VERSION ""

NS_ :

BS_:

BU_: DSAU vHS_M SHVU_RR DPSS AMP ICC RLPSM APSM RWPC RRHV RRPSM CGW_CCU APSS ATS RLHV FPM RDC PSM ASAU

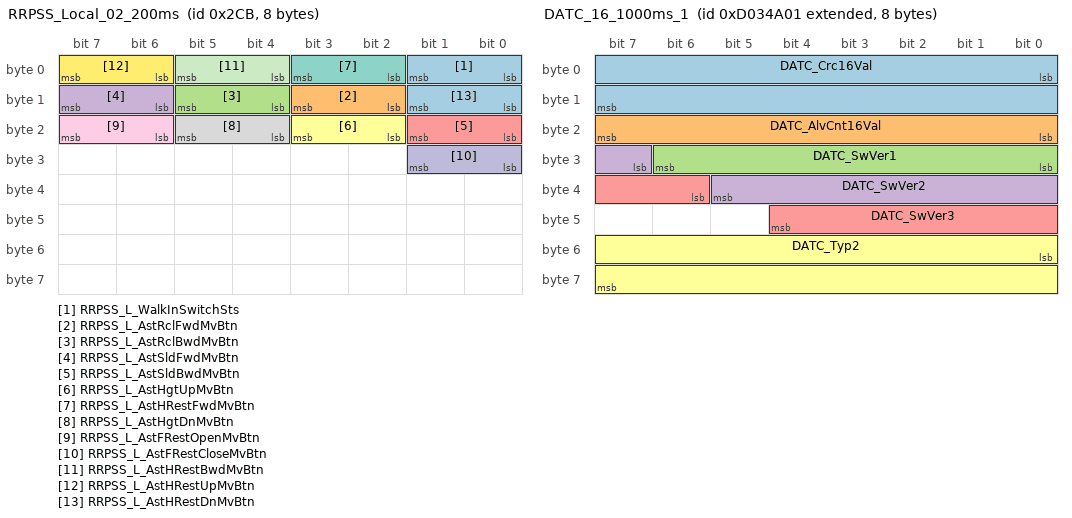
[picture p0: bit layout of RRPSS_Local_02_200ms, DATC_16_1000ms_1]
BO_ 715 RRPSS_Local_02_200ms: 8 RLPSM
 SG_ RRPSS_L_WalkInSwitchSts : 0|2@1+ (1,0) [0|0] ""  APSM
 SG_ RRPSS_L_AstRclFwdMvBtn : 10|2@1+ (1,0) [0|0] ""  APSM
 SG_ RRPSS_L_AstRclBwdMvBtn : 12|2@1+ (1,0) [0|0] ""  APSM
 SG_ RRPSS_L_AstSldFwdMvBtn : 14|2@1+ (1,0) [0|0] ""  APSM
 SG_ RRPSS_L_AstSldBwdMvBtn : 16|2@1+ (1,0) [0|0] ""  APSM
 SG_ RRPSS_L_AstHgtUpMvBtn : 18|2@1+ (1,0) [0|0] ""  APSM
 SG_ RRPSS_L_AstHRestFwdMvBtn : 2|2@1+ (1,0) [0|0] ""  APSM
 SG_ RRPSS_L_AstHgtDnMvBtn : 20|2@1+ (1,0) [0|0] ""  APSM
 SG_ RRPSS_L_AstFRestOpenMvBtn : 22|2@1+ (1,0) [0|0] ""  APSM
 SG_ RRPSS_L_AstFRestCloseMvBtn : 24|2@1+ (1,0) [0|0] ""  APSM
 SG_ RRPSS_L_AstHRestBwdMvBtn : 4|2@1+ (1,0) [0|0] ""  APSM
 SG_ RRPSS_L_AstHRestUpMvBtn : 6|2@1+ (1,0) [0|0] ""  APSM
 SG_ RRPSS_L_AstHRestDnMvBtn : 8|2@1+ (1,0) [0|0] ""  APSM

BO_ 2470762497 HU_GW_PE_01_1: 8 CGW_CCU
 SG_ HU_DistanceUnit : 0|2@1+ (1,0) [0|0] ""  Vector__XXX
 SG_ HU_ThemeType : 10|6@1+ (1,0) [0|0] ""  ATS
 SG_ HU_MicActivity : 17|2@1+ (1,0) [0|0] ""  Vector__XXX
 SG_ HU_Scheduled_Setting : 2|4@1+ (1,0) [0|0] ""  Vector__XXX
 SG_ AVN_RSPA_ModeSelect : 20|4@1+ (1,0) [0|0] ""  Vector__XXX
 SG_ CF_HU_GPSFlt : 24|2@1+ (1,0) [0|0] ""  Vector__XXX
 SG_ AVN_RSPA_CancelInput : 26|2@1+ (1,0) [0|3] ""  Vector__XXX
 SG_ AVN_RSPA_ModeSetStat : 28|4@1+ (1,0) [0|0] ""  Vector__XXX
 SG_ CAM_Request : 33|3@1+ (1,0) [0|0] ""  Vector__XXX
 SG_ HU_TempUnit : 36|2@1+ (1,0) [0|0] ""  Vector__XXX
 SG_ AVN_RSPA_Disp_Rdy : 38|2@1+ (1,0) [0|0] ""  Vector__XXX
 SG_ CF_AVN_ProfileIDRValue : 40|4@1+ (1,0) [0|0] ""  RWPC,PSM
 SG_ HazardFromHUSVM : 44|2@1+ (1,0) [0|0] ""  Vector__XXX
 SG_ OMUOSMirCtrl : 46|2@1+ (1,0) [0|0] ""  Vector__XXX
 SG_ AVN_PDW_Input : 49|2@1+ (1,0) [0|3] ""  Vector__XXX
 SG_ AVN_RSPA_Input : 51|2@1+ (1,0) [0|3] ""  Vector__XXX
 SG_ AVN_ParkingSW : 53|3@1+ (1,0) [0|0] ""  Vector__XXX
 SG_ OTAUIStatus : 56|2@1+ (1,0) [0|0] ""  Vector__XXX
 SG_ C_TeleActiveStatus : 58|2@1+ (1,0) [0|0] ""  Vector__XXX
 SG_ HU_AliveStatus : 6|2@1+ (1,0) [0|0] ""  DSAU
 SG_ C_MtnAlertClu : 60|2@1+ (1,0) [0|0] ""  Vector__XXX
 SG_ HU_RTCCheck : 62|2@1+ (1,0) [0|0] ""  Vector__XXX
 SG_ C_SMKBindRequest : 8|2@1+ (1,0) [0|0] ""  Vector__XXX

BO_ 2458167297 HU_USM_E_01_1: 8 CGW_CCU
 SG_ CF_AVN_FCANValueSet : 0|3@1+ (1,0) [0|0] ""  Vector__XXX
 SG_ CF_AVN_DAWModeNValueSet : 11|3@1+ (1,0) [0|0] ""  Vector__XXX
 SG_ CF_AVN_HDANValueSet : 14|2@1+ (1,0) [0|0] ""  Vector__XXX
 SG_ CF_AVN_BCWNValueSet : 16|2@1+ (1,0) [0|0] ""  Vector__XXX
 SG_ CF_AVN_NSCCCamNValueSet : 20|2@1+ (1,0) [0|0] ""  Vector__XXX
 SG_ CF_AVN_ProximitySesnsorSet : 22|2@1+ (1,0) [0|0] ""  Vector__XXX
 SG_ CF_AVN_BCANValueSet : 24|3@1+ (1,0) [0|0] ""  Vector__XXX
 SG_ CF_AVN_ISLWNValueSet : 27|2@1+ (1,0) [0|0] ""  Vector__XXX
 SG_ CF_AVN_WarningTimingNValueSet : 29|3@1+ (1,0) [0|0] ""  ICC
 SG_ CF_AVN_LFANValueSet : 3|2@1+ (1,0) [0|0] ""  Vector__XXX
 SG_ CF_AVN_NCC_USM_set : 32|2@1+ (1,0) [0|0] ""  Vector__XXX
 SG_ CF_AVN_TirePressUnitNValueSet : 34|3@1+ (1,0) [0|0] ""  Vector__XXX
 SG_ CF_AVN_PCANValueSet : 37|3@1+ (1,0) [0|0] ""  Vector__XXX
 SG_ CF_AVN_TunnelClimateNvalueSet : 40|2@1+ (1,0) [0|0] ""  Vector__XXX
 SG_ CF_AVN_NSCCCrvNValueSet : 42|2@1+ (1,0) [0|0] ""  Vector__XXX
 SG_ CF_AVN_BCWSndWanNValueSet : 44|2@1+ (1,0) [0|0] ""  Vector__XXX
 SG_ CF_AVN_RCCWNValueSet : 46|2@1+ (1,0) [0|0] ""  Vector__XXX
 SG_ CF_AVN_LkaModeNValueSet : 49|3@1+ (1,0) [0|0] ""  Vector__XXX
 SG_ CF_AVN_PasSpkrLvNValueSet : 5|3@1+ (1,0) [0|0] ""  Vector__XXX
 SG_ CF_AVN_PDWAutoOnNValueSet : 52|2@1+ (1,0) [0|0] ""  Vector__XXX
 SG_ C_TempUnit : 59|2@1+ (1,0) [0|0] ""  Vector__XXX
 SG_ CF_AVN_AdasVolumeNValueSet : 61|3@1+ (1,0) [0|0] ""  Vector__XXX
 SG_ CF_AVN_SCCDrvModeNValueSet : 8|3@1+ (1,0) [0|0] ""  Vector__XXX

BO_ 2365803012 DATC_16_1000ms_4: 8 CGW_CCU

BO_ 2365803011 DATC_16_1000ms_3: 8 CGW_CCU

BO_ 2365803010 DATC_16_1000ms_2: 8 CGW_CCU

BO_ 2563126017 HU_AMP_E_04_1: 8 CGW_CCU
 SG_ AMP_EngASDMasterGain : 0|5@1+ (0.5,-8) [-6|6] ""  AMP
 SG_ AMP_Beep1Frequency : 8|16@1+ (1,0) [0|0] "Hz"  AMP

BO_ 2365803009 DATC_16_1000ms_1: 8 CGW_CCU
 SG_ DATC_Crc16Val : 0|16@1+ (1,0) [0|0] ""  Vector__XXX
 SG_ DATC_AlvCnt16Val : 16|8@1+ (1,0) [0|0] ""  Vector__XXX
 SG_ DATC_SwVer1 : 24|7@1+ (1,0) [0|0] ""  Vector__XXX
 SG_ DATC_SwVer2 : 31|7@1+ (1,0) [0|0] ""  Vector__XXX
 SG_ DATC_SwVer3 : 38|7@1+ (1,0) [0|0] ""  Vector__XXX
 SG_ DATC_Typ2 : 48|16@1+ (1,0) [0|0] ""  ATS

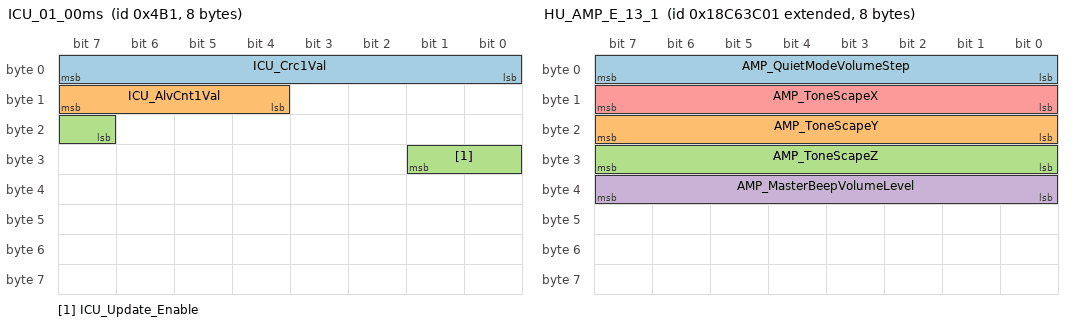
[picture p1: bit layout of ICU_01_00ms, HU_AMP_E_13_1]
BO_ 1201 ICU_01_00ms: 8 CGW_CCU
 SG_ ICU_Crc1Val : 0|8@1+ (1,0) [0|0] ""  vHS_M
 SG_ ICU_AlvCnt1Val : 12|4@1+ (1,0) [0|0] ""  Vector__XXX
 SG_ ICU_Update_Enable : 23|3@1+ (1,0) [0|0] ""  Vector__XXX

BO_ 2563128321 HU_AMP_E_13_1: 8 CGW_CCU
 SG_ AMP_QuietModeVolumeStep : 0|8@1+ (1,0) [0|0] ""  Vector__XXX
 SG_ AMP_ToneScapeY : 16|8@1+ (1,0) [0|0] ""  AMP
 SG_ AMP_ToneScapeZ : 24|8@1+ (1,0) [0|0] ""  AMP
 SG_ AMP_MasterBeepVolumeLevel : 32|8@1+ (1,0) [0|0] ""  AMP
 SG_ AMP_ToneScapeX : 8|8@1+ (1,0) [0|0] ""  AMP

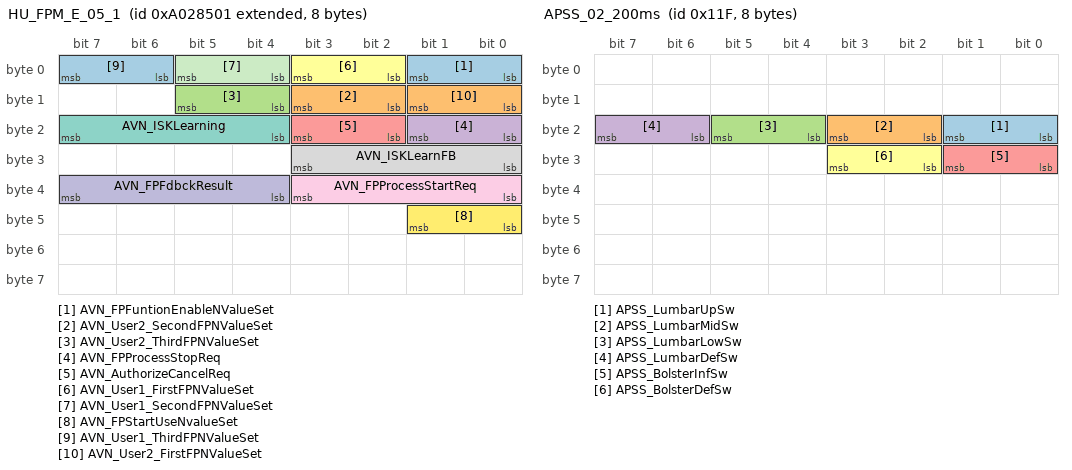
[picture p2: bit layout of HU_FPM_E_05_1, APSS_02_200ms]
BO_ 2315420929 HU_FPM_E_05_1: 8 CGW_CCU
 SG_ AVN_FPFuntionEnableNValueSet : 0|2@1+ (1,0) [0|0] ""  FPM
 SG_ AVN_User2_SecondFPNValueSet : 10|2@1+ (1,0) [0|0] ""  FPM
 SG_ AVN_User2_ThirdFPNValueSet : 12|2@1+ (1,0) [0|0] ""  FPM
 SG_ AVN_FPProcessStopReq : 16|2@1+ (1,0) [0|0] ""  FPM
 SG_ AVN_AuthorizeCancelReq : 18|2@1+ (1,0) [0|0] ""  FPM
 SG_ AVN_User1_FirstFPNValueSet : 2|2@1+ (1,0) [0|0] ""  FPM
 SG_ AVN_ISKLearning : 20|4@1+ (1,0) [0|0] ""  FPM
 SG_ AVN_ISKLearnFB : 24|4@1+ (1,0) [0|0] ""  FPM
 SG_ AVN_FPProcessStartReq : 32|4@1+ (1,0) [0|0] ""  FPM
 SG_ AVN_FPFdbckResult : 36|4@1+ (1,0) [0|0] ""  FPM
 SG_ AVN_User1_SecondFPNValueSet : 4|2@1+ (1,0) [0|0] ""  FPM
 SG_ AVN_FPStartUseNvalueSet : 40|2@1+ (1,0) [0|0] ""  FPM
 SG_ AVN_User1_ThirdFPNValueSet : 6|2@1+ (1,0) [0|0] ""  FPM
 SG_ AVN_User2_FirstFPNValueSet : 8|2@1+ (1,0) [0|0] ""  FPM

BO_ 2470762241 HU_Car_PE_01_1: 8 CGW_CCU
 SG_ HU_VehiclePwr : 4|4@1+ (1,0) [0|0] ""  AMP
 SG_ HU_BtnShowReq : 8|3@1+ (1,0) [0|0] ""  Vector__XXX

BO_ 287 APSS_02_200ms: 8 APSS
 SG_ APSS_LumbarUpSw : 16|2@1+ (1,0) [0|0] ""  ASAU,CGW_CCU
 SG_ APSS_LumbarMidSw : 18|2@1+ (1,0) [0|0] ""  ASAU,CGW_CCU
 SG_ APSS_LumbarLowSw : 20|2@1+ (1,0) [0|0] ""  ASAU,CGW_CCU
 SG_ APSS_LumbarDefSw : 22|2@1+ (1,0) [0|0] ""  ASAU,CGW_CCU
 SG_ APSS_BolsterInfSw : 24|2@1+ (1,0) [0|0] ""  ASAU,CGW_CCU
 SG_ APSS_BolsterDefSw : 26|2@1+ (1,0) [0|0] ""  ASAU,CGW_CCU

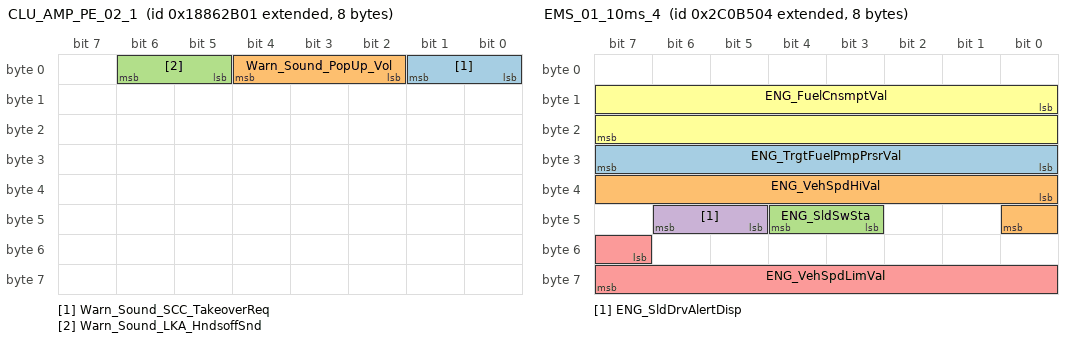
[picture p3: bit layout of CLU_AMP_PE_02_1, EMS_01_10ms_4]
BO_ 2558929665 CLU_AMP_PE_02_1: 8 CGW_CCU
 SG_ Warn_Sound_SCC_TakeoverReq : 0|2@1+ (1,0) [0|0] ""  AMP
 SG_ Warn_Sound_PopUp_Vol : 2|3@1+ (1,0) [0|0] ""  AMP
 SG_ Warn_Sound_LKA_HndsoffSnd : 5|2@1+ (1,0) [0|0] ""  AMP

BO_ 2193667332 EMS_01_10ms_4: 8 CGW_CCU
 SG_ ENG_TrgtFuelPmpPrsrVal : 24|8@1+ (3.137254902,0) [0|0] "kPa"  Vector__XXX
 SG_ ENG_VehSpdHiVal : 32|9@1+ (1,0) [0|0] "km/h"  AMP
 SG_ ENG_SldSwSta : 43|2@1+ (1,0) [0|0] ""  Vector__XXX
 SG_ ENG_SldDrvAlertDisp : 45|2@1+ (1,0) [0|0] ""  Vector__XXX
 SG_ ENG_VehSpdLimVal : 55|9@1+ (1,0) [0|0] "km/h"  Vector__XXX
 SG_ ENG_FuelCnsmptVal : 8|16@1+ (0.128,0) [0|0] "ul"  Vector__XXX

BO_ 2193667331 EMS_01_10ms_3: 8 CGW_CCU
 SG_ ENG_TrgtIdleRpmVal : 0|8@1+ (10,0) [0|0] "rpm"  Vector__XXX
 SG_ ENG_GearShftDnDis : 10|2@1+ (1,0) [0|0] ""  Vector__XXX
 SG_ ENG_DsrGearPosDis : 12|4@1+ (1,0) [0|0] ""  Vector__XXX
 SG_ ENG_SldFuncSta : 16|2@1+ (1,0) [0|0] ""  Vector__XXX
 SG_ ENG_SldActnSta : 18|2@1+ (1,0) [0|0] ""  Vector__XXX
 SG_ ENG_FuelTnkPrsrSta : 20|2@1+ (1,0) [0|0] ""  Vector__XXX
 SG_ ENG_IsgBzrReq : 22|2@1+ (1,0) [0|0] ""  Vector__XXX
 SG_ ENG_IsgFuelCnsmptDis : 24|2@1+ (1,0) [0|0] ""  Vector__XXX
 SG_ ENG_FuelCapOpnSta : 26|2@1+ (1,0) [0|0] ""  Vector__XXX
 SG_ ENG_EcoDrvActvSta : 28|2@1+ (1,0) [0|0] ""  Vector__XXX
 SG_ ENG_EngRunSta : 30|2@1+ (1,0) [0|0] ""  Vector__XXX
 SG_ ENG_Isg2Sta : 32|2@1+ (2,0) [0|0] ""  Vector__XXX
 SG_ ENG_IgnOnSta : 34|2@1+ (1,0) [0|0] ""  Vector__XXX
 SG_ ENG_Ack4TcsSta : 36|2@1+ (1,0) [0|0] ""  Vector__XXX
 SG_ ENG_FuelCutOffSta : 38|2@1+ (1,0) [0|0] ""  Vector__XXX
 SG_ ENG_CrctTqSta : 40|2@1+ (1,0) [0|0] ""  Vector__XXX
 SG_ ENG_AirCompRlySta : 42|2@1+ (1,0) [0|0] ""  Vector__XXX
 SG_ ENG_LnchCntrlSta : 45|3@1+ (1,0) [0|0] ""  Vector__XXX
 SG_ ENG_EngSpdVal : 48|16@1+ (0.25,0) [0|0] "rpm"  AMP
 SG_ ENG_GearShftUpDis : 8|2@1+ (1,0) [0|0] ""  Vector__XXX

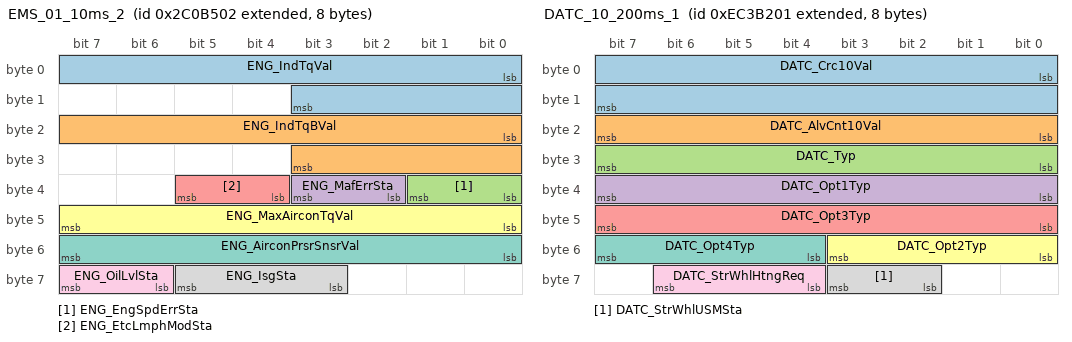
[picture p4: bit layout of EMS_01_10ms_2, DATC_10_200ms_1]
BO_ 2193667330 EMS_01_10ms_2: 8 CGW_CCU
 SG_ ENG_IndTqVal : 0|12@1- (1,0) [0|0] "Nm"  AMP
 SG_ ENG_IndTqBVal : 16|12@1- (1,0) [0|0] "Nm"  Vector__XXX
 SG_ ENG_EngSpdErrSta : 32|2@1+ (1,0) [0|0] ""  Vector__XXX
 SG_ ENG_MafErrSta : 34|2@1+ (1,0) [0|0] ""  Vector__XXX
 SG_ ENG_EtcLmphModSta : 36|2@1+ (1,0) [0|0] ""  Vector__XXX
 SG_ ENG_MaxAirconTqVal : 40|8@1+ (0.2,0) [0|0] "Nm"  Vector__XXX
 SG_ ENG_AirconPrsrSnsrVal : 48|8@1+ (125,0) [0|0] "hPa"  Vector__XXX
 SG_ ENG_IsgSta : 59|3@1+ (1,0) [0|0] ""  PSM,APSM,RLPSM,RRPSM,RLHV,RRHV,SHVU_RR,DPSS
 SG_ ENG_OilLvlSta : 62|2@1+ (1,0) [0|0] ""  Vector__XXX

BO_ 2395189761 DATC_10_200ms_1: 8 CGW_CCU
 SG_ DATC_Crc10Val : 0|16@1+ (1,0) [0|0] ""  Vector__XXX
 SG_ DATC_AlvCnt10Val : 16|8@1+ (1,0) [0|0] ""  Vector__XXX
 SG_ DATC_Typ : 24|8@1+ (1,0) [0|0] ""  RLHV,RRHV,AMP,ATS
 SG_ DATC_Opt1Typ : 32|8@1+ (1,0) [0|0] ""  ATS
 SG_ DATC_Opt3Typ : 40|8@1+ (1,0) [0|0] ""  ATS
 SG_ DATC_Opt2Typ : 48|4@1+ (1,0) [0|0] ""  ATS
 SG_ DATC_Opt4Typ : 52|4@1+ (1,0) [0|0] ""  ATS
 SG_ DATC_StrWhlUSMSta : 58|2@1+ (1,0) [0|0] ""  SHVU_RR
 SG_ DATC_StrWhlHtngReq : 60|3@1+ (1,0) [0|0] ""  Vector__XXX

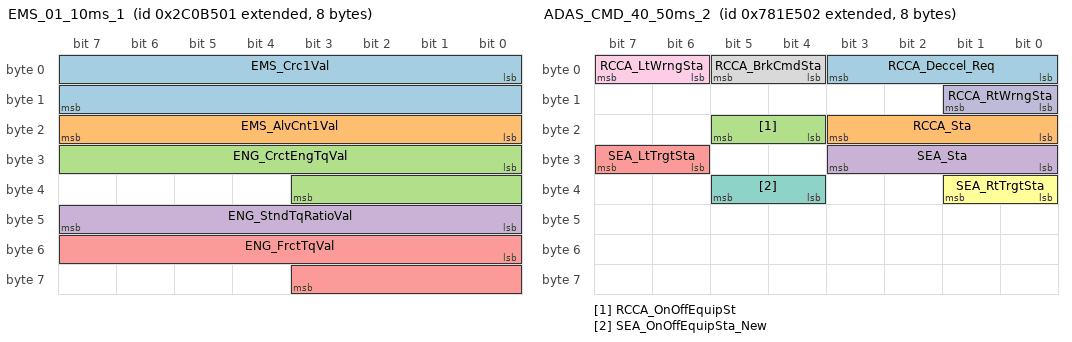
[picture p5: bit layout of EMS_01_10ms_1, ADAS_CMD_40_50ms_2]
BO_ 2193667329 EMS_01_10ms_1: 8 CGW_CCU
 SG_ EMS_Crc1Val : 0|16@1+ (1,0) [0|0] ""  Vector__XXX
 SG_ EMS_AlvCnt1Val : 16|8@1+ (1,0) [0|0] ""  Vector__XXX
 SG_ ENG_CrctEngTqVal : 24|12@1- (1,0) [0|0] "Nm"  Vector__XXX
 SG_ ENG_StndTqRatioVal : 40|8@1+ (0.0078,0) [0|0] ""  Vector__XXX
 SG_ ENG_FrctTqVal : 48|12@1- (1,0) [0|0] "Nm"  Vector__XXX

BO_ 2273436930 ADAS_CMD_40_50ms_2: 8 CGW_CCU
 SG_ RCCA_Deccel_Req : 0|4@1+ (0.04,0) [0|0] "g"  Vector__XXX
 SG_ RCCA_Sta : 16|4@1+ (1,0) [0|0] ""  Vector__XXX
 SG_ RCCA_OnOffEquipSt : 20|2@1+ (1,0) [0|0] ""  Vector__XXX
 SG_ SEA_Sta : 24|4@1+ (1,0) [0|0] ""  Vector__XXX
 SG_ SEA_LtTrgtSta : 30|2@1+ (1,0) [0|0] ""  AMP
 SG_ SEA_RtTrgtSta : 32|2@1+ (1,0) [0|0] ""  AMP
 SG_ SEA_OnOffEquipSta_New : 36|2@1+ (1,0) [0|0] ""  Vector__XXX
 SG_ RCCA_BrkCmdSta : 4|2@1+ (1,0) [0|0] ""  Vector__XXX
 SG_ RCCA_LtWrngSta : 6|2@1+ (1,0) [0|0] ""  Vector__XXX
 SG_ RCCA_RtWrngSta : 8|2@1+ (1,0) [0|0] ""  Vector__XXX

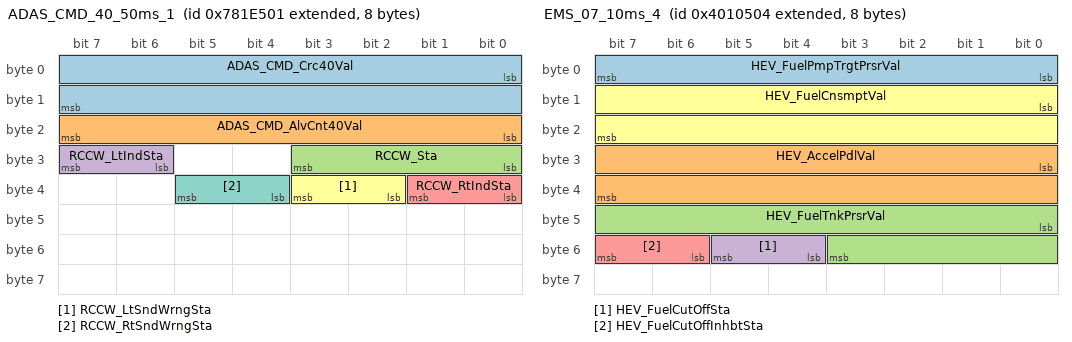
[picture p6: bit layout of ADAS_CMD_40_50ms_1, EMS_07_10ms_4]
BO_ 2273436929 ADAS_CMD_40_50ms_1: 8 CGW_CCU
 SG_ ADAS_CMD_Crc40Val : 0|16@1+ (1,0) [0|0] ""  Vector__XXX
 SG_ ADAS_CMD_AlvCnt40Val : 16|8@1+ (1,0) [0|0] ""  Vector__XXX
 SG_ RCCW_Sta : 24|4@1+ (1,0) [0|0] ""  Vector__XXX
 SG_ RCCW_LtIndSta : 30|2@1+ (1,0) [0|0] ""  Vector__XXX
 SG_ RCCW_RtIndSta : 32|2@1+ (1,0) [0|0] ""  Vector__XXX
 SG_ RCCW_LtSndWrngSta : 34|2@1+ (1,0) [0|0] ""  AMP
 SG_ RCCW_RtSndWrngSta : 36|2@1+ (1,0) [0|0] ""  AMP

BO_ 2214659332 EMS_07_10ms_4: 8 CGW_CCU
 SG_ HEV_FuelPmpTrgtPrsrVal : 0|8@1+ (3.137254902,0) [0|0] "kPa"  Vector__XXX
 SG_ HEV_AccelPdlVal : 24|16@1+ (0.3906,0) [0|0] "%"  Vector__XXX
 SG_ HEV_FuelTnkPrsrVal : 40|12@1+ (0.17094,-200) [0|0] "hPa"  Vector__XXX
 SG_ HEV_FuelCutOffSta : 52|2@1+ (1,0) [0|0] ""  Vector__XXX
 SG_ HEV_FuelCutOffInhbtSta : 54|2@1+ (1,0) [0|0] ""  Vector__XXX
 SG_ HEV_FuelCnsmptVal : 8|16@1+ (0.128,0) [0|0] "ul"  Vector__XXX

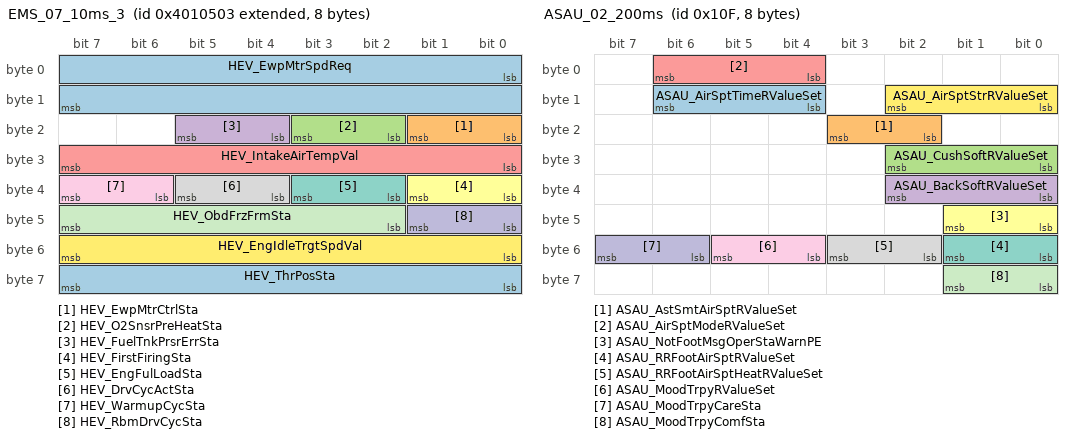
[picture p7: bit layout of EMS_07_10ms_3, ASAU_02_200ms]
BO_ 2214659331 EMS_07_10ms_3: 8 CGW_CCU
 SG_ HEV_EwpMtrSpdReq : 0|16@1+ (1,0) [0|0] "rpm"  Vector__XXX
 SG_ HEV_EwpMtrCtrlSta : 16|2@1+ (1,0) [0|0] ""  Vector__XXX
 SG_ HEV_O2SnsrPreHeatSta : 18|2@1+ (1,0) [0|0] ""  Vector__XXX
 SG_ HEV_FuelTnkPrsrErrSta : 20|2@1+ (1,0) [0|0] ""  Vector__XXX
 SG_ HEV_IntakeAirTempVal : 24|8@1+ (0.75,-48) [0|0] "℃"  Vector__XXX
 SG_ HEV_FirstFiringSta : 32|2@1+ (1,0) [0|0] ""  Vector__XXX
 SG_ HEV_EngFulLoadSta : 34|2@1+ (1,0) [0|0] ""  Vector__XXX
 SG_ HEV_DrvCycActSta : 36|2@1+ (1,0) [0|0] ""  Vector__XXX
 SG_ HEV_WarmupCycSta : 38|2@1+ (1,0) [0|0] ""  Vector__XXX
 SG_ HEV_RbmDrvCycSta : 40|2@1+ (1,0) [0|0] ""  Vector__XXX
 SG_ HEV_ObdFrzFrmSta : 42|6@1+ (1,0) [0|0] ""  Vector__XXX
 SG_ HEV_EngIdleTrgtSpdVal : 48|8@1+ (10,0) [0|0] "rpm"  Vector__XXX
 SG_ HEV_ThrPosSta : 56|8@1+ (0.4694835681,-15.0234741784) [0|0] "%"  Vector__XXX

BO_ 271 ASAU_02_200ms: 8 ASAU
 SG_ ASAU_AirSptTimeRValueSet : 12|3@1+ (1,0) [0|0] ""  CGW_CCU
 SG_ ASAU_AstSmtAirSptRValueSet : 18|2@1+ (1,0) [0|0] ""  CGW_CCU
 SG_ ASAU_CushSoftRValueSet : 24|3@1+ (1,0) [0|0] ""  CGW_CCU
 SG_ ASAU_BackSoftRValueSet : 32|3@1+ (1,0) [0|0] ""  CGW_CCU
 SG_ ASAU_AirSptModeRValueSet : 4|3@1+ (1,0) [0|0] ""  CGW_CCU
 SG_ ASAU_NotFootMsgOperStaWarnPE : 40|2@1+ (1,0) [0|0] ""  ATS
 SG_ ASAU_RRFootAirSptRValueSet : 48|2@1+ (1,0) [0|0] ""  APSM,ATS,CGW_CCU
 SG_ ASAU_RRFootAirSptHeatRValueSet : 50|2@1+ (1,0) [0|0] ""  APSM,ATS
 SG_ ASAU_MoodTrpyRValueSet : 52|2@1+ (1,0) [0|0] ""  CGW_CCU
 SG_ ASAU_MoodTrpyCareSta : 54|2@1+ (1,0) [0|0] ""  CGW_CCU
 SG_ ASAU_MoodTrpyComfSta : 56|2@1+ (1,0) [0|0] ""  CGW_CCU
 SG_ ASAU_AirSptStrRValueSet : 8|3@1+ (1,0) [0|0] ""  CGW_CCU

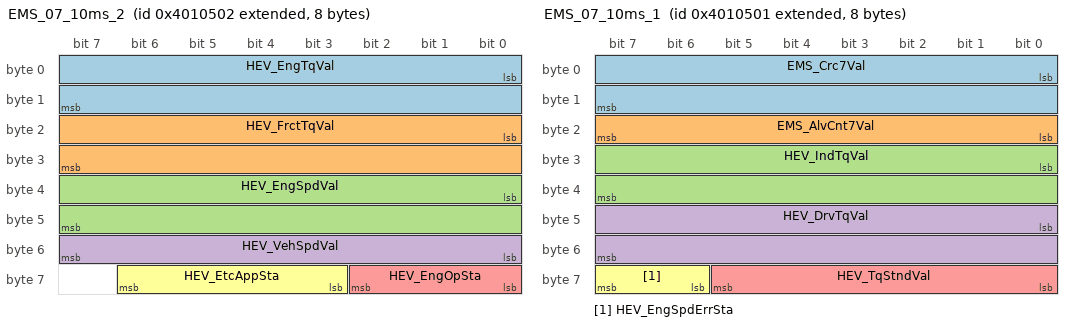
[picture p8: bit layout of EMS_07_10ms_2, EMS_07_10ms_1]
BO_ 2214659330 EMS_07_10ms_2: 8 CGW_CCU
 SG_ HEV_EngTqVal : 0|16@1+ (0.3906,0) [0|0] "%"  Vector__XXX
 SG_ HEV_FrctTqVal : 16|16@1+ (0.3906,0) [0|0] "%"  Vector__XXX
 SG_ HEV_EngSpdVal : 32|16@1+ (0.25,0) [0|0] "rpm"  Vector__XXX
 SG_ HEV_VehSpdVal : 48|8@1+ (1,0) [0|0] "km/h"  Vector__XXX
 SG_ HEV_EngOpSta : 56|3@1+ (1,0) [0|0] ""  SHVU_RR
 SG_ HEV_EtcAppSta : 59|4@1+ (1,0) [0|0] ""  Vector__XXX

BO_ 2214659329 EMS_07_10ms_1: 8 CGW_CCU
 SG_ EMS_Crc7Val : 0|16@1+ (1,0) [0|0] ""  Vector__XXX
 SG_ EMS_AlvCnt7Val : 16|8@1+ (1,0) [0|0] ""  Vector__XXX
 SG_ HEV_IndTqVal : 24|16@1+ (0.3906,0) [0|0] "%"  Vector__XXX
 SG_ HEV_DrvTqVal : 40|16@1+ (0.390625,0) [0|0] "%"  Vector__XXX
 SG_ HEV_TqStndVal : 56|6@1+ (10,0) [0|0] "Nm"  Vector__XXX
 SG_ HEV_EngSpdErrSta : 62|2@1+ (1,0) [0|0] ""  Vector__XXX

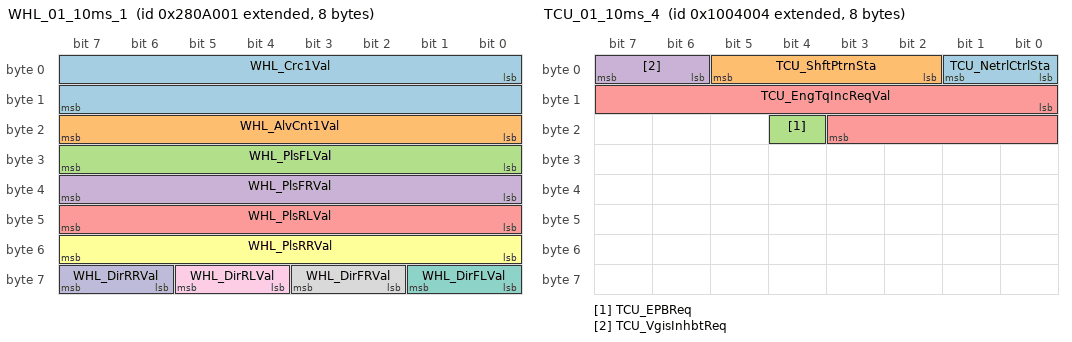
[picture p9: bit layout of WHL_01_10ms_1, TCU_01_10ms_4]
BO_ 2189467649 WHL_01_10ms_1: 8 CGW_CCU
 SG_ WHL_Crc1Val : 0|16@1+ (1,0) [0|0] ""  Vector__XXX
 SG_ WHL_AlvCnt1Val : 16|8@1+ (1,0) [0|0] ""  Vector__XXX
 SG_ WHL_PlsFLVal : 24|8@1+ (0.5,0) [0|0] "pulse count"  Vector__XXX
 SG_ WHL_PlsFRVal : 32|8@1+ (0.5,0) [0|0] "pulse count"  Vector__XXX
 SG_ WHL_PlsRLVal : 40|8@1+ (0.5,0) [0|0] "pulse count"  Vector__XXX
 SG_ WHL_PlsRRVal : 48|8@1+ (0.5,0) [0|0] "pulse count"  Vector__XXX
 SG_ WHL_DirFLVal : 56|2@1+ (1,0) [0|0] ""  Vector__XXX
 SG_ WHL_DirFRVal : 58|2@1+ (1,0) [0|0] ""  Vector__XXX
 SG_ WHL_DirRLVal : 60|2@1+ (1,0) [0|0] ""  Vector__XXX
 SG_ WHL_DirRRVal : 62|2@1+ (1,0) [0|0] ""  Vector__XXX

BO_ 2164277252 TCU_01_10ms_4: 8 CGW_CCU
 SG_ TCU_NetrlCtrlSta : 0|2@1+ (1,0) [0|0] ""  Vector__XXX
 SG_ TCU_ShftPtrnSta : 2|4@1+ (1,0) [0|0] ""  Vector__XXX
 SG_ TCU_EPBReq : 20|1@1+ (1,0) [0|0] ""  Vector__XXX
 SG_ TCU_VgisInhbtReq : 6|2@1+ (1,0) [0|0] ""  Vector__XXX
 SG_ TCU_EngTqIncReqVal : 8|12@1- (1,0) [0|0] "Nm"  Vector__XXX

BO_ 2411985665 HU_MOOD_E_01_1: 8 CGW_CCU
 SG_ HU_MoodTherapyDrSeat : 0|2@1+ (1,0) [0|0] ""  DSAU
 SG_ HU_VitalityFragrance : 10|2@1+ (1,0) [0|0] ""  Vector__XXX
 SG_ HU_VitalityCurtain : 12|2@1+ (1,0) [0|0] ""  RDC
 SG_ HU_DelightMoodLamp : 14|2@1+ (1,0) [0|0] ""  Vector__XXX
 SG_ HU_DelightFragrance : 16|2@1+ (1,0) [0|0] ""  Vector__XXX
 SG_ HU_DelightCurtain : 18|2@1+ (1,0) [0|0] ""  RDC
 SG_ HU_MoodTherapyPsSeat : 2|2@1+ (1,0) [0|0] ""  ASAU
 SG_ HU_CareMoodLamp : 20|2@1+ (1,0) [0|0] ""  Vector__XXX
 SG_ HU_CareFragrance : 22|2@1+ (1,0) [0|0] ""  Vector__XXX
 SG_ HU_CareMassage : 24|2@1+ (1,0) [0|0] ""  RLPSM,DSAU,ASAU
 SG_ HU_CareCurtain : 26|2@1+ (1,0) [0|0] ""  RDC
 SG_ HU_ComfortMoodLamp : 28|2@1+ (1,0) [0|0] ""  Vector__XXX
 SG_ HU_ComfortFragrance : 30|2@1+ (1,0) [0|0] ""  Vector__XXX
 SG_ HU_ComfortMassage : 32|2@1+ (1,0) [0|0] ""  RLPSM,DSAU,ASAU
 SG_ HU_ComfortCurtain : 34|2@1+ (1,0) [0|0] ""  RDC
 SG_ HU_MoodTherapyMode : 36|3@1+ (1,0) [0|0] ""  RLPSM,RDC,DSAU,ASAU
 SG_ HU_MoodTherapyRlSeat : 4|2@1+ (1,0) [0|0] ""  RLPSM
 SG_ HU_MoodTherapyRrSeat : 6|2@1+ (1,0) [0|0] ""  RLPSM
 SG_ HU_VitalityMoodLamp : 8|2@1+ (1,0) [0|0] ""  Vector__XXX

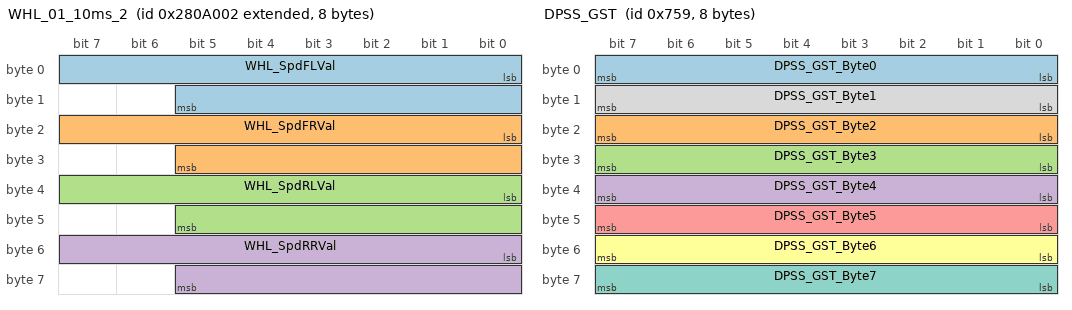
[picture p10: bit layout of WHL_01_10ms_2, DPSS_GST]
BO_ 2189467650 WHL_01_10ms_2: 8 CGW_CCU
 SG_ WHL_SpdFLVal : 0|14@1+ (0.03125,0) [0|0] "km^h"  AMP
 SG_ WHL_SpdFRVal : 16|14@1+ (0.03125,0) [0|0] "km^h"  AMP
 SG_ WHL_SpdRLVal : 32|14@1+ (0.03125,0) [0|0] "km^h"  Vector__XXX
 SG_ WHL_SpdRRVal : 48|14@1+ (0.03125,0) [0|0] "km^h"  Vector__XXX

BO_ 1881 DPSS_GST: 8 DPSS
 SG_ DPSS_GST_Byte0 : 0|8@1+ (1,0) [0|0] ""  CGW_CCU
 SG_ DPSS_GST_Byte2 : 16|8@1+ (1,0) [0|0] ""  CGW_CCU
 SG_ DPSS_GST_Byte3 : 24|8@1+ (1,0) [0|0] ""  CGW_CCU
 SG_ DPSS_GST_Byte4 : 32|8@1+ (1,0) [0|0] ""  CGW_CCU
 SG_ DPSS_GST_Byte5 : 40|8@1+ (1,0) [0|0] ""  CGW_CCU
 SG_ DPSS_GST_Byte6 : 48|8@1+ (1,0) [0|0] ""  CGW_CCU
 SG_ DPSS_GST_Byte7 : 56|8@1+ (1,0) [0|0] ""  CGW_CCU
 SG_ DPSS_GST_Byte1 : 8|8@1+ (1,0) [0|0] ""  CGW_CCU

BO_ 2189467651 WHL_01_10ms_3: 8 CGW_CCU
 SG_ WHL_SpdCalParmtr : 8|9@1+ (0.5,200) [0|0] "mm"  Vector__XXX

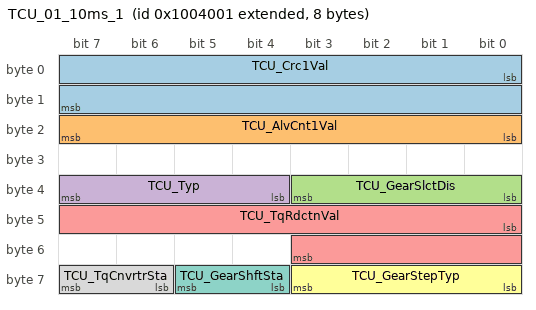
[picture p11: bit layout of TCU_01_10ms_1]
BO_ 2164277249 TCU_01_10ms_1: 8 CGW_CCU
 SG_ TCU_Crc1Val : 0|16@1+ (1,0) [0|0] ""  Vector__XXX
 SG_ TCU_AlvCnt1Val : 16|8@1+ (1,0) [0|0] ""  Vector__XXX
 SG_ TCU_GearSlctDis : 32|4@1+ (1,0) [0|0] ""  AMP,ICC
 SG_ TCU_Typ : 36|4@1+ (1,0) [0|0] ""  AMP
 SG_ TCU_TqRdctnVal : 40|12@1- (1,0) [0|0] "Nm"  AMP
 SG_ TCU_GearStepTyp : 56|4@1+ (1,0) [0|0] ""  Vector__XXX
 SG_ TCU_GearShftSta : 60|2@1+ (1,0) [0|0] ""  Vector__XXX
 SG_ TCU_TqCnvrtrSta : 62|2@1+ (1,0) [0|0] ""  Vector__XXX

BO_TX_BU_ 1881 : DPSS,vHS_M;
CM_ BO_ 2273436929 "[P] Periodic";
CM_ SG_ 2273436929 ADAS_CMD_Crc40Val "ADAS_CMD_CyclicRedundancyCheck40Value";
CM_ SG_ 2273436929 ADAS_CMD_AlvCnt40Val "ADAS_CMD_AliveCounter40Value";
CM_ SG_ 2273436929 RCCW_Sta "RCCW_Status ##2G##BCW - BCW11 - CF_RCCW_Stat";
CM_ SG_ 2273436929 RCCW_LtIndSta "RCCW_LeftIndicatorStatus ##2G##BCW - BCW11 - CF_RCCW_IndLeft";
CM_ SG_ 2273436929 RCCW_RtIndSta "RCCW_RightIndicatorStatus ##2G##BCW - BCW11 - CF_RCCW_IndRight";
CM_ SG_ 2273436929 RCCW_LtSndWrngSta "RCCW_LeftSoundWarningStatus ##2G##BCW - BCW11 - CF_RL_SndWan";
CM_ SG_ 2273436929 RCCW_RtSndWrngSta "RCCW_RightSoundWarningStatus ##2G##BCW - BCW11 - CF_RR_SndWan";
CM_ BO_ 2273436930 "[P] Periodic";
CM_ SG_ 2273436930 RCCA_Deccel_Req "RCCA_Deccel_Requirement ##2G##BCW - BCA11 - CF_RCCA_Decel_Req";
CM_ SG_ 2273436930 RCCA_Sta "RCCA_Status";
CM_ SG_ 2273436930 RCCA_OnOffEquipSt "RCCA_OnOffEquipmentStatus ##2G##BCW - BCW12 - CF_RCCA_USM";
CM_ SG_ 2273436930 SEA_Sta "SEA_Status";
CM_ SG_ 2273436930 SEA_LtTrgtSta "SEA_LeftWarningStatus ##2G##BCW - BCA11 - CF_SEA_Warn_Lh";
CM_ SG_ 2273436930 SEA_RtTrgtSta "SEA_RightWarningStatus ##2G##BCW - BCA11 - CF_SEA_Warn_Rh";
CM_ SG_ 2273436930 SEA_OnOffEquipSta_New "SEA_OnOffEquipmentStatus ##2G##BCW - BCW12 - CF_SEA_USM_NEW";
CM_ SG_ 2273436930 RCCA_BrkCmdSta "RCCA_BrakeCommandStatus ##2G##BCW - BCA11 - RCCA_Brake_Command";
CM_ SG_ 2273436930 RCCA_LtWrngSta "RCCA_LeftWarningStatus ##2G##BCW - BCA11 - CF_RCCA_WarnLh";
CM_ SG_ 2273436930 RCCA_RtWrngSta "RCCA_RightWarningStatus ##2G##BCW - BCA11 - CF_RCCA_WarnRh";
CM_ BO_ 287 "[PE] Periodic and On Event";
CM_ SG_ 287 APSS_LumbarUpSw "APSS_LumbarUpMoveSwitch";
CM_ SG_ 287 APSS_LumbarMidSw "APSS_LumbarMiddleSwitch";
CM_ SG_ 287 APSS_LumbarLowSw "APSS_LumbarLowerSwitch";
CM_ SG_ 287 APSS_LumbarDefSw "APSS_LumbarDeflationSwitch";
CM_ SG_ 287 APSS_BolsterInfSw "APSS_BolsterInflationSwitch";
CM_ SG_ 287 APSS_BolsterDefSw "APSS_BolsterDeflationSwitch";
CM_ BO_ 271 "[PE] Periodic and On Event";
CM_ SG_ 271 ASAU_AirSptTimeRValueSet "Air Support Time(Massage Time) USM R Value";
CM_ SG_ 271 ASAU_AstSmtAirSptRValueSet "Seat Smart Air Support Function USM R Value";
CM_ SG_ 271 ASAU_CushSoftRValueSet "Cushion Soft R Value";
CM_ SG_ 271 ASAU_BackSoftRValueSet "Back Soft USM R Value";
CM_ SG_ 271 ASAU_AirSptModeRValueSet "Air Support Mode(Massage Mode) USM R Value";
CM_ SG_ 271 ASAU_NotFootMsgOperStaWarnPE "Passenger Foot Massage Operation Disable Mode";
CM_ SG_ 271 ASAU_RRFootAirSptRValueSet "Foot Air Support USM R Value";
CM_ SG_ 271 ASAU_RRFootAirSptHeatRValueSet "Foot Air Support Heat USM R Value";
CM_ SG_ 271 ASAU_MoodTrpyRValueSet "Passenger Seat Mood Therapy R Value";
CM_ SG_ 271 ASAU_MoodTrpyCareSta "Passenger Seat Mood Therapy Care Mode R Value";
CM_ SG_ 271 ASAU_MoodTrpyComfSta "Passenger Seat Mood Therapy Comfort Mode R Value";
CM_ SG_ 271 ASAU_AirSptStrRValueSet "Air Support Strenth(Massage Strenth) USM R Value";
CM_ BO_ 2558929665 "[PE] Periodic and On Event";
CM_ SG_ 2558929665 Warn_Sound_SCC_TakeoverReq "This signal is transmitted from cluster to AMP for SCC TAKE OVER REQUSET SOUND";
CM_ SG_ 2558929665 Warn_Sound_PopUp_Vol "This signal is transmitted from cluster to AMP for 11 group cluster sound

0x0:Off
0x1:Red Pop-up(Collision)
0x2:Red Pop-up
0x3:Yellow Pop-up
0x4:White(Alarm) Pop-up
0x5:White(Feedback) Pop-up
0x6:Reserved
0x7:Invalid";
CM_ SG_ 2558929665 Warn_Sound_LKA_HndsoffSnd "This signal is transmitted from cluster to AMP for LKA HANDS OFF SOUND";
CM_ BO_ 2395189761 "[PE] Periodic and On Event";
CM_ SG_ 2395189761 DATC_Crc10Val "DATC_CyclicRedundancyCheck10Value";
CM_ SG_ 2395189761 DATC_AlvCnt10Val "DATC_AliveCounter10Value";
CM_ SG_ 2395189761 DATC_Typ "DATC_Type";
CM_ SG_ 2395189761 DATC_Opt1Typ "DATC_Option1Type";
CM_ SG_ 2395189761 DATC_Opt3Typ "DATC_Option3Type";
CM_ SG_ 2395189761 DATC_Opt2Typ "DATC_Option2Type";
CM_ SG_ 2395189761 DATC_Opt4Typ "HTR CONTROL OPTION";
CM_ SG_ 2395189761 DATC_StrWhlUSMSta "DATC_SteeringWheelUSMState";
CM_ SG_ 2395189761 DATC_StrWhlHtngReq "DATC_SteeringWheelHeatReq";
CM_ BO_ 2365803009 "[P] Periodic";
CM_ SG_ 2365803009 DATC_Crc16Val "DATC_CyclicRedundancyCheck16Value";
CM_ SG_ 2365803009 DATC_AlvCnt16Val "DATC_AliveCounter16Value";
CM_ SG_ 2365803009 DATC_SwVer1 "this signal indicates DATC Software Version to display on H_U";
CM_ SG_ 2365803009 DATC_SwVer2 "This signal indicates DATC software vertion to display on H_U";
CM_ SG_ 2365803009 DATC_Typ2 "DATC_Type2";
CM_ BO_ 2365803010 "[P] Periodic";
CM_ BO_ 2365803011 "[P] Periodic";
CM_ BO_ 2365803012 "[P] Periodic";
CM_ BO_ 1881 "[TP] Transport Protocol";
CM_ BO_ 2193667329 "[P] Periodic";
CM_ SG_ 2193667329 EMS_Crc1Val "EMS_CyclicRedundancyCheck1Value";
CM_ SG_ 2193667329 EMS_AlvCnt1Val "EMS_AliveCounter1Value";
CM_ SG_ 2193667329 ENG_CrctEngTqVal "ENG_CorrectedEngineTorqueValue ##2G##EMS - EMS11 - TQI_ACOR";
CM_ SG_ 2193667329 ENG_StndTqRatioVal "ENG_StandardTorqueRatioValue ##2G##EMS - EMS11 - RATIO_TQI_BAS_MAX_STND";
CM_ SG_ 2193667329 ENG_FrctTqVal "ENG_FrictionTorqueValue ##2G##EMS - EMS11 - TQFR";
CM_ BO_ 2193667330 "[P] Periodic";
CM_ SG_ 2193667330 ENG_IndTqVal "ENG_IndicatedTorqueValue ##2G##EMS - EMS11 - TQI";
CM_ SG_ 2193667330 ENG_IndTqBVal "ENG_IndicatedTorqueBValue ##2G##EMS - EMS_H12 - TQI_B";
CM_ SG_ 2193667330 ENG_EngSpdErrSta "ENG_EngineSpeedErrorStatus ##2G##EMS - EMS11 - F_N_ENG";
CM_ SG_ 2193667330 ENG_MafErrSta "ENG_MassAirFlowErrorStatus ##2G##EMS - EMS11 - F_SUB_TQI";
CM_ SG_ 2193667330 ENG_EtcLmphModSta "ENG_EtcLimphomeModeStatus ##2G##EMS - EMS_H12 - CF_Ems_EtcLimpMod";
CM_ SG_ 2193667330 ENG_MaxAirconTqVal "ENG_MaximumAirconTorqueValue ##2G##EMS - EMS_H12 - R_TqAcnApvC";
CM_ SG_ 2193667330 ENG_AirconPrsrSnsrVal "ENG_AirconPressureSensorValue ##2G##EMS - EMS_H12 - R_PAcnC";
CM_ SG_ 2193667330 ENG_IsgSta "ENG_IsgStatus ##2G##EMS - EMS_H12 - CF_Ems_IsgStat";
CM_ SG_ 2193667330 ENG_OilLvlSta "ENG_OilLevelStatus ##2G##EMS - EMS_H12 - CF_Ems_OilChg";
CM_ BO_ 2193667331 "[P] Periodic";
CM_ SG_ 2193667331 ENG_TrgtIdleRpmVal "ENG_TargetIdleRpmValue ##2G##EMS - EMS_H12 - R_NEngIdlTgC";
CM_ SG_ 2193667331 ENG_GearShftDnDis "ENG_GearShiftDownDisplay ##2G##EMS - EMS_H12 - CF_Ems_DownTarGr";
CM_ SG_ 2193667331 ENG_DsrGearPosDis "ENG_DesirableGearPositionDisplay ##2G##EMS - EMS_H12 - CF_Ems_DesCurGr";
CM_ SG_ 2193667331 ENG_SldFuncSta "ENG_SpeedLimitFunctionStatus ##2G##EMS - EMS_H12 - CF_Ems_SldAct";
CM_ SG_ 2193667331 ENG_SldActnSta "ENG_SpeedLimitActionStatus ##2G##EMS - EMS_H12 - CF_Ems_SldPosAct";
CM_ SG_ 2193667331 ENG_FuelTnkPrsrSta "ENG_FuelTankPressureStatus ##2G##EMS - EMS_H12 - CF_Ems_HPresStat";
CM_ SG_ 2193667331 ENG_IsgBzrReq "ENG_IsgBuzzerRequest ##2G##EMS - EMS_H12 - CF_Ems_IsgBuz";
CM_ SG_ 2193667331 ENG_IsgFuelCnsmptDis "ENG_IsgFuelConsumptionDisplay ##2G##EMS - EMS_H12 - CF_Ems_IdlStpFCO";
CM_ SG_ 2193667331 ENG_FuelCapOpnSta "ENG_FuelCapOpenStatus ##2G##EMS - EMS_H12 - CF_Ems_FCopen";
CM_ SG_ 2193667331 ENG_EcoDrvActvSta "ENG_EcoDriveActiveStatus ##2G##EMS - EMS_H12 - CF_Ems_ActEcoAct";
CM_ SG_ 2193667331 ENG_EngRunSta "ENG_EngineRunningStatus ##2G##EMS - EMS_H12 - CF_Ems_EngRunNorm";
CM_ SG_ 2193667331 ENG_Isg2Sta "ENG_Isg2Status ##2G##EMS - EMS_H12 - CF_Ems_IsgStat2";
CM_ SG_ 2193667331 ENG_IgnOnSta "ENG_IgnitionOnStatus ##2G##EMS - EMS11 - SWI_IGK";
CM_ SG_ 2193667331 ENG_Ack4TcsSta "ENG_AcknowledgeForTcsStatus ##2G##EMS - EMS11 - ACK_TCS";
CM_ SG_ 2193667331 ENG_FuelCutOffSta "ENG_FuelCutOffStatus ##2G##EMS - EMS11 - PUC_STAT";
CM_ SG_ 2193667331 ENG_CrctTqSta "ENG_CorrectedTorqueStatus ##2G##EMS - EMS11 - TQ_COR_STAT";
CM_ SG_ 2193667331 ENG_AirCompRlySta "ENG_AirCompressorRelayStatus ##2G##EMS - EMS11 - RLY_AC";
CM_ SG_ 2193667331 ENG_LnchCntrlSta "ENG_LaunchControlStatus";
CM_ SG_ 2193667331 ENG_EngSpdVal "ENG_EngineSpeedValue ##2G##EMS - EMS11 - N";
CM_ SG_ 2193667331 ENG_GearShftUpDis "ENG_GearShiftUpDisplay ##2G##EMS - EMS_H12 - CF_Ems_UpTarGr";
CM_ BO_ 2193667332 "[P] Periodic";
CM_ SG_ 2193667332 ENG_TrgtFuelPmpPrsrVal "ENG_TargetFuelPumpPressureValue ##2G##EMS - EMS20 - CF_Ems_PumpTPres";
CM_ SG_ 2193667332 ENG_VehSpdHiVal "ENG_VehicleSpeedHighValue";
CM_ SG_ 2193667332 ENG_SldSwSta "The status of Speed limiter function.";
CM_ SG_ 2193667332 ENG_SldDrvAlertDisp "The status of No Sld Engaged or Sld Disengaged.";
CM_ SG_ 2193667332 ENG_VehSpdLimVal "ENG_VehicleSpeedLimitValue ##2G##EMS - EMS_H12 - SLD_VS, EMS20-SLD_VS_EXT";
CM_ SG_ 2193667332 ENG_FuelCnsmptVal "ENG_FuelConsumptionValue ##2G##EMS - EMS20 - FCO";
CM_ BO_ 2214659329 "[P] Periodic";
CM_ SG_ 2214659329 EMS_Crc7Val "EMS_CyclicRedundancyCheck7Value";
CM_ SG_ 2214659329 EMS_AlvCnt7Val "EMS_AliveCounter7Value";
CM_ SG_ 2214659329 HEV_IndTqVal "HEV_IndicatedTorqueValue";
CM_ SG_ 2214659329 HEV_DrvTqVal "HEV_DriverTorqueValue";
CM_ SG_ 2214659329 HEV_TqStndVal "HEV_TorqueStandardValue";
CM_ SG_ 2214659329 HEV_EngSpdErrSta "HEV_EngineSpeedErrorStatus";
CM_ BO_ 2214659330 "[P] Periodic";
CM_ SG_ 2214659330 HEV_EngTqVal "HEV_EngineTorqueValue";
CM_ SG_ 2214659330 HEV_FrctTqVal "HEV_FrictionTorqueValue";
CM_ SG_ 2214659330 HEV_EngSpdVal "HEV_EngineSpeedValue";
CM_ SG_ 2214659330 HEV_VehSpdVal "HEV_VehicleSpeedValue";
CM_ SG_ 2214659330 HEV_EngOpSta "HEV_EngineOperatingStatus";
CM_ SG_ 2214659330 HEV_EtcAppSta "HEV_EtcAppliedStatus";
CM_ BO_ 2214659331 "[P] Periodic";
CM_ SG_ 2214659331 HEV_EwpMtrSpdReq "HEV_EwpMotorSpeedRequest";
CM_ SG_ 2214659331 HEV_EwpMtrCtrlSta "HEV_EwpMotorControlStatus";
CM_ SG_ 2214659331 HEV_O2SnsrPreHeatSta "HEV_O2SensorPreHeatStatus";
CM_ SG_ 2214659331 HEV_FuelTnkPrsrErrSta "HEV_FuelTankPressureErrorStatus";
CM_ SG_ 2214659331 HEV_IntakeAirTempVal "HEV_IntakeAirTemperatureValue";
CM_ SG_ 2214659331 HEV_FirstFiringSta "HEV_FirstFiringStatus";
CM_ SG_ 2214659331 HEV_EngFulLoadSta "HEV_EngineFullLoadStatus";
CM_ SG_ 2214659331 HEV_DrvCycActSta "HEV_DrivingCycleActiveStatus";
CM_ SG_ 2214659331 HEV_WarmupCycSta "HEV_WarmupCycleStatus";
CM_ SG_ 2214659331 HEV_RbmDrvCycSta "HEV_RateBasedMonitoringDrivingCycleStatus";
CM_ SG_ 2214659331 HEV_ObdFrzFrmSta "HEV_ObdFreezeFrameStatus";
CM_ SG_ 2214659331 HEV_EngIdleTrgtSpdVal "HEV_EngineIdleTargetSpeedValue";
CM_ SG_ 2214659331 HEV_ThrPosSta "HEV_ThrottlePositionStatus";
CM_ BO_ 2214659332 "[P] Periodic";
CM_ SG_ 2214659332 HEV_FuelPmpTrgtPrsrVal "HEV_FuelPumpTargetPressureValue";
CM_ SG_ 2214659332 HEV_AccelPdlVal "HEV_AcceleratorPedalValue";
CM_ SG_ 2214659332 HEV_FuelTnkPrsrVal "HEV_FuelTankPressureValue";
CM_ SG_ 2214659332 HEV_FuelCutOffSta "HEV_FuelCutOffStatus";
CM_ SG_ 2214659332 HEV_FuelCutOffInhbtSta "HEV_FuelCutOffInhibitStatus";
CM_ SG_ 2214659332 HEV_FuelCnsmptVal "HEV_FuelConsumptionValue";
CM_ BO_ 2563126017 "[EC] On Event and On Change";
CM_ SG_ 2563126017 AMP_EngASDMasterGain "Command ASD(Active Sound Design, Virtual Engine Sound) Master Gain for Engineering mode";
CM_ BO_ 2563128321 "[EC] On Event and On Change";
CM_ SG_ 2563128321 AMP_QuietModeVolumeStep "Command for QuietMode Prompt Volume Setting
-range : 0 ~ max
-max : value of AMP_MaxQuietModeVolumeState(0x088)
-This Signal's Feedback is AMP_QuietModeVolumeState(0x088)@AMP";
CM_ BO_ 2470762241 "[PE] Periodic and On Event";
CM_ SG_ 2470762241 HU_VehiclePwr "Information for the H/U power status for ADM(Accessary Delay Mode)";
CM_ BO_ 2315420929 "[EC] On Event and On Change";
CM_ BO_ 2470762497 "[PE] Periodic and On Event";
CM_ SG_ 2470762497 HU_DistanceUnit "Request to set CLU Distance Unit";
CM_ SG_ 2470762497 HU_MicActivity "HU send this signal to eCall for MIC using status.
eCall unit stop the diagonosis when received 0x1:Activated from HU
Otherwise, eCall unit keep diagnosis every 1 sec. and HU can not use MIC";
CM_ SG_ 2470762497 CF_HU_GPSFlt "Information of GPS Fault 

0x0: Normal
0x1 : Fault operation
0x2 : Reserved
0x3:Invalid";
CM_ SG_ 2470762497 AVN_RSPA_CancelInput "Request Signal to cancel RSPA function";
CM_ SG_ 2470762497 AVN_RSPA_ModeSetStat "Signal for User's RSPA mode setting
RSPA 모드 선택 메뉴 선택 결과 (최좌측 기준)";
CM_ SG_ 2470762497 CAM_Request "HU command for AHD(Analog High Definition) camera to show different view screen";
CM_ SG_ 2470762497 HU_TempUnit "Request to set DATC/CLU temperature unit";
CM_ SG_ 2470762497 AVN_RSPA_Disp_Rdy "Signal to inform RSPA of AVN's display ready status
(RSPA 화면 표시 가능/불가능 상태를 알리기 위한 신호)";
CM_ SG_ 2470762497 CF_AVN_ProfileIDRValue "This signal is User ID value in H/Unit.";
CM_ SG_ 2470762497 HazardFromHUSVM "This signal is for Hazard control";
CM_ SG_ 2470762497 OMUOSMirCtrl "This signal is for the OutSide Mirror Control (Fold or Unfold)";
CM_ SG_ 2470762497 AVN_PDW_Input "This signal is for the PDW softkey";
CM_ SG_ 2470762497 AVN_RSPA_Input "This signal means RSPA softkey input(on/off)";
CM_ SG_ 2470762497 AVN_ParkingSW "This signal means whether ParkingSwich pressed or not";
CM_ SG_ 2470762497 OTAUIStatus "Information of the status of Head Unit";
CM_ SG_ 2470762497 C_TeleActiveStatus "This signal is for check TMS active status";
CM_ SG_ 2470762497 HU_AliveStatus "Information of the status of Head Unit
0x00 : Headunit is booting so, Headunit cant display any state
0x01 : Headunit is normal state, Headunit could display according to MM CAN  command.
0x02 : Headunit is doing their internal process, so Headunit cant communicate with other node.
For CLU/SCC/eCall
-AVN System transmission signal";
CM_ SG_ 2470762497 C_MtnAlertClu "This signal is for check TMS active status";
CM_ SG_ 2470762497 HU_RTCCheck "Checking whether RTC of AVN and HCU is operationg normally.";
CM_ BO_ 2411985665 "[EC] On Event and On Change";
CM_ SG_ 2411985665 HU_MoodTherapyDrSeat "Moodtherapy Driver Seat On/Off";
CM_ SG_ 2411985665 HU_VitalityFragrance "Vitality Fragrance On/Off";
CM_ SG_ 2411985665 HU_VitalityCurtain "Vitality Curtain On/Off";
CM_ SG_ 2411985665 HU_DelightMoodLamp "Delight MoodLamp On/Off";
CM_ SG_ 2411985665 HU_DelightFragrance "Delight Fragrance On/Off";
CM_ SG_ 2411985665 HU_DelightCurtain "Delight Curtain On/Off";
CM_ SG_ 2411985665 HU_MoodTherapyPsSeat "Moodtherapy Passenger Seat On/Off";
CM_ SG_ 2411985665 HU_CareMoodLamp "Care MoodLamp On/Off";
CM_ SG_ 2411985665 HU_CareFragrance "Care Fragrance On/Off";
CM_ SG_ 2411985665 HU_CareMassage "Care Massage On/Off";
CM_ SG_ 2411985665 HU_CareCurtain "Care Curtain On/Off";
CM_ SG_ 2411985665 HU_ComfortMoodLamp "Comfort MoodLamp On/Off";
CM_ SG_ 2411985665 HU_ComfortFragrance "Comfort Fragrance On/Off";
CM_ SG_ 2411985665 HU_ComfortMassage "Comfort Massage On/Off";
CM_ SG_ 2411985665 HU_ComfortCurtain "Comfort Curtain On/Off";
CM_ SG_ 2411985665 HU_MoodTherapyMode "Moodtherapy Mode Change Signal";
CM_ SG_ 2411985665 HU_MoodTherapyRlSeat "Moodtherapy RearLeft Seat On/Off";
CM_ SG_ 2411985665 HU_MoodTherapyRrSeat "Moodtherapy Rear Right Seat On/Off";
CM_ SG_ 2411985665 HU_VitalityMoodLamp "Vitality MoodLamp On/Off";
CM_ BO_ 2458167297 "[EC] On Event and On Change";
CM_ SG_ 2458167297 CF_AVN_FCANValueSet "This signal is used for a request to set the value of USM Menus. This signal requests to change status of AEB.";
CM_ SG_ 2458167297 CF_AVN_DAWModeNValueSet "This signal is used for a request to set the value of USM Menus.

If USM setting is changed, the message is sent 3 times.";
CM_ SG_ 2458167297 CF_AVN_HDANValueSet "USM request for HDA On/Off";
CM_ SG_ 2458167297 CF_AVN_BCWNValueSet "Reqeust to set BCW system state";
CM_ SG_ 2458167297 CF_AVN_NSCCCamNValueSet "This signal is used for a request to set the value of USM Menus. This signal requests to change status of SCC interlocked with Navi Camera function.

When this signal change, the message is sent 3 times.";
CM_ SG_ 2458167297 CF_AVN_ProximitySesnsorSet "USM request for proximity sensor On/Off";
CM_ SG_ 2458167297 CF_AVN_BCANValueSet "Reqeust to set BCA system state";
CM_ SG_ 2458167297 CF_AVN_ISLWNValueSet "This signal is used for a request to set the value of USM Menus. This signal requests to set ISLW status.
When this signal change, the message is sent 3 times.";
CM_ SG_ 2458167297 CF_AVN_WarningTimingNValueSet "Reqeust to set Warning Timing state";
CM_ SG_ 2458167297 CF_AVN_LFANValueSet "USM request for LFA On/Off";
CM_ SG_ 2458167297 CF_AVN_NCC_USM_set "Reqeust to set NCC system state";
CM_ SG_ 2458167297 CF_AVN_TirePressUnitNValueSet "Request to set Unit of Tire Air Pressure";
CM_ SG_ 2458167297 CF_AVN_PCANValueSet "USM Request for Parking Safety";
CM_ SG_ 2458167297 CF_AVN_TunnelClimateNvalueSet "USM for climate auto control when entering a tunnel";
CM_ SG_ 2458167297 CF_AVN_NSCCCrvNValueSet "This signal is used for a request to set the value of USM Menus. This signal requests to change status of SCC interlocked with Navi Curve function. When this signal change, the message is sent 3 times.";
CM_ SG_ 2458167297 CF_AVN_BCWSndWanNValueSet "Request to set BCW Sound Warning System state";
CM_ SG_ 2458167297 CF_AVN_RCCWNValueSet "Reqeust to set RCCW system state";
CM_ SG_ 2458167297 CF_AVN_LkaModeNValueSet "This signal is used for a request to set the value of USM Menus. This signal requests to set LKA control mode.
When this signal change, the message is sent 3 times.";
CM_ SG_ 2458167297 CF_AVN_PasSpkrLvNValueSet "Request to set Two PAS Speaker Volume Level";
CM_ SG_ 2458167297 CF_AVN_PDWAutoOnNValueSet "USM Request for PDW Auto On";
CM_ SG_ 2458167297 C_TempUnit "Request for changing Temp Unit";
CM_ SG_ 2458167297 CF_AVN_AdasVolumeNValueSet "Request to set ADAS warning volume level";
CM_ SG_ 2458167297 CF_AVN_SCCDrvModeNValueSet "This signal is used for a request to set the value of USM Menus. This signal requests to change SCC driving mode.
When this signal change, the message is sent 3 times.";
CM_ BO_ 1201 "[EW] On Event and On Write";
CM_ SG_ 1201 ICU_Crc1Val "ICU_CyclicRedundancyCheck1Value";
CM_ SG_ 1201 ICU_AlvCnt1Val "ICU_AliveCounter1Value";
CM_ SG_ 1201 ICU_Update_Enable "OTA Update enable, battery condition is OK";
CM_ BO_ 715 "[PE] Periodic and On Event";
CM_ SG_ 715 RRPSS_L_WalkInSwitchSts "Rear Right Walk In Switch Status";
CM_ SG_ 715 RRPSS_L_AstRclFwdMvBtn "Rear Right Recliner Forward Move Button";
CM_ SG_ 715 RRPSS_L_AstRclBwdMvBtn "Rear Right Recliner Backward Move Button";
CM_ SG_ 715 RRPSS_L_AstSldFwdMvBtn "Rear Right Slide Forward Move Button";
CM_ SG_ 715 RRPSS_L_AstSldBwdMvBtn "Rear Right Slide Backward Move Button";
CM_ SG_ 715 RRPSS_L_AstHgtUpMvBtn "Rear Right Height Up Move Button";
CM_ SG_ 715 RRPSS_L_AstHRestFwdMvBtn "Rear Right HeadRest Forward Move Button";
CM_ SG_ 715 RRPSS_L_AstHgtDnMvBtn "Rear Right Height Down Move Button";
CM_ SG_ 715 RRPSS_L_AstFRestOpenMvBtn "Rear Right FootRest Open Move Button";
CM_ SG_ 715 RRPSS_L_AstFRestCloseMvBtn "Rear Right FootRest Close Move Button";
CM_ SG_ 715 RRPSS_L_AstHRestBwdMvBtn "Rear Right HeadRest Backward Move Button";
CM_ SG_ 715 RRPSS_L_AstHRestUpMvBtn "Rear Right HeadRest Up Move Button";
CM_ SG_ 715 RRPSS_L_AstHRestDnMvBtn "Rear Right HeadRest Down Move Button";
CM_ BO_ 2164277249 "[P] Periodic";
CM_ SG_ 2164277249 TCU_Crc1Val "TCU_CyclicRedundancyCheck1Value";
CM_ SG_ 2164277249 TCU_AlvCnt1Val "TCU_AliveCounter1Value";
CM_ SG_ 2164277249 TCU_GearSlctDis "TCU_GearSelectDisplay";
CM_ SG_ 2164277249 TCU_Typ "TCU_Type";
CM_ SG_ 2164277249 TCU_TqRdctnVal "TCU_TorqueReductionValue";
CM_ SG_ 2164277249 TCU_GearStepTyp "TCU_GearStepType";
CM_ SG_ 2164277249 TCU_GearShftSta "TCU_GearShiftStatus";
CM_ SG_ 2164277249 TCU_TqCnvrtrSta "TCU_TorqueConverterStatus";
CM_ BO_ 2164277252 "[P] Periodic";
CM_ SG_ 2164277252 TCU_NetrlCtrlSta "TCU_NeutralControlStatus";
CM_ SG_ 2164277252 TCU_ShftPtrnSta "TCU_ShiftPatternStatus";
CM_ SG_ 2164277252 TCU_EPBReq "EPB Request signal for prevent P-D Shock on hill";
CM_ SG_ 2164277252 TCU_VgisInhbtReq "TCU_VgisInhibitionRequest";
CM_ SG_ 2164277252 TCU_EngTqIncReqVal "TCU_EngineTorqueIncreaseReqValue";
CM_ BO_ 2189467649 "[P] Periodic";
CM_ SG_ 2189467649 WHL_Crc1Val "WHL_CyclicRedundancyCheck1Value";
CM_ SG_ 2189467649 WHL_AlvCnt1Val "WHL_AliveCounter1Value";
CM_ SG_ 2189467649 WHL_PlsFLVal "WHL_PulseFrontLeftValue ##2G##ESC - WHL_PUL11 - WHL_PUL_FL";
CM_ SG_ 2189467649 WHL_PlsFRVal "WHL_PulseFrontRightValue ##2G##ESC - WHL_PUL11 - WHL_PUL_FR";
CM_ SG_ 2189467649 WHL_PlsRLVal "WHL_PulseRearLeftValue ##2G##ESC - WHL_PUL11 - WHL_PUL_RL";
CM_ SG_ 2189467649 WHL_PlsRRVal "WHL_PulseRearRightValue ##2G##ESC - WHL_PUL11 - WHL_PUL_RR";
CM_ SG_ 2189467649 WHL_DirFLVal "WHL_DirectionFrontLeftValue ##2G##ESC - WHL_PUL11 - WHL_DIR_FL";
CM_ SG_ 2189467649 WHL_DirFRVal "WHL_DirectionFrontRightValue ##2G##ESC - WHL_PUL11 - WHL_DIR_FR";
CM_ SG_ 2189467649 WHL_DirRLVal "WHL_DirectionRearLeftValue ##2G##ESC - WHL_PUL11 - WHL_DIR_RL";
CM_ SG_ 2189467649 WHL_DirRRVal "WHL_DirectionRearRightValue ##2G##ESC - WHL_PUL11 - WHL_DIR_RR";
CM_ BO_ 2189467650 "[P] Periodic";
CM_ SG_ 2189467650 WHL_SpdFLVal "WHL_SpeedFrontLeftValue ##2G##ESC - WHL_SPD11 - WHL_SPD_FL";
CM_ SG_ 2189467650 WHL_SpdFRVal "WHL_SpeedFrontRightValue ##2G##ESC - WHL_SPD11 - WHL_SPD_FR";
CM_ SG_ 2189467650 WHL_SpdRLVal "WHL_SpeedRearLeftValue ##2G##ESC - WHL_SPD11 - WHL_SPD_RL";
CM_ SG_ 2189467650 WHL_SpdRRVal "WHL_SpeedRearRightValue ##2G##ESC - WHL_SPD11 - WHL_SPD_RR";
CM_ BO_ 2189467651 "[P] Periodic";
CM_ SG_ 2189467651 WHL_SpdCalParmtr "WHL_SpeedCalculationParameter";
BA_DEF_ BO_ "DiagState" ENUM "No","Yes" ;
BA_DEF_ BO_ "DiagResponse" ENUM "No","Yes" ;
BA_DEF_ BO_ "DiagRequest" ENUM "No","Yes" ;
BA_DEF_ BO_ "TpMessage" ENUM "No","Yes" ;
BA_DEF_ BO_ "UsrMsgIDSforwardDeviation" INT 0 100 ;
BA_DEF_ BO_ "UsrMsgIDSbackwardDeviation" INT 50 1000 ;
BA_DEF_ BO_ "GenMsgCycleTime" INT 0 2000 ;
BA_DEF_ BO_ "GenMsgStartDelayTime" INT 0 2000 ;
BA_DEF_ BO_ "GenMsgSendType" ENUM "Cyclic","NoMsgSendType" ;
BA_DEF_ BO_ "GenMsgCycleTimeFast" INT 0 500 ;
BA_DEF_ BO_ "GenMsgDelayTime" INT 0 20 ;
BA_DEF_ BO_ "GenMsgILSupport" ENUM "No","Yes" ;
BA_DEF_ BO_ "GenMsgNrOfRepetition" INT 0 3 ;
BA_DEF_ BO_ "NmMessage" ENUM "No","Yes" ;
BA_DEF_ BO_ "NWM-Botschaft" ENUM "No","Yes" ;
BA_DEF_ BO_ "TpTxIndex" INT 0 255 ;
BA_DEF_ BO_ "VFrameFormat" ENUM "StandardCAN","ExtendedCAN","reserved","reserved","reserved","reserved","reserved","reserved","reserved","reserved","reserved","reserved","reserved","reserved","StandardCAN_FD","ExtendedCAN_FD" ;
BA_DEF_ SG_ "UserSigValidity" ENUM "B+","ACC","IG","IG1","IG2","IG3","IG1 or IG2","IG1 or IG3","Undef" ;
BA_DEF_ SG_ "TimeoutValue" STRING ;
BA_DEF_ SG_ "UsrSigPurpose" ENUM "Undef","FN","DIAG","DIAG(Req)","DIAG(Res)","DIAG(Phy)","DEV","CCP(Req)","CCP(Res)","NM","TP" ;
BA_DEF_ SG_ "GenSigStartValue" INT 0 1215752192 ;
BA_DEF_ SG_ "NetworkRequest" ENUM "Yes","No" ;
BA_DEF_ SG_ "NetworkRequestHoldingTime" INT 0 65535 ;
BA_DEF_ SG_ "Description" STRING ;
BA_DEF_ SG_ "Version" STRING ;
BA_DEF_ SG_ "GenSigEnvVarType" ENUM "Int","Float","Undef" ;
BA_DEF_ SG_ "GenSigSendType" ENUM "Cyclic","OnWrite","OnWriteWithRepetition","OnChange","OnChangeWithRepetition","IfActive","IfActiveWithRepetition","NoSigSendType","OnChangeAndIfActive","OnChangeAndIfActiveWithRepetition" ;
BA_DEF_ SG_ "GwSigLatencyTime" INT 0 65536 ;
BA_DEF_ SG_ "GwSigMissingSourceType" ENUM "Undef","OldValue","DefaultValue","InitialValue" ;
BA_DEF_ SG_ "NWM-WakeupAllowed" ENUM "<n.a.>" ;
BA_DEF_ SG_ "RoutingFactor" INT 1 1215752192 ;
BA_DEF_REL_ BU_SG_REL_ "GenSigTimeoutTime" INT 0 7000 ;
BA_DEF_DEF_ "DiagState" "No" ;
BA_DEF_DEF_ "DiagResponse" "No" ;
BA_DEF_DEF_ "DiagRequest" "No" ;
BA_DEF_DEF_ "TpMessage" "No" ;
BA_DEF_DEF_ "UsrMsgIDSforwardDeviation" 10 ;
BA_DEF_DEF_ "UsrMsgIDSbackwardDeviation" 100 ;
BA_DEF_DEF_ "GenMsgCycleTime" 200 ;
BA_DEF_DEF_ "GenMsgStartDelayTime" 0 ;
BA_DEF_DEF_ "GenMsgSendType" "NoMsgSendType" ;
BA_DEF_DEF_ "GenMsgCycleTimeFast" 40 ;
BA_DEF_DEF_ "GenMsgDelayTime" 20 ;
BA_DEF_DEF_ "GenMsgILSupport" "Yes" ;
BA_DEF_DEF_ "GenMsgNrOfRepetition" 3 ;
BA_DEF_DEF_ "NmMessage" "No" ;
BA_DEF_DEF_ "NWM-Botschaft" "No" ;
BA_DEF_DEF_ "TpTxIndex" 0 ;
BA_DEF_DEF_ "VFrameFormat" "StandardCAN" ;
BA_DEF_DEF_ "UserSigValidity" "IG" ;
BA_DEF_DEF_ "TimeoutValue" "" ;
BA_DEF_DEF_ "UsrSigPurpose" "FN" ;
BA_DEF_DEF_ "GenSigStartValue" 0 ;
BA_DEF_DEF_ "NetworkRequest" "No" ;
BA_DEF_DEF_ "NetworkRequestHoldingTime" 0 ;
BA_DEF_DEF_ "Description" "" ;
BA_DEF_DEF_ "Version" "" ;
BA_DEF_DEF_ "GenSigEnvVarType" "Undef" ;
BA_DEF_DEF_ "GenSigSendType" "NoSigSendType" ;
BA_DEF_DEF_ "GwSigLatencyTime" 40 ;
BA_DEF_DEF_ "GwSigMissingSourceType" "Undef" ;
BA_DEF_DEF_ "NWM-WakeupAllowed" "<n.a.>" ;
BA_DEF_DEF_ "RoutingFactor" 1 ;
BA_DEF_DEF_REL_ "GenSigTimeoutTime" 500 ;
BA_ "GenMsgSendType" BO_ 2273436929 0;
BA_ "GenMsgCycleTime" BO_ 2273436929 150;
BA_ "GenMsgCycleTimeFast" BO_ 2273436929 0;
BA_ "GenMsgNrOfRepetition" BO_ 2273436929 0;
BA_ "VFrameFormat" BO_ 2273436929 1;
BA_ "Description" SG_ 2273436929 ADAS_CMD_Crc40Val "The data area for CRC calculation is based on the data length (DLC) of the message DB.

The CRC shall be calculated over the entire data block (excluding the CRC bytes) including the user data, alive counter and Data ID

 

- CRC Polynomial (0x1021) , Initial Value : 0xFFFF, XOR value : 0x0000, Data ID : Message ID + 0xF800 

- The initial value is for CRC calculation and the message should be sent with the calculated result value. 

- The mathematical expression to 16 bit CRC polynomial is given here. G(x) = x16 + x12 + x5 + 1";
BA_ "GenSigStartValue" SG_ 2273436929 ADAS_CMD_Crc40Val 65535;
BA_ "UserSigValidity" SG_ 2273436929 ADAS_CMD_Crc40Val 3;
BA_ "RoutingFactor" SG_ 2273436929 ADAS_CMD_Crc40Val 3;
BA_ "Version" SG_ 2273436929 ADAS_CMD_Crc40Val "20.04.02";
BA_ "Description" SG_ 2273436929 ADAS_CMD_AlvCnt40Val "For the first transmission request for a data element the counter shall be initialized with 0 and shall be incremented by 1 for every subsequent send request. 

When the counter reaches the maximum value(0xFF), then it shall restart with 0 for the next send request";
BA_ "UserSigValidity" SG_ 2273436929 ADAS_CMD_AlvCnt40Val 3;
BA_ "RoutingFactor" SG_ 2273436929 ADAS_CMD_AlvCnt40Val 3;
BA_ "Version" SG_ 2273436929 ADAS_CMD_AlvCnt40Val "20.04.02";
BA_ "Description" SG_ 2273436929 RCCW_Sta "This signal indicates the Status of RCCW";
BA_ "UserSigValidity" SG_ 2273436929 RCCW_Sta 3;
BA_ "RoutingFactor" SG_ 2273436929 RCCW_Sta 3;
BA_ "Version" SG_ 2273436929 RCCW_Sta "20.03.06";
BA_ "Description" SG_ 2273436929 RCCW_LtIndSta "This signal Indicates RCCW Warning Indicator mode for Left side";
BA_ "UserSigValidity" SG_ 2273436929 RCCW_LtIndSta 3;
BA_ "RoutingFactor" SG_ 2273436929 RCCW_LtIndSta 3;
BA_ "Version" SG_ 2273436929 RCCW_LtIndSta "20.09.00";
BA_ "Description" SG_ 2273436929 RCCW_RtIndSta "This signal Indicates RCCW Warning Indicator mode for Right side";
BA_ "UserSigValidity" SG_ 2273436929 RCCW_RtIndSta 3;
BA_ "RoutingFactor" SG_ 2273436929 RCCW_RtIndSta 3;
BA_ "Version" SG_ 2273436929 RCCW_RtIndSta "20.09.00";
BA_ "Description" SG_ 2273436929 RCCW_LtSndWrngSta "This signal indicates RCCW Sound Warning for Rear Left Speaker";
BA_ "UserSigValidity" SG_ 2273436929 RCCW_LtSndWrngSta 3;
BA_REL_ "GenSigTimeoutTime" BU_SG_REL_ AMP SG_ 2273436929 RCCW_LtSndWrngSta 1500;
BA_ "RoutingFactor" SG_ 2273436929 RCCW_LtSndWrngSta 3;
BA_ "Version" SG_ 2273436929 RCCW_LtSndWrngSta "20.03.06";
BA_ "Description" SG_ 2273436929 RCCW_RtSndWrngSta "This signal indicates RCCW Sound Warning for Rear Right Speaker";
BA_ "UserSigValidity" SG_ 2273436929 RCCW_RtSndWrngSta 3;
BA_REL_ "GenSigTimeoutTime" BU_SG_REL_ AMP SG_ 2273436929 RCCW_RtSndWrngSta 1500;
BA_ "RoutingFactor" SG_ 2273436929 RCCW_RtSndWrngSta 3;
BA_ "Version" SG_ 2273436929 RCCW_RtSndWrngSta "20.03.06";
BA_ "GenMsgSendType" BO_ 2273436930 0;
BA_ "GenMsgCycleTime" BO_ 2273436930 150;
BA_ "GenMsgCycleTimeFast" BO_ 2273436930 0;
BA_ "GenMsgNrOfRepetition" BO_ 2273436930 0;
BA_ "VFrameFormat" BO_ 2273436930 1;
BA_ "Description" SG_ 2273436930 RCCA_Deccel_Req "This value is defined the time to stop the vehicle.





(PH) = 0.04 * (Hex)g";
BA_ "UserSigValidity" SG_ 2273436930 RCCA_Deccel_Req 3;
BA_ "RoutingFactor" SG_ 2273436930 RCCA_Deccel_Req 3;
BA_ "Version" SG_ 2273436930 RCCA_Deccel_Req "20.03.06";
BA_ "Description" SG_ 2273436930 RCCA_Sta "This signal indicates the Status of RCCA";
BA_ "UserSigValidity" SG_ 2273436930 RCCA_Sta 3;
BA_ "RoutingFactor" SG_ 2273436930 RCCA_Sta 3;
BA_ "Version" SG_ 2273436930 RCCA_Sta "20.03.06";
BA_ "Description" SG_ 2273436930 RCCA_OnOffEquipSt "This signal indicates the on/off status of RCCA";
BA_ "UserSigValidity" SG_ 2273436930 RCCA_OnOffEquipSt 3;
BA_ "RoutingFactor" SG_ 2273436930 RCCA_OnOffEquipSt 3;
BA_ "Version" SG_ 2273436930 RCCA_OnOffEquipSt "20.03.06";
BA_ "Description" SG_ 2273436930 SEA_Sta "SEA tells Body control unit to operate Child door lock to lock";
BA_ "UserSigValidity" SG_ 2273436930 SEA_Sta 0;
BA_ "RoutingFactor" SG_ 2273436930 SEA_Sta 3;
BA_ "Version" SG_ 2273436930 SEA_Sta "20.03.06";
BA_ "Description" SG_ 2273436930 SEA_LtTrgtSta "This signal carries the information which message shall be displayed to the driver when the system must activate SEA";
BA_ "UserSigValidity" SG_ 2273436930 SEA_LtTrgtSta 0;
BA_REL_ "GenSigTimeoutTime" BU_SG_REL_ AMP SG_ 2273436930 SEA_LtTrgtSta 1500;
BA_ "RoutingFactor" SG_ 2273436930 SEA_LtTrgtSta 3;
BA_ "Version" SG_ 2273436930 SEA_LtTrgtSta "20.09.00";
BA_ "Description" SG_ 2273436930 SEA_RtTrgtSta "This signal carries the information which message shall be displayed to the driver when the system must activate SEA";
BA_ "UserSigValidity" SG_ 2273436930 SEA_RtTrgtSta 0;
BA_REL_ "GenSigTimeoutTime" BU_SG_REL_ AMP SG_ 2273436930 SEA_RtTrgtSta 1500;
BA_ "RoutingFactor" SG_ 2273436930 SEA_RtTrgtSta 3;
BA_ "Version" SG_ 2273436930 SEA_RtTrgtSta "20.09.00";
BA_ "Description" SG_ 2273436930 SEA_OnOffEquipSta_New "This signal indicates the on/off status of SEA";
BA_ "UserSigValidity" SG_ 2273436930 SEA_OnOffEquipSta_New 0;
BA_ "RoutingFactor" SG_ 2273436930 SEA_OnOffEquipSta_New 3;
BA_ "Version" SG_ 2273436930 SEA_OnOffEquipSta_New "20.03.06";
BA_ "Description" SG_ 2273436930 RCCA_BrkCmdSta "RCCA Function Brake Command";
BA_ "UserSigValidity" SG_ 2273436930 RCCA_BrkCmdSta 3;
BA_ "RoutingFactor" SG_ 2273436930 RCCA_BrkCmdSta 3;
BA_ "Version" SG_ 2273436930 RCCA_BrkCmdSta "20.03.06";
BA_ "Description" SG_ 2273436930 RCCA_LtWrngSta "This signal Indicates RCCA Warning state for HMI(Cluster)";
BA_ "UserSigValidity" SG_ 2273436930 RCCA_LtWrngSta 3;
BA_ "RoutingFactor" SG_ 2273436930 RCCA_LtWrngSta 3;
BA_ "Version" SG_ 2273436930 RCCA_LtWrngSta "20.09.00";
BA_ "Description" SG_ 2273436930 RCCA_RtWrngSta "This signal Indicates RCCA Warning state for HMI";
BA_ "UserSigValidity" SG_ 2273436930 RCCA_RtWrngSta 3;
BA_ "RoutingFactor" SG_ 2273436930 RCCA_RtWrngSta 3;
BA_ "Version" SG_ 2273436930 RCCA_RtWrngSta "20.09.00";
BA_ "GenMsgSendType" BO_ 287 0;
BA_ "Description" SG_ 287 APSS_LumbarUpSw "APSS_LumbarUpMoveSwitch";
BA_ "GenSigSendType" SG_ 287 APSS_LumbarUpSw 4;
BA_ "UserSigValidity" SG_ 287 APSS_LumbarUpSw 0;
BA_REL_ "GenSigTimeoutTime" BU_SG_REL_ ASAU SG_ 287 APSS_LumbarUpSw 1500;
BA_REL_ "GenSigTimeoutTime" BU_SG_REL_ CGW_CCU SG_ 287 APSS_LumbarUpSw 1500;
BA_ "NetworkRequest" SG_ 287 APSS_LumbarUpSw 0;
BA_ "NetworkRequestHoldingTime" SG_ 287 APSS_LumbarUpSw 5000;
BA_ "Version" SG_ 287 APSS_LumbarUpSw "19.11.06";
BA_ "Description" SG_ 287 APSS_LumbarMidSw "APSS_LumbarMiddleSwitch";
BA_ "GenSigSendType" SG_ 287 APSS_LumbarMidSw 4;
BA_ "UserSigValidity" SG_ 287 APSS_LumbarMidSw 0;
BA_REL_ "GenSigTimeoutTime" BU_SG_REL_ ASAU SG_ 287 APSS_LumbarMidSw 1500;
BA_REL_ "GenSigTimeoutTime" BU_SG_REL_ CGW_CCU SG_ 287 APSS_LumbarMidSw 1500;
BA_ "NetworkRequest" SG_ 287 APSS_LumbarMidSw 0;
BA_ "NetworkRequestHoldingTime" SG_ 287 APSS_LumbarMidSw 5000;
BA_ "Version" SG_ 287 APSS_LumbarMidSw "19.11.06";
BA_ "Description" SG_ 287 APSS_LumbarLowSw "APSS_LumbarLowerSwitch";
BA_ "GenSigSendType" SG_ 287 APSS_LumbarLowSw 4;
BA_ "UserSigValidity" SG_ 287 APSS_LumbarLowSw 0;
BA_REL_ "GenSigTimeoutTime" BU_SG_REL_ ASAU SG_ 287 APSS_LumbarLowSw 1500;
BA_REL_ "GenSigTimeoutTime" BU_SG_REL_ CGW_CCU SG_ 287 APSS_LumbarLowSw 1500;
BA_ "NetworkRequest" SG_ 287 APSS_LumbarLowSw 0;
BA_ "NetworkRequestHoldingTime" SG_ 287 APSS_LumbarLowSw 5000;
BA_ "Version" SG_ 287 APSS_LumbarLowSw "19.11.06";
BA_ "Description" SG_ 287 APSS_LumbarDefSw "APSS_LumbarDeflationSwitch";
BA_ "GenSigSendType" SG_ 287 APSS_LumbarDefSw 4;
BA_ "UserSigValidity" SG_ 287 APSS_LumbarDefSw 0;
BA_REL_ "GenSigTimeoutTime" BU_SG_REL_ ASAU SG_ 287 APSS_LumbarDefSw 1500;
BA_REL_ "GenSigTimeoutTime" BU_SG_REL_ CGW_CCU SG_ 287 APSS_LumbarDefSw 1500;
BA_ "NetworkRequest" SG_ 287 APSS_LumbarDefSw 0;
BA_ "NetworkRequestHoldingTime" SG_ 287 APSS_LumbarDefSw 5000;
BA_ "Version" SG_ 287 APSS_LumbarDefSw "19.11.06";
BA_ "Description" SG_ 287 APSS_BolsterInfSw "APSS_BolsterInflationSwitch";
BA_ "GenSigSendType" SG_ 287 APSS_BolsterInfSw 4;
BA_ "UserSigValidity" SG_ 287 APSS_BolsterInfSw 0;
BA_REL_ "GenSigTimeoutTime" BU_SG_REL_ ASAU SG_ 287 APSS_BolsterInfSw 1500;
BA_REL_ "GenSigTimeoutTime" BU_SG_REL_ CGW_CCU SG_ 287 APSS_BolsterInfSw 1500;
BA_ "NetworkRequest" SG_ 287 APSS_BolsterInfSw 0;
BA_ "NetworkRequestHoldingTime" SG_ 287 APSS_BolsterInfSw 5000;
BA_ "Version" SG_ 287 APSS_BolsterInfSw "19.11.06";
BA_ "Description" SG_ 287 APSS_BolsterDefSw "APSS_BolsterDeflationSwitch";
BA_ "GenSigSendType" SG_ 287 APSS_BolsterDefSw 4;
BA_ "UserSigValidity" SG_ 287 APSS_BolsterDefSw 0;
BA_REL_ "GenSigTimeoutTime" BU_SG_REL_ ASAU SG_ 287 APSS_BolsterDefSw 1500;
BA_REL_ "GenSigTimeoutTime" BU_SG_REL_ CGW_CCU SG_ 287 APSS_BolsterDefSw 1500;
BA_ "NetworkRequest" SG_ 287 APSS_BolsterDefSw 0;
BA_ "NetworkRequestHoldingTime" SG_ 287 APSS_BolsterDefSw 5000;
BA_ "Version" SG_ 287 APSS_BolsterDefSw "19.11.06";
BA_ "GenMsgSendType" BO_ 271 0;
BA_ "Description" SG_ 271 ASAU_AirSptTimeRValueSet "Air Support Time(Massage Time) USM R Value";
BA_ "GenSigSendType" SG_ 271 ASAU_AirSptTimeRValueSet 4;
BA_ "UserSigValidity" SG_ 271 ASAU_AirSptTimeRValueSet 3;
BA_REL_ "GenSigTimeoutTime" BU_SG_REL_ CGW_CCU SG_ 271 ASAU_AirSptTimeRValueSet 1500;
BA_ "NetworkRequest" SG_ 271 ASAU_AirSptTimeRValueSet 0;
BA_ "NetworkRequestHoldingTime" SG_ 271 ASAU_AirSptTimeRValueSet 5000;
BA_ "Version" SG_ 271 ASAU_AirSptTimeRValueSet "19.11.06";
BA_ "Description" SG_ 271 ASAU_AstSmtAirSptRValueSet "Seat Smart Air Support Function USM R Value";
BA_ "GenSigSendType" SG_ 271 ASAU_AstSmtAirSptRValueSet 4;
BA_ "UserSigValidity" SG_ 271 ASAU_AstSmtAirSptRValueSet 3;
BA_REL_ "GenSigTimeoutTime" BU_SG_REL_ CGW_CCU SG_ 271 ASAU_AstSmtAirSptRValueSet 1500;
BA_ "NetworkRequest" SG_ 271 ASAU_AstSmtAirSptRValueSet 0;
BA_ "NetworkRequestHoldingTime" SG_ 271 ASAU_AstSmtAirSptRValueSet 5000;
BA_ "Version" SG_ 271 ASAU_AstSmtAirSptRValueSet "19.12.00";
BA_ "Description" SG_ 271 ASAU_CushSoftRValueSet "Cushion Soft R Value";
BA_ "GenSigSendType" SG_ 271 ASAU_CushSoftRValueSet 4;
BA_ "UserSigValidity" SG_ 271 ASAU_CushSoftRValueSet 3;
BA_REL_ "GenSigTimeoutTime" BU_SG_REL_ CGW_CCU SG_ 271 ASAU_CushSoftRValueSet 1500;
BA_ "NetworkRequest" SG_ 271 ASAU_CushSoftRValueSet 0;
BA_ "NetworkRequestHoldingTime" SG_ 271 ASAU_CushSoftRValueSet 5000;
BA_ "Version" SG_ 271 ASAU_CushSoftRValueSet "20.04.02";
BA_ "Description" SG_ 271 ASAU_BackSoftRValueSet "Back Soft USM R Value";
BA_ "GenSigSendType" SG_ 271 ASAU_BackSoftRValueSet 4;
BA_ "UserSigValidity" SG_ 271 ASAU_BackSoftRValueSet 3;
BA_REL_ "GenSigTimeoutTime" BU_SG_REL_ CGW_CCU SG_ 271 ASAU_BackSoftRValueSet 1500;
BA_ "NetworkRequest" SG_ 271 ASAU_BackSoftRValueSet 0;
BA_ "NetworkRequestHoldingTime" SG_ 271 ASAU_BackSoftRValueSet 5000;
BA_ "Version" SG_ 271 ASAU_BackSoftRValueSet "20.04.02";
BA_ "Description" SG_ 271 ASAU_AirSptModeRValueSet "Air Support Mode(Massage Mode) USM R Value";
BA_ "GenSigSendType" SG_ 271 ASAU_AirSptModeRValueSet 4;
BA_ "UserSigValidity" SG_ 271 ASAU_AirSptModeRValueSet 3;
BA_REL_ "GenSigTimeoutTime" BU_SG_REL_ CGW_CCU SG_ 271 ASAU_AirSptModeRValueSet 1500;
BA_ "NetworkRequest" SG_ 271 ASAU_AirSptModeRValueSet 0;
BA_ "NetworkRequestHoldingTime" SG_ 271 ASAU_AirSptModeRValueSet 5000;
BA_ "Version" SG_ 271 ASAU_AirSptModeRValueSet "19.11.06";
BA_ "Description" SG_ 271 ASAU_NotFootMsgOperStaWarnPE "Passenger Foot Massage Operation Disable Mode";
BA_ "GenSigSendType" SG_ 271 ASAU_NotFootMsgOperStaWarnPE 4;
BA_ "UserSigValidity" SG_ 271 ASAU_NotFootMsgOperStaWarnPE 3;
BA_REL_ "GenSigTimeoutTime" BU_SG_REL_ ATS SG_ 271 ASAU_NotFootMsgOperStaWarnPE 1500;
BA_ "NetworkRequest" SG_ 271 ASAU_NotFootMsgOperStaWarnPE 0;
BA_ "NetworkRequestHoldingTime" SG_ 271 ASAU_NotFootMsgOperStaWarnPE 5000;
BA_ "Version" SG_ 271 ASAU_NotFootMsgOperStaWarnPE "20.08.00";
BA_ "Description" SG_ 271 ASAU_RRFootAirSptRValueSet "Foot Air Support USM R Value";
BA_ "GenSigSendType" SG_ 271 ASAU_RRFootAirSptRValueSet 4;
BA_ "UserSigValidity" SG_ 271 ASAU_RRFootAirSptRValueSet 3;
BA_REL_ "GenSigTimeoutTime" BU_SG_REL_ APSM SG_ 271 ASAU_RRFootAirSptRValueSet 1500;
BA_REL_ "GenSigTimeoutTime" BU_SG_REL_ ATS SG_ 271 ASAU_RRFootAirSptRValueSet 1500;
BA_REL_ "GenSigTimeoutTime" BU_SG_REL_ CGW_CCU SG_ 271 ASAU_RRFootAirSptRValueSet 1500;
BA_ "NetworkRequest" SG_ 271 ASAU_RRFootAirSptRValueSet 0;
BA_ "NetworkRequestHoldingTime" SG_ 271 ASAU_RRFootAirSptRValueSet 5000;
BA_ "Version" SG_ 271 ASAU_RRFootAirSptRValueSet "19.12.00";
BA_ "Description" SG_ 271 ASAU_RRFootAirSptHeatRValueSet "Foot Air Support Heat USM R Value";
BA_ "GenSigSendType" SG_ 271 ASAU_RRFootAirSptHeatRValueSet 4;
BA_ "UserSigValidity" SG_ 271 ASAU_RRFootAirSptHeatRValueSet 3;
BA_REL_ "GenSigTimeoutTime" BU_SG_REL_ APSM SG_ 271 ASAU_RRFootAirSptHeatRValueSet 1500;
BA_REL_ "GenSigTimeoutTime" BU_SG_REL_ ATS SG_ 271 ASAU_RRFootAirSptHeatRValueSet 1500;
BA_ "NetworkRequest" SG_ 271 ASAU_RRFootAirSptHeatRValueSet 0;
BA_ "NetworkRequestHoldingTime" SG_ 271 ASAU_RRFootAirSptHeatRValueSet 5000;
BA_ "Version" SG_ 271 ASAU_RRFootAirSptHeatRValueSet "20.01.02";
BA_ "Description" SG_ 271 ASAU_MoodTrpyRValueSet "Passenger Seat Mood Therapy R Value";
BA_ "GenSigSendType" SG_ 271 ASAU_MoodTrpyRValueSet 4;
BA_ "UserSigValidity" SG_ 271 ASAU_MoodTrpyRValueSet 3;
BA_REL_ "GenSigTimeoutTime" BU_SG_REL_ CGW_CCU SG_ 271 ASAU_MoodTrpyRValueSet 1500;
BA_ "NetworkRequest" SG_ 271 ASAU_MoodTrpyRValueSet 0;
BA_ "NetworkRequestHoldingTime" SG_ 271 ASAU_MoodTrpyRValueSet 5000;
BA_ "Version" SG_ 271 ASAU_MoodTrpyRValueSet "20.07.03";
BA_ "Description" SG_ 271 ASAU_MoodTrpyCareSta "Passenger Seat Mood Therapy Care Mode R Value";
BA_ "GenSigSendType" SG_ 271 ASAU_MoodTrpyCareSta 4;
BA_ "UserSigValidity" SG_ 271 ASAU_MoodTrpyCareSta 3;
BA_REL_ "GenSigTimeoutTime" BU_SG_REL_ CGW_CCU SG_ 271 ASAU_MoodTrpyCareSta 1500;
BA_ "NetworkRequest" SG_ 271 ASAU_MoodTrpyCareSta 0;
BA_ "NetworkRequestHoldingTime" SG_ 271 ASAU_MoodTrpyCareSta 5000;
BA_ "Version" SG_ 271 ASAU_MoodTrpyCareSta "20.07.12";
BA_ "Description" SG_ 271 ASAU_MoodTrpyComfSta "Passenger Seat Mood Therapy Comfort Mode R Value";
BA_ "GenSigSendType" SG_ 271 ASAU_MoodTrpyComfSta 4;
BA_ "UserSigValidity" SG_ 271 ASAU_MoodTrpyComfSta 3;
BA_REL_ "GenSigTimeoutTime" BU_SG_REL_ CGW_CCU SG_ 271 ASAU_MoodTrpyComfSta 1500;
BA_ "NetworkRequest" SG_ 271 ASAU_MoodTrpyComfSta 0;
BA_ "NetworkRequestHoldingTime" SG_ 271 ASAU_MoodTrpyComfSta 5000;
BA_ "Version" SG_ 271 ASAU_MoodTrpyComfSta "20.07.12";
BA_ "Description" SG_ 271 ASAU_AirSptStrRValueSet "Air Support Strenth(Massage Strenth) USM R Value";
BA_ "GenSigSendType" SG_ 271 ASAU_AirSptStrRValueSet 4;
BA_ "UserSigValidity" SG_ 271 ASAU_AirSptStrRValueSet 3;
BA_REL_ "GenSigTimeoutTime" BU_SG_REL_ CGW_CCU SG_ 271 ASAU_AirSptStrRValueSet 1500;
BA_ "NetworkRequest" SG_ 271 ASAU_AirSptStrRValueSet 0;
BA_ "NetworkRequestHoldingTime" SG_ 271 ASAU_AirSptStrRValueSet 5000;
BA_ "Version" SG_ 271 ASAU_AirSptStrRValueSet "20.07.11";
BA_ "GenMsgSendType" BO_ 2558929665 0;
BA_ "VFrameFormat" BO_ 2558929665 1;
BA_ "Description" SG_ 2558929665 Warn_Sound_SCC_TakeoverReq "This signal is transmitted from cluster to AMP for SCC TAKE OVER REQUSET SOUND";
BA_ "GenSigSendType" SG_ 2558929665 Warn_Sound_SCC_TakeoverReq 4;
BA_ "GenSigStartValue" SG_ 2558929665 Warn_Sound_SCC_TakeoverReq 3;
BA_ "UserSigValidity" SG_ 2558929665 Warn_Sound_SCC_TakeoverReq 0;
BA_REL_ "GenSigTimeoutTime" BU_SG_REL_ AMP SG_ 2558929665 Warn_Sound_SCC_TakeoverReq 1500;
BA_ "Version" SG_ 2558929665 Warn_Sound_SCC_TakeoverReq "20.03.05";
BA_ "Description" SG_ 2558929665 Warn_Sound_PopUp_Vol "This is a signal for ADAS VOLUME level control";
BA_ "GenSigSendType" SG_ 2558929665 Warn_Sound_PopUp_Vol 4;
BA_ "GenSigStartValue" SG_ 2558929665 Warn_Sound_PopUp_Vol 7;
BA_ "UserSigValidity" SG_ 2558929665 Warn_Sound_PopUp_Vol 0;
BA_REL_ "GenSigTimeoutTime" BU_SG_REL_ AMP SG_ 2558929665 Warn_Sound_PopUp_Vol 1500;
BA_ "NetworkRequest" SG_ 2558929665 Warn_Sound_PopUp_Vol 0;
BA_ "Version" SG_ 2558929665 Warn_Sound_PopUp_Vol "20.03.05";
BA_ "Description" SG_ 2558929665 Warn_Sound_LKA_HndsoffSnd "This signal is transmitted from cluster to AMP for LKA HANDS OFF SOUND";
BA_ "GenSigSendType" SG_ 2558929665 Warn_Sound_LKA_HndsoffSnd 4;
BA_ "GenSigStartValue" SG_ 2558929665 Warn_Sound_LKA_HndsoffSnd 3;
BA_ "UserSigValidity" SG_ 2558929665 Warn_Sound_LKA_HndsoffSnd 0;
BA_REL_ "GenSigTimeoutTime" BU_SG_REL_ AMP SG_ 2558929665 Warn_Sound_LKA_HndsoffSnd 1500;
BA_ "NetworkRequest" SG_ 2558929665 Warn_Sound_LKA_HndsoffSnd 0;
BA_ "NetworkRequestHoldingTime" SG_ 2558929665 Warn_Sound_LKA_HndsoffSnd 1;
BA_ "Version" SG_ 2558929665 Warn_Sound_LKA_HndsoffSnd "20.03.05";
BA_ "GenMsgSendType" BO_ 2395189761 0;
BA_ "VFrameFormat" BO_ 2395189761 1;
BA_ "Description" SG_ 2395189761 DATC_Crc10Val "The data area for CRC calculation is based on the data length (DLC) of the message DB.

The CRC shall be calculated over the entire data block (excluding the CRC bytes) including the user data, alive counter and Data ID

 

- CRC Polynomial (0x1021) , Initial Value : 0xFFFF, XOR value : 0x0000, Data ID : Message ID + 0xF800 

- The initial value is for CRC calculation and the message should be sent with the calculated result value. 

- The mathematical expression to 16 bit CRC polynomial is given here. G(x) = x16 + x12 + x5 + 1";
BA_ "GenSigSendType" SG_ 2395189761 DATC_Crc10Val 4;
BA_ "GenSigStartValue" SG_ 2395189761 DATC_Crc10Val 65535;
BA_ "UserSigValidity" SG_ 2395189761 DATC_Crc10Val 3;
BA_ "Version" SG_ 2395189761 DATC_Crc10Val "18.11.08";
BA_ "Description" SG_ 2395189761 DATC_AlvCnt10Val "For the first transmission request for a data element the counter shall be initialized with 0 and shall be incremented by 1 for every subsequent send request. 

When the counter reaches the maximum value(0xFF), then it shall restart with 0 for the next send request";
BA_ "GenSigSendType" SG_ 2395189761 DATC_AlvCnt10Val 4;
BA_ "UserSigValidity" SG_ 2395189761 DATC_AlvCnt10Val 3;
BA_ "Version" SG_ 2395189761 DATC_AlvCnt10Val "18.11.08";
BA_ "Description" SG_ 2395189761 DATC_Typ "HTR CONTROL TYPE

Bit0 (FR Control) : 0 ? ATC / 1 ? MTC

Bit1~2 (Temp) : 0 ? Single / 1 ? Dual / 2 ? 3Zone / 3 ? 4Zone

Bit3~4 (Mode) : 0 ? Single / 1 ? Dual / 2 ? 3Zone / 3 ? 4Zone

Bit5 (Rear Control) : 0 ? None or MTC / 1- ATC

Bit6 (RHD) : 0 ? LHD / 1 ? RHD

Bit7 (EU) : 0 ? Others / 1 ? EU";
BA_ "GenSigSendType" SG_ 2395189761 DATC_Typ 4;
BA_ "UserSigValidity" SG_ 2395189761 DATC_Typ 3;
BA_REL_ "GenSigTimeoutTime" BU_SG_REL_ RLHV SG_ 2395189761 DATC_Typ 1500;
BA_REL_ "GenSigTimeoutTime" BU_SG_REL_ RRHV SG_ 2395189761 DATC_Typ 1500;
BA_REL_ "GenSigTimeoutTime" BU_SG_REL_ AMP SG_ 2395189761 DATC_Typ 1500;
BA_REL_ "GenSigTimeoutTime" BU_SG_REL_ ATS SG_ 2395189761 DATC_Typ 1500;
BA_ "Version" SG_ 2395189761 DATC_Typ "21.07.06";
BA_ "Description" SG_ 2395189761 DATC_Opt1Typ "Bit0 : (ADS) : 0 - Non ADS / 1 - ADS

Bit1 : (AQS) : 0 - Non AQS / 1 ? AQS

Bit2 : (MAX AC) : 0 - Non MAX AC / 1 - MAX AC

Bit3 : (SYNC) : 0 - Non SYNC / 1 - SYNC

Bit4 : (DUST) : 0 - Non AIR PURIFIER / 1 - AIR PURIFIER

Bit5 : (Smart_Vent) : 0 - Non SMART VENT / 1 ? SMART VENT

Bit6 : (CO2) : 0 - Non CO2 / 1 - CO2

Bit7 : (REAR LOCK) : 0 - NON REAR LOCK / 1 - REAR LOCK

HTR CONTROL OPTION";
BA_ "GenSigSendType" SG_ 2395189761 DATC_Opt1Typ 4;
BA_ "UserSigValidity" SG_ 2395189761 DATC_Opt1Typ 3;
BA_REL_ "GenSigTimeoutTime" BU_SG_REL_ ATS SG_ 2395189761 DATC_Opt1Typ 1500;
BA_ "Version" SG_ 2395189761 DATC_Opt1Typ "21.07.06";
BA_ "Description" SG_ 2395189761 DATC_Opt3Typ "This signal indicates Option of HTR Control.



Bit0~1 (Button Type)  : 0 ? Not Display in AVN /

                              1 ? Single (Blower-Temp-Mode) /

                              2 ? Single (Temp-Mode-Blower) / 

                              3 ? Dual · 3zone · 4zone / 

Bit2 : 0 - Defogging USM Not Apply / 1 - Defogging USM Apply 

Bit3 : 0 - Automatic Ventilation USM Not Apply / 1 - Automatic Ventilation USM Apply

Bit4 : 0 ? Auto AirCleaningSystem USM Not Apply / 1 - Auto AirCleaningSystem USM Apply

Bit5 : 0 ? Washer fluid Control USM Not Apply / 1 - Washer fluid Control USM Apply

Bit6~7 : 0 - Haptic Intensity USM Not Apply 

              1 - Haptic Intensity USM Apply (3-Level)

              2 - Haptic Intensity USM Apply (5-Level)

              3 - Reserved

0xFF : Invalid";
BA_ "GenSigSendType" SG_ 2395189761 DATC_Opt3Typ 4;
BA_ "UserSigValidity" SG_ 2395189761 DATC_Opt3Typ 3;
BA_REL_ "GenSigTimeoutTime" BU_SG_REL_ ATS SG_ 2395189761 DATC_Opt3Typ 1500;
BA_ "Version" SG_ 2395189761 DATC_Opt3Typ "21.07.06";
BA_ "Description" SG_ 2395189761 DATC_Opt2Typ "Bit0 : (FRONT BLOWER) : 0 - SINGLE BLOWER / 1 ? DUAL BLOWER

Bit1 : (FRONT AUTO ZONE) : 0 - SINGLE AUTO / 1 - DUAL AUTO

Bit2 : (LCD / NON LCD TYPE) : 0 - NON LCD /  1 - LCD TYPE

Bit3 : (INDIRECT VENT) : 0 - NON INDIRECT VENT /  1 - INDIRECT VENT

HTR CONTROL OPTION";
BA_ "GenSigSendType" SG_ 2395189761 DATC_Opt2Typ 4;
BA_ "UserSigValidity" SG_ 2395189761 DATC_Opt2Typ 3;
BA_REL_ "GenSigTimeoutTime" BU_SG_REL_ ATS SG_ 2395189761 DATC_Opt2Typ 1500;
BA_ "Version" SG_ 2395189761 DATC_Opt2Typ "21.07.06";
BA_ "Description" SG_ 2395189761 DATC_Opt4Typ "This signal indicates Option of HTR Control.



Bit0 (Driver Only Button) :  0 ? NOT Apply / 1 ? Apply

Bit1 (HEAT Button) :  0 ? NOT Apply / 1 ? Apply

Bit2 (Multi-Air Mode) : 0 ? Not Apply / 1 - Apply

Bit3 : (Scheduled Ventilation) : 0 ? Not Apply / 1 ? Apply

0xF : invalid";
BA_ "GenSigSendType" SG_ 2395189761 DATC_Opt4Typ 4;
BA_ "UserSigValidity" SG_ 2395189761 DATC_Opt4Typ 7;
BA_REL_ "GenSigTimeoutTime" BU_SG_REL_ ATS SG_ 2395189761 DATC_Opt4Typ 1500;
BA_ "Version" SG_ 2395189761 DATC_Opt4Typ "19.08.08";
BA_ "Description" SG_ 2395189761 DATC_StrWhlUSMSta "DATC and Steering Wheel heat Control Display request signal";
BA_ "GenSigSendType" SG_ 2395189761 DATC_StrWhlUSMSta 4;
BA_ "UserSigValidity" SG_ 2395189761 DATC_StrWhlUSMSta 3;
BA_REL_ "GenSigTimeoutTime" BU_SG_REL_ SHVU_RR SG_ 2395189761 DATC_StrWhlUSMSta 1500;
BA_ "Version" SG_ 2395189761 DATC_StrWhlUSMSta "18.03.05";
BA_ "Description" SG_ 2395189761 DATC_StrWhlHtngReq "Steering Wheel heat function on/off request";
BA_ "GenSigSendType" SG_ 2395189761 DATC_StrWhlHtngReq 4;
BA_ "UserSigValidity" SG_ 2395189761 DATC_StrWhlHtngReq 3;
BA_ "Version" SG_ 2395189761 DATC_StrWhlHtngReq "18.01.07";
BA_ "GenMsgSendType" BO_ 2365803009 0;
BA_ "GenMsgCycleTime" BO_ 2365803009 1000;
BA_ "GenMsgCycleTimeFast" BO_ 2365803009 0;
BA_ "GenMsgNrOfRepetition" BO_ 2365803009 0;
BA_ "VFrameFormat" BO_ 2365803009 1;
BA_ "Description" SG_ 2365803009 DATC_Crc16Val "The data area for CRC calculation is based on the data length (DLC) of the message DB.

The CRC shall be calculated over the entire data block (excluding the CRC bytes) including the user data, alive counter and Data ID

 

- CRC Polynomial (0x1021) , Initial Value : 0xFFFF, XOR value : 0x0000, Data ID : Message ID + 0xF800 

- The initial value is for CRC calculation and the message should be sent with the calculated result value. 

- The mathematical expression to 16 bit CRC polynomial is given here. G(x) = x16 + x12 + x5 + 1";
BA_ "GenSigStartValue" SG_ 2365803009 DATC_Crc16Val 65535;
BA_ "UserSigValidity" SG_ 2365803009 DATC_Crc16Val 7;
BA_ "Version" SG_ 2365803009 DATC_Crc16Val "19.09.02";
BA_ "Description" SG_ 2365803009 DATC_AlvCnt16Val "For the first transmission request for a data element the counter shall be initialized with 0 and shall be incremented by 1 for every subsequent send request. 

When the counter reaches the maximum value(0xFF), then it shall restart with 0 for the next send request";
BA_ "UserSigValidity" SG_ 2365803009 DATC_AlvCnt16Val 7;
BA_ "Version" SG_ 2365803009 DATC_AlvCnt16Val "19.09.02";
BA_ "Description" SG_ 2365803009 DATC_SwVer1 "This signal idnicates DATC Software Version to display on H_U



Change it to an ASCII code value.";
BA_ "GenSigStartValue" SG_ 2365803009 DATC_SwVer1 127;
BA_ "UserSigValidity" SG_ 2365803009 DATC_SwVer1 7;
BA_ "Version" SG_ 2365803009 DATC_SwVer1 "19.09.02";
BA_ "Description" SG_ 2365803009 DATC_SwVer2 "This signal indicates DATC Software Version to display on H_U



Change it to an ASCII code value.";
BA_ "GenSigStartValue" SG_ 2365803009 DATC_SwVer2 127;
BA_ "UserSigValidity" SG_ 2365803009 DATC_SwVer2 7;
BA_ "Version" SG_ 2365803009 DATC_SwVer2 "19.09.02";
BA_ "Description" SG_ 2365803009 DATC_SwVer3 "This signal indicates DATC Software Version to display on H_U



Change it to an ASCII code value.";
BA_ "GenSigStartValue" SG_ 2365803009 DATC_SwVer3 127;
BA_ "UserSigValidity" SG_ 2365803009 DATC_SwVer3 7;
BA_ "Version" SG_ 2365803009 DATC_SwVer3 "19.09.02";
BA_ "Description" SG_ 2365803009 DATC_Typ2 "Bit0: (AVN Controllable) :  0 ? NOT Apply / 1 ? Apply

Bit1~2 (Multi Auto Blower) : 0 ? Single / 1 ? 2 Step Type / 2 ? 3 Step Type  / 3 - Reserved

Bit3~5 (Front Mode Type) : 0 ? 4 MODE / 1 ? 6MODE / 2 ? 7MODE  / 3 ~ 7 ? Reserved

Bit6 (Fine Dust Sensor) : 0 - Fine Dust Sensor Not Applied / 1 - Fine Dust Sensor Applied.

Bit7~8 (Multi Auto Text) : 0 - Multi Auto State Text Not Applied / 1 - Multi Auto State Text Display Only Applied / 2 - Multi Auto State Text Display & Control Applied / 3 ? Reserved

Bit9 (Mode Def Type) : 0 ? Symbol Type / 1 ? Arrow Type

Bit10~15 : Reserved";
BA_ "UserSigValidity" SG_ 2365803009 DATC_Typ2 7;
BA_REL_ "GenSigTimeoutTime" BU_SG_REL_ ATS SG_ 2365803009 DATC_Typ2 5000;
BA_ "Version" SG_ 2365803009 DATC_Typ2 "21.07.06";
BA_ "GenMsgSendType" BO_ 2365803010 0;
BA_ "GenMsgCycleTime" BO_ 2365803010 1000;
BA_ "GenMsgCycleTimeFast" BO_ 2365803010 0;
BA_ "GenMsgNrOfRepetition" BO_ 2365803010 0;
BA_ "VFrameFormat" BO_ 2365803010 1;
BA_ "GenMsgSendType" BO_ 2365803011 0;
BA_ "GenMsgCycleTime" BO_ 2365803011 1000;
BA_ "GenMsgCycleTimeFast" BO_ 2365803011 0;
BA_ "GenMsgNrOfRepetition" BO_ 2365803011 0;
BA_ "VFrameFormat" BO_ 2365803011 1;
BA_ "GenMsgSendType" BO_ 2365803012 0;
BA_ "GenMsgCycleTime" BO_ 2365803012 1000;
BA_ "GenMsgCycleTimeFast" BO_ 2365803012 0;
BA_ "GenMsgNrOfRepetition" BO_ 2365803012 0;
BA_ "VFrameFormat" BO_ 2365803012 1;
BA_ "GenMsgCycleTime" BO_ 1881 0;
BA_ "GenMsgCycleTimeFast" BO_ 1881 0;
BA_ "GenMsgNrOfRepetition" BO_ 1881 0;
BA_ "DiagResponse" BO_ 1881 1;
BA_ "GenMsgILSupport" BO_ 1881 0;
BA_ "TpMessage" BO_ 1881 1;
BA_ "TpTxIndex" BO_ 1881 122;
BA_ "Description" SG_ 1881 DPSS_GST_Byte0 "TP Index : 122";
BA_ "UsrSigPurpose" SG_ 1881 DPSS_GST_Byte0 4;
BA_ "UserSigValidity" SG_ 1881 DPSS_GST_Byte0 0;
BA_REL_ "GenSigTimeoutTime" BU_SG_REL_ CGW_CCU SG_ 1881 DPSS_GST_Byte0 0;
BA_ "NetworkRequest" SG_ 1881 DPSS_GST_Byte0 0;
BA_ "NetworkRequestHoldingTime" SG_ 1881 DPSS_GST_Byte0 5000;
BA_ "Version" SG_ 1881 DPSS_GST_Byte0 "21.02.04";
BA_ "Description" SG_ 1881 DPSS_GST_Byte2 "TP Index : 122";
BA_ "UsrSigPurpose" SG_ 1881 DPSS_GST_Byte2 4;
BA_ "UserSigValidity" SG_ 1881 DPSS_GST_Byte2 0;
BA_REL_ "GenSigTimeoutTime" BU_SG_REL_ CGW_CCU SG_ 1881 DPSS_GST_Byte2 0;
BA_ "NetworkRequest" SG_ 1881 DPSS_GST_Byte2 0;
BA_ "NetworkRequestHoldingTime" SG_ 1881 DPSS_GST_Byte2 5000;
BA_ "Version" SG_ 1881 DPSS_GST_Byte2 "21.02.04";
BA_ "Description" SG_ 1881 DPSS_GST_Byte3 "TP Index : 122";
BA_ "UsrSigPurpose" SG_ 1881 DPSS_GST_Byte3 4;
BA_ "UserSigValidity" SG_ 1881 DPSS_GST_Byte3 0;
BA_REL_ "GenSigTimeoutTime" BU_SG_REL_ CGW_CCU SG_ 1881 DPSS_GST_Byte3 0;
BA_ "NetworkRequest" SG_ 1881 DPSS_GST_Byte3 0;
BA_ "NetworkRequestHoldingTime" SG_ 1881 DPSS_GST_Byte3 5000;
BA_ "Version" SG_ 1881 DPSS_GST_Byte3 "21.02.04";
BA_ "Description" SG_ 1881 DPSS_GST_Byte4 "TP Index : 122";
BA_ "UsrSigPurpose" SG_ 1881 DPSS_GST_Byte4 4;
BA_ "UserSigValidity" SG_ 1881 DPSS_GST_Byte4 0;
BA_REL_ "GenSigTimeoutTime" BU_SG_REL_ CGW_CCU SG_ 1881 DPSS_GST_Byte4 0;
BA_ "NetworkRequest" SG_ 1881 DPSS_GST_Byte4 0;
BA_ "NetworkRequestHoldingTime" SG_ 1881 DPSS_GST_Byte4 5000;
BA_ "Version" SG_ 1881 DPSS_GST_Byte4 "21.02.04";
BA_ "Description" SG_ 1881 DPSS_GST_Byte5 "TP Index : 122";
BA_ "UsrSigPurpose" SG_ 1881 DPSS_GST_Byte5 4;
BA_ "UserSigValidity" SG_ 1881 DPSS_GST_Byte5 0;
BA_REL_ "GenSigTimeoutTime" BU_SG_REL_ CGW_CCU SG_ 1881 DPSS_GST_Byte5 0;
BA_ "NetworkRequest" SG_ 1881 DPSS_GST_Byte5 0;
BA_ "NetworkRequestHoldingTime" SG_ 1881 DPSS_GST_Byte5 5000;
BA_ "Version" SG_ 1881 DPSS_GST_Byte5 "21.02.04";
BA_ "Description" SG_ 1881 DPSS_GST_Byte6 "TP Index : 122";
BA_ "UsrSigPurpose" SG_ 1881 DPSS_GST_Byte6 4;
BA_ "UserSigValidity" SG_ 1881 DPSS_GST_Byte6 0;
BA_REL_ "GenSigTimeoutTime" BU_SG_REL_ CGW_CCU SG_ 1881 DPSS_GST_Byte6 0;
BA_ "NetworkRequest" SG_ 1881 DPSS_GST_Byte6 0;
BA_ "NetworkRequestHoldingTime" SG_ 1881 DPSS_GST_Byte6 5000;
BA_ "Version" SG_ 1881 DPSS_GST_Byte6 "21.02.04";
BA_ "Description" SG_ 1881 DPSS_GST_Byte7 "TP Index : 122";
BA_ "UsrSigPurpose" SG_ 1881 DPSS_GST_Byte7 4;
BA_ "UserSigValidity" SG_ 1881 DPSS_GST_Byte7 0;
BA_REL_ "GenSigTimeoutTime" BU_SG_REL_ CGW_CCU SG_ 1881 DPSS_GST_Byte7 0;
BA_ "NetworkRequest" SG_ 1881 DPSS_GST_Byte7 0;
BA_ "NetworkRequestHoldingTime" SG_ 1881 DPSS_GST_Byte7 5000;
BA_ "Version" SG_ 1881 DPSS_GST_Byte7 "21.02.04";
BA_ "Description" SG_ 1881 DPSS_GST_Byte1 "TP Index : 122";
BA_ "UsrSigPurpose" SG_ 1881 DPSS_GST_Byte1 4;
BA_ "UserSigValidity" SG_ 1881 DPSS_GST_Byte1 0;
BA_REL_ "GenSigTimeoutTime" BU_SG_REL_ CGW_CCU SG_ 1881 DPSS_GST_Byte1 0;
BA_ "NetworkRequest" SG_ 1881 DPSS_GST_Byte1 0;
BA_ "NetworkRequestHoldingTime" SG_ 1881 DPSS_GST_Byte1 5000;
BA_ "Version" SG_ 1881 DPSS_GST_Byte1 "21.02.04";
BA_ "GenMsgSendType" BO_ 2193667329 0;
BA_ "GenMsgCycleTime" BO_ 2193667329 20;
BA_ "GenMsgCycleTimeFast" BO_ 2193667329 0;
BA_ "GenMsgNrOfRepetition" BO_ 2193667329 0;
BA_ "GenMsgDelayTime" BO_ 2193667329 0;
BA_ "VFrameFormat" BO_ 2193667329 1;
BA_ "Description" SG_ 2193667329 EMS_Crc1Val "The data area for CRC calculation is based on the data length (DLC) of the message DB.

The CRC shall be calculated over the entire data block (excluding the CRC bytes) including the user data, alive counter and Data ID

 

- CRC Polynomial (0x1021) , Initial Value : 0xFFFF, XOR value : 0x0000, Data ID : Message ID + 0xF800 

- The initial value is for CRC calculation and the message should be sent with the calculated result value. 

- The mathematical expression to 16 bit CRC polynomial is given here. G(x) = x16 + x12 + x5 + 1";
BA_ "GenSigStartValue" SG_ 2193667329 EMS_Crc1Val 65535;
BA_ "UserSigValidity" SG_ 2193667329 EMS_Crc1Val 3;
BA_ "RoutingFactor" SG_ 2193667329 EMS_Crc1Val 5;
BA_ "Version" SG_ 2193667329 EMS_Crc1Val "18.11.08";
BA_ "Description" SG_ 2193667329 EMS_AlvCnt1Val "For the first transmission request for a data element the counter shall be initialized with 0 and shall be incremented by 1 for every subsequent send request. 

When the counter reaches the maximum value(0xFF), then it shall restart with 0 for the next send request";
BA_ "UserSigValidity" SG_ 2193667329 EMS_AlvCnt1Val 3;
BA_ "RoutingFactor" SG_ 2193667329 EMS_AlvCnt1Val 5;
BA_ "Version" SG_ 2193667329 EMS_AlvCnt1Val "18.11.08";
BA_ "Description" SG_ 2193667329 ENG_CrctEngTqVal "This signal comprises the actual indicated engine torque (determined by calculation within the engine management system) (lambda control, knock control, catalyst overheating prevention function, temperature influences, TCS, TCU torque intervention etc. being taken into account).



If MSB is 1, this signal is - value.

else, this signal is +value.

0~10bit is used for absolute value.";
BA_ "UserSigValidity" SG_ 2193667329 ENG_CrctEngTqVal 3;
BA_ "RoutingFactor" SG_ 2193667329 ENG_CrctEngTqVal 5;
BA_ "Version" SG_ 2193667329 ENG_CrctEngTqVal "18.01.03";
BA_ "Description" SG_ 2193667329 ENG_StndTqRatioVal "This factor is calculated inside the ECU to express the long-term changes of the engine torque capabilities due to special operating conditions. It takes into consideration mainly the ambient pressure, the ambient air temperature, and the fuel quality. It is defined as follows :



Torque reduction factor = Possible indicated torque for current conditions / Possible indicated torque at standard conditions 



It is used by the TCU to adapt the gearshift strategy.";
BA_ "GenSigStartValue" SG_ 2193667329 ENG_StndTqRatioVal 127;
BA_ "UserSigValidity" SG_ 2193667329 ENG_StndTqRatioVal 3;
BA_ "RoutingFactor" SG_ 2193667329 ENG_StndTqRatioVal 5;
BA_ "Version" SG_ 2193667329 ENG_StndTqRatioVal "17.12.00";
BA_ "Description" SG_ 2193667329 ENG_FrctTqVal "This signal identifies the current engine friction loss torque. It is stored as a function of 'EngClntTempVal' and 'EngSpdVal' (FrctTqVal = f(EngClntTempVal, EngSpdVal)) in terms of an index table.

The index table is corrected depending on the current load under idle conditions.

The signal comprises the following influencing variables:

- Engine friction = f(EngClntTempVal, EngSpdVal, m)

- m= friction coefficient = f(oil,...)

- Charge cycle work

- Valve actuator

- Air conditioner compressor - interference compensation (intermittent)

- Accessories (e.g. water pump, generator, power-steering pump).

The engine friction losses are dominant in conjunction with the following influencing variables.

Peak loads are not included in the calculation.

Consequently, the engine output torque (flywheel torque) is calculated as follows:

TQ = CrctEngTqVal - FrctTqVal



If MSB is 1, this signal is - value.

else, this signal is +value.

0~10bit is used for absolute value.";
BA_ "UserSigValidity" SG_ 2193667329 ENG_FrctTqVal 3;
BA_ "RoutingFactor" SG_ 2193667329 ENG_FrctTqVal 5;
BA_ "Version" SG_ 2193667329 ENG_FrctTqVal "18.01.01";
BA_ "GenMsgSendType" BO_ 2193667330 0;
BA_ "GenMsgCycleTime" BO_ 2193667330 20;
BA_ "GenMsgCycleTimeFast" BO_ 2193667330 0;
BA_ "GenMsgNrOfRepetition" BO_ 2193667330 0;
BA_ "GenMsgDelayTime" BO_ 2193667330 0;
BA_ "VFrameFormat" BO_ 2193667330 1;
BA_ "Description" SG_ 2193667330 ENG_IndTqVal "1) In cars equipped with gasoline engines with ETC system, the signal TQI is determined on the driver’s demand including cruise control and other functions and corresponds to the theoretical

engine torque. The signal comprises influences, such as the ambient temperature, the atmospheric pressure, knock control, the catalyst overheating prevention function and other corrections but it does not depend on TCS/ESC and TCU interventions realised due to reduction of airflow into the

engine cylinders and due to ignition angle adjustment or injection/cylinder shut off.



TQI = f (drivers demand [with the influence of cruise control and other functions without the

influence of TCS/ESC and TCU interventions], ignition angle [without the influence of TCS/

ESC and TCU interventions])



2) In cars equipped with gasoline engines without ETC system, the signal TQI is determined on the basis of the measured air mass flow (MAF) which corresponds to the theoretical engine. The signal comprises influences, such as the ambient temperature, atmospheric pressure, knock control, the catalyst overheating prevention function and other corrections but it does not depend on TCS/ESC and TCU interventions realised due to ignition angle adjustment or injection/cylinder shut off.



TQI = f (MAF, ignition angle [without the influence of TCS/ESC and TCU interventions])



3) In cars equipped with Diesel engines, the signal TQI is determined on the basis of the

driver’s demanding injected Diesel amount including cruise control and other functions but does not including the influence of TCS/ESC and TCU interventions. It corresponds to the theoretical engine torque and comprises influences such as the ambient temperature, the atmospheric pressure and

other corrections.



TQI = f (injected Diesel amount [without TCS/ESC and TCU interventions])



In case of failures of the load signal (either MAF error or other errors depending on the system configuration), a backup value is generated from specific index tables. The backup value mode is identified by the signal F_SUB_TQI.



There is a specific phase relationship between the signals TQI and F_SUB_TQI.



If MSB is 1, this signal is - value.

else, this signal is +value.

0~10bit is used for absolute value.";
BA_ "UserSigValidity" SG_ 2193667330 ENG_IndTqVal 3;
BA_ "RoutingFactor" SG_ 2193667330 ENG_IndTqVal 5;
BA_ "Version" SG_ 2193667330 ENG_IndTqVal "18.01.01";
BA_ "Description" SG_ 2193667330 ENG_IndTqBVal "TQI_B = f (actual torque + with the influence of TCS/ESC [without the influence of TCU interventions])

In cars equipped with gasoline engines with ETC system, the signal TQI is determined on actual torque.

The signal comprises influences, such as the ambient temperature, the atmospheric pressure, knock control, the catalyst overheating prevention function and other corrections but it does not include TCU interventions realised due to reduction of airflow into the engine cylinders and due to ignition angle adjustment or injection/cylinder shut off. But the signal does include TCS/ESC interventions.



If MSB is 1, this signal is - value.

else, this signal is +value.

0~10bit is used for absolute value.";
BA_ "UserSigValidity" SG_ 2193667330 ENG_IndTqBVal 3;
BA_ "RoutingFactor" SG_ 2193667330 ENG_IndTqBVal 5;
BA_ "Version" SG_ 2193667330 ENG_IndTqBVal "18.01.01";
BA_ "Description" SG_ 2193667330 ENG_EngSpdErrSta "This signal identifies an error on searching for a long tooth or on engine speed sensing.

Note : in some cases a limp-home function can be activated in the ECU (the engine speed signal is then based on the camshaft signal), and the engine may run even if an error is present on the crankshaft signal.



There is a specific phase relationship between the signals EngSpdVal and EngSpdErrSta.";
BA_ "UserSigValidity" SG_ 2193667330 ENG_EngSpdErrSta 3;
BA_ "RoutingFactor" SG_ 2193667330 ENG_EngSpdErrSta 5;
BA_ "Version" SG_ 2193667330 ENG_EngSpdErrSta "17.12.00";
BA_ "Description" SG_ 2193667330 ENG_MafErrSta "This signal indicates error on MAF signal";
BA_ "UserSigValidity" SG_ 2193667330 ENG_MafErrSta 3;
BA_ "RoutingFactor" SG_ 2193667330 ENG_MafErrSta 5;
BA_ "Version" SG_ 2193667330 ENG_MafErrSta "17.12.00";
BA_ "Description" SG_ 2193667330 ENG_EtcLmphModSta "When ETC Mal-function occurred, EMS requests Cluster to indicate limphome mode driving and inform driver to go to AS center as soon as possible.

- In case of ETC malfunction, EMS finishes ETC control so that a vehicle goes to limphome mode driving (Forced idle). Since sudden vehicle speed decrease can cause uncomfortable feeling to driver, EMS needs to indicate limphome mode condition on Cluster to induce driver to go to AS center as soon as possible.";
BA_ "UserSigValidity" SG_ 2193667330 ENG_EtcLmphModSta 3;
BA_ "RoutingFactor" SG_ 2193667330 ENG_EtcLmphModSta 5;
BA_ "Version" SG_ 2193667330 ENG_EtcLmphModSta "17.12.00";
BA_ "Description" SG_ 2193667330 ENG_MaxAirconTqVal "EMS defines the maximum allowed A/C compressor torque for drivability and engine safety.

This signal offered to A/C ECU unit only in case of the external variable A/C system installed vehicle.";
BA_ "UserSigValidity" SG_ 2193667330 ENG_MaxAirconTqVal 3;
BA_ "RoutingFactor" SG_ 2193667330 ENG_MaxAirconTqVal 5;
BA_ "Version" SG_ 2193667330 ENG_MaxAirconTqVal "17.12.00";
BA_ "Description" SG_ 2193667330 ENG_AirconPrsrSnsrVal "An EMS senses A/C pitot-tube pressure (between compressor & evaporator) directly with APT sensor.

This signal offered to A/C ECU only in case of the external variable A/C system installed vehicle.";
BA_ "UserSigValidity" SG_ 2193667330 ENG_AirconPrsrSnsrVal 3;
BA_ "RoutingFactor" SG_ 2193667330 ENG_AirconPrsrSnsrVal 5;
BA_ "Version" SG_ 2193667330 ENG_AirconPrsrSnsrVal "17.12.00";
BA_ "Description" SG_ 2193667330 ENG_IsgSta "1. ISG Status expressing CAN message divided by CF_EMS_IsgStat and CF_EMS_IsgStat2 

2. In EMS , CF_EMS_IsgStat and CF_EMS_IsgStat2 do not duplicate the output condition

(EX: If CF_EMS_IsgStat is 01h~07h, CF_EMS_IsgStat2 is 00h)



0x0:ISG is not operating Normal engine operating without ISG/0x1:Idle stop is activated Idle is stopped by ECU during driving/0x2:Automatically started by ECU Engine is automatically started by ECU regardless driver’s volition during idle stop because the condition that ISG function to be prohibited is satisfied, for example SOC is too low./0x3:ISG is prohibited Driver prohibits to activate ISG in order to avoid start lag when he met traffic jam for example./0x4:Fault is existing in ISG There is fault, which is related with ISG. So, idle stop is prohibited and engine started automatically if it is idle stop condition. But for the vehicles that use CF_EMS_ISGStat2, the condition for not-activated battery sensor can be ignored./0x5:Idle stop is inhibited by system automatically for safety and  convenient condition related with battery SOC, brake vacuum pressure etc. ISG function check for EOL./0x6:Auto start is deactivated system automatically to keep safety, Such as door open, hood open and seat belt unlock./0x7:If driver shift gear N to D range without braking to make auto starting. (Economy ISG Only)";
BA_ "UserSigValidity" SG_ 2193667330 ENG_IsgSta 3;
BA_ "RoutingFactor" SG_ 2193667330 ENG_IsgSta 5;
BA_ "Version" SG_ 2193667330 ENG_IsgSta "17.12.02";
BA_ "Description" SG_ 2193667330 ENG_OilLvlSta "This signal indicates the replace time of engine oil.";
BA_ "UserSigValidity" SG_ 2193667330 ENG_OilLvlSta 3;
BA_ "RoutingFactor" SG_ 2193667330 ENG_OilLvlSta 5;
BA_ "Version" SG_ 2193667330 ENG_OilLvlSta "17.12.00";
BA_ "GenMsgSendType" BO_ 2193667331 0;
BA_ "GenMsgCycleTime" BO_ 2193667331 20;
BA_ "GenMsgCycleTimeFast" BO_ 2193667331 0;
BA_ "GenMsgNrOfRepetition" BO_ 2193667331 0;
BA_ "GenMsgDelayTime" BO_ 2193667331 0;
BA_ "VFrameFormat" BO_ 2193667331 1;
BA_ "Description" SG_ 2193667331 ENG_TrgtIdleRpmVal "The stationary target speed depends principally of the engine coolant temperature.

There is a difference between the target speed for manual transmission MT and automatic transmission (AT) in ’neutral’ and AT in ’drive’. 

- Immediately after start the catalyst heating function may increase the target speed 

- The battery charge monitoring increase the target speed.

- For A/C use the target speed may be increased";
BA_ "UserSigValidity" SG_ 2193667331 ENG_TrgtIdleRpmVal 3;
BA_ "RoutingFactor" SG_ 2193667331 ENG_TrgtIdleRpmVal 5;
BA_ "Version" SG_ 2193667331 ENG_TrgtIdleRpmVal "17.12.00";
BA_ "Description" SG_ 2193667331 ENG_GearShftDnDis "This signal represents gear shift down display status. EMS transmits gear shift down status to the cluster.";
BA_ "UserSigValidity" SG_ 2193667331 ENG_GearShftDnDis 3;
BA_ "RoutingFactor" SG_ 2193667331 ENG_GearShftDnDis 5;
BA_ "Version" SG_ 2193667331 ENG_GearShftDnDis "17.12.00";
BA_ "Description" SG_ 2193667331 ENG_DsrGearPosDis "This signal represents desirable gear position of current driving condition.

EMS transmits desirable gear position to the cluster.";
BA_ "UserSigValidity" SG_ 2193667331 ENG_DsrGearPosDis 3;
BA_ "RoutingFactor" SG_ 2193667331 ENG_DsrGearPosDis 5;
BA_ "Version" SG_ 2193667331 ENG_DsrGearPosDis "17.12.00";
BA_ "Description" SG_ 2193667331 ENG_SldFuncSta "This signal indicates that if speed limiter function is active or not.

If the speed limiter function is activated then CF_Ems_SldAct = 1. Although “SLD Main” switch is on, if the Speed limiter function is deactivated then CF_Ems_SldAct should be set to ‘0’.";
BA_ "UserSigValidity" SG_ 2193667331 ENG_SldFuncSta 3;
BA_ "RoutingFactor" SG_ 2193667331 ENG_SldFuncSta 5;
BA_ "Version" SG_ 2193667331 ENG_SldFuncSta "17.12.00";
BA_ "Description" SG_ 2193667331 ENG_SldActnSta "This signal indicates that if positive action of a driver at speed limiter function is active or not. If the positive action is activated then CF_Ems_SldPosAct = 1, which let the current vehicle speed to exceed the limit speed set from a driver.

If kick-down switch isn’t connected to engine ECU directly, ECU can recognize the positive action of a driver from accel pedal position indirectly.

When current vehicle speed exceeds the limit speed, vehicle reaction should be distinguished (e.g. lamp reaction or audio warning signal reaction) depending on the status of “CF_Ems_SldPosAct”";
BA_ "UserSigValidity" SG_ 2193667331 ENG_SldActnSta 3;
BA_ "RoutingFactor" SG_ 2193667331 ENG_SldActnSta 5;
BA_ "Version" SG_ 2193667331 ENG_SldActnSta "17.12.00";
BA_ "Description" SG_ 2193667331 ENG_FuelTnkPrsrSta "This signal indicates that if fuel tank is high Pressure or not.

If the fuel tank is in high pressure status then CF_Ems_HPresStat = ‘1’.

If the fuel tank isn’t in high pressure status then CF_Ems_HPresStat should be set to ‘0’.";
BA_ "UserSigValidity" SG_ 2193667331 ENG_FuelTnkPrsrSta 3;
BA_ "RoutingFactor" SG_ 2193667331 ENG_FuelTnkPrsrSta 5;
BA_ "Version" SG_ 2193667331 ENG_FuelTnkPrsrSta "17.12.00";
BA_ "Description" SG_ 2193667331 ENG_IsgBzrReq "This signal is for Economy Type ISG. This signal is reminding for preventing sudden starting immediately just after engine restarted or driver shift gear N to D range without braking to make auto starting.

 It transfer first 3 times why if valid one is missing.



In the case of 0x1,

Cluster Action : Buzzer on";
BA_ "UserSigValidity" SG_ 2193667331 ENG_IsgBzrReq 3;
BA_ "RoutingFactor" SG_ 2193667331 ENG_IsgBzrReq 5;
BA_ "Version" SG_ 2193667331 ENG_IsgBzrReq "17.12.00";
BA_ "Description" SG_ 2193667331 ENG_IsgFuelCnsmptDis "This signal is the fuel consumption during Idle stop for display to cluster. 

It transfer first 3 times during 0.001L why if valid one is missing, other valid signals are used for extra signals. So, cluster displays 0.001L at only one among three signals.";
BA_ "UserSigValidity" SG_ 2193667331 ENG_IsgFuelCnsmptDis 3;
BA_ "RoutingFactor" SG_ 2193667331 ENG_IsgFuelCnsmptDis 5;
BA_ "Version" SG_ 2193667331 ENG_IsgFuelCnsmptDis "17.12.00";
BA_ "Description" SG_ 2193667331 ENG_FuelCapOpnSta "This signal indicates that if fuel cap is opened or not.

If the fuel cap is opened then CF_Ems_FCopen = 1.

If the fuel tank isn’t opened then CF_Ems_FCopen should be set to ‘0’.";
BA_ "UserSigValidity" SG_ 2193667331 ENG_FuelCapOpnSta 3;
BA_ "RoutingFactor" SG_ 2193667331 ENG_FuelCapOpnSta 5;
BA_ "Version" SG_ 2193667331 ENG_FuelCapOpnSta "17.12.00";
BA_ "Description" SG_ 2193667331 ENG_EcoDrvActvSta "This signal indicates if Active Eco Drive function is active or not.

If Active Eco Drive function is active, then CF_Ems_ActEcoAct =1.";
BA_ "UserSigValidity" SG_ 2193667331 ENG_EcoDrvActvSta 3;
BA_ "RoutingFactor" SG_ 2193667331 ENG_EcoDrvActvSta 5;
BA_ "Version" SG_ 2193667331 ENG_EcoDrvActvSta "17.12.00";
BA_ "Description" SG_ 2193667331 ENG_EngRunSta "This signal is indicating normal engine running status. When engine is normal engine running state out of start, the signal turns to 1, otherwise 0 including engine stop & starting phase(cranking).";
BA_ "UserSigValidity" SG_ 2193667331 ENG_EngRunSta 3;
BA_ "RoutingFactor" SG_ 2193667331 ENG_EngRunSta 5;
BA_ "Version" SG_ 2193667331 ENG_EngRunSta "17.12.00";
BA_ "Description" SG_ 2193667331 ENG_Isg2Sta "1. ISG Status CAN message is divided by CF_EMS_IsgStat and CF_EMS_IsgStat2 

2. CF_EMS_IsgStat and CF_EMS_IsgStat2 do not duplicate the output condition

(EX: If CF_EMS_IsgStat2 is 01h~03h, CF_EMS_IsgStat is 00h)";
BA_ "UserSigValidity" SG_ 2193667331 ENG_Isg2Sta 3;
BA_ "RoutingFactor" SG_ 2193667331 ENG_Isg2Sta 5;
BA_ "Version" SG_ 2193667331 ENG_Isg2Sta "17.12.00";
BA_ "Description" SG_ 2193667331 ENG_IgnOnSta "Status of ignition lock.";
BA_ "GenSigStartValue" SG_ 2193667331 ENG_IgnOnSta 1;
BA_ "UserSigValidity" SG_ 2193667331 ENG_IgnOnSta 3;
BA_ "RoutingFactor" SG_ 2193667331 ENG_IgnOnSta 5;
BA_ "Version" SG_ 2193667331 ENG_IgnOnSta "17.12.00";
BA_ "Description" SG_ 2193667331 ENG_Ack4TcsSta "Monitoring of TCS message; the EMS checks whether at least one new message has been transferred within 500 ms, and whether there is no plausibility error in conjunction with a torque intervention. If this case occurs, the bit is set; otherwise it is reset.



Plausibility check - torque intervention:

- Test criteria:

TCS mode, criteria C1:

(TCS_REQ=1) & (TQI_TCS<FFH) & (MSR_C_REQ = 0) & (TQI_MSR = 00H)

MSR mode, criteria C2:

(TCS_REQ=0) & (TQI_TCS=1’s complement of TQI_MSR) & (MSR_C_REQ = 1) & (TQI_MSR > 00H)

No intervention, criteria C3 :

(TCS_REQ=0) & (TQI_TCS=FFH) & (MSR_C_REQ = 0) & (TQI_MSR = 00H)



- Criterion for error setting:

C1 v C2 v C3 ≠ 1 (none of C1,C2 and C3 is true) for n message transmissions TCS1 (n=10)



- Criterion for remedying an error:

Ignition OFF; transmission is re-started if plausibility is OK for at least one CAN transmission.";
BA_ "UserSigValidity" SG_ 2193667331 ENG_Ack4TcsSta 3;
BA_ "RoutingFactor" SG_ 2193667331 ENG_Ack4TcsSta 5;
BA_ "Version" SG_ 2193667331 ENG_Ack4TcsSta "17.12.00";
BA_ "Description" SG_ 2193667331 ENG_FuelCutOffSta "If the PUC_STAT - bit = 1 then the engine is in fuel cut off state, i.e. e. no injection is applied.";
BA_ "UserSigValidity" SG_ 2193667331 ENG_FuelCutOffSta 3;
BA_ "RoutingFactor" SG_ 2193667331 ENG_FuelCutOffSta 5;
BA_ "Version" SG_ 2193667331 ENG_FuelCutOffSta "17.12.00";
BA_ "Description" SG_ 2193667331 ENG_CrctTqSta "The information TQ_COR_STAT informs the TCS or the TCU whether and to which extent injection and ignition interventions are admitted.



0x0:The desired intervention regarding ignition angle retardation and cylinder shut-off is executed. (Default value)/0x1:The desired intervention regarding ignition angle retardation and cylinder shut-off is executed; however, the requested target torque can not be adjusted precisely (torque steps)/0x2:The torque reduction regarding the ignition angle retardation cannot be completely executed. A cylinder shut-off is not possible at this time. Therefore a remaining torque (as difference between TQI_ASR/GS_REQ and TQI_INTV) is present and cannot be reduced./0x3:Due to a failure detected by a diagnosis function of the engine management system, the desired torque intervention for TCS regarding the ignition angle and cylinder shut-off is no longer executed.The torque intervention is terminated, the engine management system resets the requested engine torque to the TQI value using a ramp.";
BA_ "UserSigValidity" SG_ 2193667331 ENG_CrctTqSta 3;
BA_ "RoutingFactor" SG_ 2193667331 ENG_CrctTqSta 5;
BA_ "Version" SG_ 2193667331 ENG_CrctTqSta "17.12.02";
BA_ "Description" SG_ 2193667331 ENG_AirCompRlySta "The signal RLY_AC identifies the activation of the air conditioner compressor relay.";
BA_ "UserSigValidity" SG_ 2193667331 ENG_AirCompRlySta 3;
BA_ "RoutingFactor" SG_ 2193667331 ENG_AirCompRlySta 5;
BA_ "Version" SG_ 2193667331 ENG_AirCompRlySta "17.12.00";
BA_ "Description" SG_ 2193667331 ENG_LnchCntrlSta "State of Launch Control";
BA_ "UserSigValidity" SG_ 2193667331 ENG_LnchCntrlSta 3;
BA_ "RoutingFactor" SG_ 2193667331 ENG_LnchCntrlSta 5;
BA_ "Version" SG_ 2193667331 ENG_LnchCntrlSta "17.11.00";
BA_ "Description" SG_ 2193667331 ENG_EngSpdVal "This signal is generated by crankshaft segment period measurement (in case of an six-cylinder engine, this corresponds to a crankshaft angle of 120°) and measured with a resolution of 4 us.

This signal is represented as a 16 bit value.



The signal is no";
BA_ "UserSigValidity" SG_ 2193667331 ENG_EngSpdVal 3;
BA_ "RoutingFactor" SG_ 2193667331 ENG_EngSpdVal 5;
BA_ "Version" SG_ 2193667331 ENG_EngSpdVal "17.12.00";
BA_ "Description" SG_ 2193667331 ENG_GearShftUpDis "This signal represents gear shift up display status. EMS transmits gear shift up status to the cluster.";
BA_ "UserSigValidity" SG_ 2193667331 ENG_GearShftUpDis 3;
BA_ "RoutingFactor" SG_ 2193667331 ENG_GearShftUpDis 5;
BA_ "Version" SG_ 2193667331 ENG_GearShftUpDis "17.12.00";
BA_ "GenMsgSendType" BO_ 2193667332 0;
BA_ "GenMsgCycleTime" BO_ 2193667332 20;
BA_ "GenMsgCycleTimeFast" BO_ 2193667332 0;
BA_ "GenMsgNrOfRepetition" BO_ 2193667332 0;
BA_ "GenMsgDelayTime" BO_ 2193667332 0;
BA_ "VFrameFormat" BO_ 2193667332 1;
BA_ "Description" SG_ 2193667332 ENG_TrgtFuelPmpPrsrVal "This signal indicates the Target Pressure of Fuel Pump";
BA_ "UserSigValidity" SG_ 2193667332 ENG_TrgtFuelPmpPrsrVal 3;
BA_ "RoutingFactor" SG_ 2193667332 ENG_TrgtFuelPmpPrsrVal 5;
BA_ "Version" SG_ 2193667332 ENG_TrgtFuelPmpPrsrVal "17.12.00";
BA_ "Description" SG_ 2193667332 ENG_VehSpdHiVal "This signal provides the one wheel velocity with resolution of 1 km/h,

and have 9 bits lengh.

In case of failure of sheel speed sensor, the value 1FF is used as error identifier";
BA_ "UserSigValidity" SG_ 2193667332 ENG_VehSpdHiVal 3;
BA_ "RoutingFactor" SG_ 2193667332 ENG_VehSpdHiVal 5;
BA_ "Version" SG_ 2193667332 ENG_VehSpdHiVal "18.01.01";
BA_ "Description" SG_ 2193667332 ENG_SldSwSta "This signal indicates the status of Speed limiter function.";
BA_ "TimeoutValue" SG_ 2193667332 ENG_SldSwSta "0x0";
BA_ "UserSigValidity" SG_ 2193667332 ENG_SldSwSta 3;
BA_ "RoutingFactor" SG_ 2193667332 ENG_SldSwSta 5;
BA_ "Version" SG_ 2193667332 ENG_SldSwSta "19.12.08";
BA_ "Description" SG_ 2193667332 ENG_SldDrvAlertDisp "If EMS sends the No Sld engaged status or Sld Disengaged status, 

Cluster shall display the status of Sld.";
BA_ "TimeoutValue" SG_ 2193667332 ENG_SldDrvAlertDisp "0x0";
BA_ "UserSigValidity" SG_ 2193667332 ENG_SldDrvAlertDisp 3;
BA_ "RoutingFactor" SG_ 2193667332 ENG_SldDrvAlertDisp 5;
BA_ "Version" SG_ 2193667332 ENG_SldDrvAlertDisp "19.12.08";
BA_ "Description" SG_ 2193667332 ENG_VehSpdLimVal "The vehicle speed which is measured by the EMS has to be sent to CLUSTER. This value is used for limiting speed of EMS. 

EMS limite vehicle speed as this value.";
BA_ "UserSigValidity" SG_ 2193667332 ENG_VehSpdLimVal 3;
BA_ "RoutingFactor" SG_ 2193667332 ENG_VehSpdLimVal 5;
BA_ "Version" SG_ 2193667332 ENG_VehSpdLimVal "18.01.01";
BA_ "Description" SG_ 2193667332 ENG_FuelCnsmptVal "The EMS uses the signal 'FCO' (FUEL CONSUMPTION) to inform other ECUs about the current consumption.";
BA_ "UserSigValidity" SG_ 2193667332 ENG_FuelCnsmptVal 3;
BA_ "RoutingFactor" SG_ 2193667332 ENG_FuelCnsmptVal 5;
BA_ "Version" SG_ 2193667332 ENG_FuelCnsmptVal "17.12.00";
BA_ "GenMsgSendType" BO_ 2214659329 0;
BA_ "GenMsgCycleTime" BO_ 2214659329 50;
BA_ "GenMsgCycleTimeFast" BO_ 2214659329 0;
BA_ "GenMsgNrOfRepetition" BO_ 2214659329 0;
BA_ "VFrameFormat" BO_ 2214659329 1;
BA_ "Description" SG_ 2214659329 EMS_Crc7Val "The data area for CRC calculation is based on the data length (DLC) of the message DB.

The CRC shall be calculated over the entire data block (excluding the CRC bytes) including the user data, alive counter and Data ID

 

- CRC Polynomial (0x1021) , Initial Value : 0xFFFF, XOR value : 0x0000, Data ID : Message ID + 0xF800 

- The initial value is for CRC calculation and the message should be sent with the calculated result value. 

- The mathematical expression to 16 bit CRC polynomial is given here. G(x) = x16 + x12 + x5 + 1";
BA_ "GenSigStartValue" SG_ 2214659329 EMS_Crc7Val 65535;
BA_ "UserSigValidity" SG_ 2214659329 EMS_Crc7Val 3;
BA_ "RoutingFactor" SG_ 2214659329 EMS_Crc7Val 5;
BA_ "Version" SG_ 2214659329 EMS_Crc7Val "18.11.08";
BA_ "Description" SG_ 2214659329 EMS_AlvCnt7Val "For the first transmission request for a data element the counter shall be initialized with 0 and shall be incremented by 1 for every subsequent send request. 

When the counter reaches the maximum value(0xFF), then it shall restart with 0 for the next send request";
BA_ "UserSigValidity" SG_ 2214659329 EMS_AlvCnt7Val 3;
BA_ "RoutingFactor" SG_ 2214659329 EMS_AlvCnt7Val 5;
BA_ "Version" SG_ 2214659329 EMS_AlvCnt7Val "18.11.08";
BA_ "Description" SG_ 2214659329 HEV_IndTqVal "Indicated engine torque after torque coordination(intervention)";
BA_ "UserSigValidity" SG_ 2214659329 HEV_IndTqVal 3;
BA_ "RoutingFactor" SG_ 2214659329 HEV_IndTqVal 5;
BA_ "Version" SG_ 2214659329 HEV_IndTqVal "17.11.00";
BA_ "Description" SG_ 2214659329 HEV_DrvTqVal "Driver's demand torque";
BA_ "UserSigValidity" SG_ 2214659329 HEV_DrvTqVal 3;
BA_ "RoutingFactor" SG_ 2214659329 HEV_DrvTqVal 5;
BA_ "Version" SG_ 2214659329 HEV_DrvTqVal "17.11.00";
BA_ "Description" SG_ 2214659329 HEV_TqStndVal "Standard value for torque scaling in torque interface";
BA_ "UserSigValidity" SG_ 2214659329 HEV_TqStndVal 3;
BA_ "RoutingFactor" SG_ 2214659329 HEV_TqStndVal 5;
BA_ "Version" SG_ 2214659329 HEV_TqStndVal "17.11.00";
BA_ "Description" SG_ 2214659329 HEV_EngSpdErrSta "Engine speed error";
BA_ "UserSigValidity" SG_ 2214659329 HEV_EngSpdErrSta 3;
BA_ "RoutingFactor" SG_ 2214659329 HEV_EngSpdErrSta 5;
BA_ "Version" SG_ 2214659329 HEV_EngSpdErrSta "17.11.00";
BA_ "GenMsgSendType" BO_ 2214659330 0;
BA_ "GenMsgCycleTime" BO_ 2214659330 50;
BA_ "GenMsgCycleTimeFast" BO_ 2214659330 0;
BA_ "GenMsgNrOfRepetition" BO_ 2214659330 0;
BA_ "VFrameFormat" BO_ 2214659330 1;
BA_ "Description" SG_ 2214659330 HEV_EngTqVal "engine torque(BAS)";
BA_ "UserSigValidity" SG_ 2214659330 HEV_EngTqVal 3;
BA_ "RoutingFactor" SG_ 2214659330 HEV_EngTqVal 5;
BA_ "Version" SG_ 2214659330 HEV_EngTqVal "17.11.00";
BA_ "Description" SG_ 2214659330 HEV_FrctTqVal "Friction Loss Torque";
BA_ "UserSigValidity" SG_ 2214659330 HEV_FrctTqVal 3;
BA_ "RoutingFactor" SG_ 2214659330 HEV_FrctTqVal 5;
BA_ "Version" SG_ 2214659330 HEV_FrctTqVal "17.11.00";
BA_ "Description" SG_ 2214659330 HEV_EngSpdVal "Engine Speed";
BA_ "UserSigValidity" SG_ 2214659330 HEV_EngSpdVal 3;
BA_ "RoutingFactor" SG_ 2214659330 HEV_EngSpdVal 5;
BA_ "Version" SG_ 2214659330 HEV_EngSpdVal "17.11.00";
BA_ "Description" SG_ 2214659330 HEV_VehSpdVal "vehicle speed";
BA_ "UserSigValidity" SG_ 2214659330 HEV_VehSpdVal 3;
BA_ "RoutingFactor" SG_ 2214659330 HEV_VehSpdVal 5;
BA_ "Version" SG_ 2214659330 HEV_VehSpdVal "17.11.00";
BA_ "Description" SG_ 2214659330 HEV_EngOpSta "Engine Operating State";
BA_ "UserSigValidity" SG_ 2214659330 HEV_EngOpSta 3;
BA_ "RoutingFactor" SG_ 2214659330 HEV_EngOpSta 5;
BA_ "Version" SG_ 2214659330 HEV_EngOpSta "17.11.00";
BA_ "Description" SG_ 2214659330 HEV_EtcAppSta "This signal indicates the characteristic of an engine system - which kind of fuel is used, whether the ETC (Electronic Throttle Contro) is applied or not.



When a normal engine system (gasoline fuel and no ETC) is used this value is 00H.



※ Start Value : Appropriate value";
BA_ "UserSigValidity" SG_ 2214659330 HEV_EtcAppSta 3;
BA_ "RoutingFactor" SG_ 2214659330 HEV_EtcAppSta 5;
BA_ "Version" SG_ 2214659330 HEV_EtcAppSta "17.11.00";
BA_ "GenMsgSendType" BO_ 2214659331 0;
BA_ "GenMsgCycleTime" BO_ 2214659331 50;
BA_ "GenMsgCycleTimeFast" BO_ 2214659331 0;
BA_ "GenMsgNrOfRepetition" BO_ 2214659331 0;
BA_ "VFrameFormat" BO_ 2214659331 1;
BA_ "UserSigValidity" SG_ 2214659331 HEV_EwpMtrSpdReq 3;
BA_ "RoutingFactor" SG_ 2214659331 HEV_EwpMtrSpdReq 5;
BA_ "Version" SG_ 2214659331 HEV_EwpMtrSpdReq "17.11.00";
BA_ "UserSigValidity" SG_ 2214659331 HEV_EwpMtrCtrlSta 3;
BA_ "RoutingFactor" SG_ 2214659331 HEV_EwpMtrCtrlSta 5;
BA_ "Version" SG_ 2214659331 HEV_EwpMtrCtrlSta "17.11.00";
BA_ "Description" SG_ 2214659331 HEV_O2SnsrPreHeatSta "Flag signalling that O2 sensor pre-heating state";
BA_ "UserSigValidity" SG_ 2214659331 HEV_O2SnsrPreHeatSta 3;
BA_ "RoutingFactor" SG_ 2214659331 HEV_O2SnsrPreHeatSta 5;
BA_ "Version" SG_ 2214659331 HEV_O2SnsrPreHeatSta "17.11.00";
BA_ "Description" SG_ 2214659331 HEV_FuelTnkPrsrErrSta "This signal is Circuit Error of the fuel tank pressure sensor(DTP)";
BA_ "UserSigValidity" SG_ 2214659331 HEV_FuelTnkPrsrErrSta 0;
BA_ "RoutingFactor" SG_ 2214659331 HEV_FuelTnkPrsrErrSta 5;
BA_ "Version" SG_ 2214659331 HEV_FuelTnkPrsrErrSta "17.11.00";
BA_ "Description" SG_ 2214659331 HEV_IntakeAirTempVal "Intake air temperature";
BA_ "UserSigValidity" SG_ 2214659331 HEV_IntakeAirTempVal 3;
BA_ "RoutingFactor" SG_ 2214659331 HEV_IntakeAirTempVal 5;
BA_ "Version" SG_ 2214659331 HEV_IntakeAirTempVal "17.11.00";
BA_ "Description" SG_ 2214659331 HEV_FirstFiringSta "Flag signalling the TDC at the start of the first combustion stroke";
BA_ "UserSigValidity" SG_ 2214659331 HEV_FirstFiringSta 3;
BA_ "RoutingFactor" SG_ 2214659331 HEV_FirstFiringSta 5;
BA_ "Version" SG_ 2214659331 HEV_FirstFiringSta "17.11.00";
BA_ "Description" SG_ 2214659331 HEV_EngFulLoadSta "Engine Full Load Status Flag for Monitoring";
BA_ "UserSigValidity" SG_ 2214659331 HEV_EngFulLoadSta 3;
BA_ "RoutingFactor" SG_ 2214659331 HEV_EngFulLoadSta 5;
BA_ "Version" SG_ 2214659331 HEV_EngFulLoadSta "17.11.00";
BA_ "Description" SG_ 2214659331 HEV_DrvCycActSta "driving cycle status flag for FRF output to other ECU's";
BA_ "UserSigValidity" SG_ 2214659331 HEV_DrvCycActSta 3;
BA_ "RoutingFactor" SG_ 2214659331 HEV_DrvCycActSta 5;
BA_ "Version" SG_ 2214659331 HEV_DrvCycActSta "17.11.00";
BA_ "Description" SG_ 2214659331 HEV_WarmupCycSta "Warm-up cycle status flag for FRF output to other ECU's";
BA_ "UserSigValidity" SG_ 2214659331 HEV_WarmupCycSta 3;
BA_ "RoutingFactor" SG_ 2214659331 HEV_WarmupCycSta 5;
BA_ "Version" SG_ 2214659331 HEV_WarmupCycSta "17.11.00";
BA_ "Description" SG_ 2214659331 HEV_RbmDrvCycSta "DC including standardized vehicle operations for Rate-Based Monitoring for FRF output to other ECU's";
BA_ "UserSigValidity" SG_ 2214659331 HEV_RbmDrvCycSta 3;
BA_ "RoutingFactor" SG_ 2214659331 HEV_RbmDrvCycSta 5;
BA_ "Version" SG_ 2214659331 HEV_RbmDrvCycSta "17.11.00";
BA_ "Description" SG_ 2214659331 HEV_ObdFrzFrmSta "OBD freeze frame acknowledgement

Value Description

Bit 0:Warm up cycle finished(1) / Bit 1:Trip finished(1) / Bit 2:driving cycle started(1) / Bit 3-5:(0)no FRF stored(1)FRF requested by EMS(2)FRF requested by TCU(3)FRF requested by ESC";
BA_ "UserSigValidity" SG_ 2214659331 HEV_ObdFrzFrmSta 3;
BA_ "RoutingFactor" SG_ 2214659331 HEV_ObdFrzFrmSta 5;
BA_ "Version" SG_ 2214659331 HEV_ObdFrzFrmSta "17.11.00";
BA_ "Description" SG_ 2214659331 HEV_EngIdleTrgtSpdVal "Engine Idle Target Speed";
BA_ "UserSigValidity" SG_ 2214659331 HEV_EngIdleTrgtSpdVal 3;
BA_ "RoutingFactor" SG_ 2214659331 HEV_EngIdleTrgtSpdVal 5;
BA_ "Version" SG_ 2214659331 HEV_EngIdleTrgtSpdVal "17.11.00";
BA_ "Description" SG_ 2214659331 HEV_ThrPosSta "Throttle Position Signal";
BA_ "GenSigStartValue" SG_ 2214659331 HEV_ThrPosSta 32;
BA_ "UserSigValidity" SG_ 2214659331 HEV_ThrPosSta 3;
BA_ "RoutingFactor" SG_ 2214659331 HEV_ThrPosSta 5;
BA_ "Version" SG_ 2214659331 HEV_ThrPosSta "17.11.00";
BA_ "GenMsgSendType" BO_ 2214659332 0;
BA_ "GenMsgCycleTime" BO_ 2214659332 50;
BA_ "GenMsgCycleTimeFast" BO_ 2214659332 0;
BA_ "GenMsgNrOfRepetition" BO_ 2214659332 0;
BA_ "VFrameFormat" BO_ 2214659332 1;
BA_ "Description" SG_ 2214659332 HEV_FuelPmpTrgtPrsrVal "Target Pressure (Relative pressure) of Fuel Pump";
BA_ "UserSigValidity" SG_ 2214659332 HEV_FuelPmpTrgtPrsrVal 3;
BA_ "RoutingFactor" SG_ 2214659332 HEV_FuelPmpTrgtPrsrVal 5;
BA_ "Version" SG_ 2214659332 HEV_FuelPmpTrgtPrsrVal "17.11.00";
BA_ "Description" SG_ 2214659332 HEV_AccelPdlVal "The signal is a measure of the Accelerator Pedal value.

The accelerator pedal value is determined via 2 pedal sensors, which are connected mechanically to the accelerator pedal. If the EMS-ECU recognizes that the accelerator pedal is not activated, then the value 00 H is carried over on the CAN. If the EMS-ECU detects that the accelerator pedal is fully activated, then FE H is carried over on the CAN bus.

If an error is detected on both pedal sensor channels, this is identified by the value FFH";
BA_ "UserSigValidity" SG_ 2214659332 HEV_AccelPdlVal 3;
BA_ "RoutingFactor" SG_ 2214659332 HEV_AccelPdlVal 5;
BA_ "Version" SG_ 2214659332 HEV_AccelPdlVal "17.11.00";
BA_ "Description" SG_ 2214659332 HEV_FuelTnkPrsrVal "This signal is pressure of the fuel tank pressure sensor";
BA_ "UserSigValidity" SG_ 2214659332 HEV_FuelTnkPrsrVal 0;
BA_ "RoutingFactor" SG_ 2214659332 HEV_FuelTnkPrsrVal 5;
BA_ "Version" SG_ 2214659332 HEV_FuelTnkPrsrVal "17.11.00";
BA_ "Description" SG_ 2214659332 HEV_FuelCutOffSta "If the CF_Ems_FueCut = 1 then the engine is in fuel cut off state, i.e. no injection is applied.";
BA_ "UserSigValidity" SG_ 2214659332 HEV_FuelCutOffSta 3;
BA_ "RoutingFactor" SG_ 2214659332 HEV_FuelCutOffSta 5;
BA_ "Version" SG_ 2214659332 HEV_FuelCutOffSta "17.11.00";
BA_ "Description" SG_ 2214659332 HEV_FuelCutOffInhbtSta "Engine Fuel cut-off inhibit flag";
BA_ "UserSigValidity" SG_ 2214659332 HEV_FuelCutOffInhbtSta 3;
BA_ "RoutingFactor" SG_ 2214659332 HEV_FuelCutOffInhbtSta 5;
BA_ "Version" SG_ 2214659332 HEV_FuelCutOffInhbtSta "17.11.00";
BA_ "Description" SG_ 2214659332 HEV_FuelCnsmptVal "Fuel Comsumption";
BA_ "UserSigValidity" SG_ 2214659332 HEV_FuelCnsmptVal 3;
BA_ "RoutingFactor" SG_ 2214659332 HEV_FuelCnsmptVal 5;
BA_ "Version" SG_ 2214659332 HEV_FuelCnsmptVal "17.11.00";
BA_ "GenMsgCycleTime" BO_ 2563126017 0;
BA_ "VFrameFormat" BO_ 2563126017 1;
BA_ "GenSigSendType" SG_ 2563126017 AMP_EngASDMasterGain 4;
BA_ "GenSigStartValue" SG_ 2563126017 AMP_EngASDMasterGain 31;
BA_ "UserSigValidity" SG_ 2563126017 AMP_EngASDMasterGain 1;
BA_REL_ "GenSigTimeoutTime" BU_SG_REL_ AMP SG_ 2563126017 AMP_EngASDMasterGain 0;
BA_ "Version" SG_ 2563126017 AMP_EngASDMasterGain "18.12.06";
BA_ "Description" SG_ 2563126017 AMP_Beep1Frequency "Command for Touch Beep Sound Frequency Setting of AVN

-range : 20~20000 Hz";
BA_ "GenSigSendType" SG_ 2563126017 AMP_Beep1Frequency 4;
BA_ "GenSigStartValue" SG_ 2563126017 AMP_Beep1Frequency 65535;
BA_ "UserSigValidity" SG_ 2563126017 AMP_Beep1Frequency 1;
BA_REL_ "GenSigTimeoutTime" BU_SG_REL_ AMP SG_ 2563126017 AMP_Beep1Frequency 0;
BA_ "Version" SG_ 2563126017 AMP_Beep1Frequency "20.03.03";
BA_ "GenMsgCycleTime" BO_ 2563128321 0;
BA_ "VFrameFormat" BO_ 2563128321 1;
BA_ "GenSigSendType" SG_ 2563128321 AMP_QuietModeVolumeStep 4;
BA_ "GenSigStartValue" SG_ 2563128321 AMP_QuietModeVolumeStep 255;
BA_ "UserSigValidity" SG_ 2563128321 AMP_QuietModeVolumeStep 1;
BA_ "Version" SG_ 2563128321 AMP_QuietModeVolumeStep "18.12.06";
BA_ "GenSigSendType" SG_ 2563128321 AMP_ToneScapeY 4;
BA_ "GenSigStartValue" SG_ 2563128321 AMP_ToneScapeY 255;
BA_ "UserSigValidity" SG_ 2563128321 AMP_ToneScapeY 1;
BA_REL_ "GenSigTimeoutTime" BU_SG_REL_ AMP SG_ 2563128321 AMP_ToneScapeY 0;
BA_ "NetworkRequest" SG_ 2563128321 AMP_ToneScapeY 0;
BA_ "Version" SG_ 2563128321 AMP_ToneScapeY "20.07.05";
BA_ "GenSigSendType" SG_ 2563128321 AMP_ToneScapeZ 4;
BA_ "GenSigStartValue" SG_ 2563128321 AMP_ToneScapeZ 255;
BA_ "UserSigValidity" SG_ 2563128321 AMP_ToneScapeZ 1;
BA_REL_ "GenSigTimeoutTime" BU_SG_REL_ AMP SG_ 2563128321 AMP_ToneScapeZ 0;
BA_ "NetworkRequest" SG_ 2563128321 AMP_ToneScapeZ 0;
BA_ "Version" SG_ 2563128321 AMP_ToneScapeZ "20.07.05";
BA_ "Description" SG_ 2563128321 AMP_MasterBeepVolumeLevel "Tuning for MasterBeep Sound Volume Setting.";
BA_ "GenSigSendType" SG_ 2563128321 AMP_MasterBeepVolumeLevel 4;
BA_ "GenSigStartValue" SG_ 2563128321 AMP_MasterBeepVolumeLevel 255;
BA_ "UserSigValidity" SG_ 2563128321 AMP_MasterBeepVolumeLevel 1;
BA_REL_ "GenSigTimeoutTime" BU_SG_REL_ AMP SG_ 2563128321 AMP_MasterBeepVolumeLevel 0;
BA_ "NetworkRequest" SG_ 2563128321 AMP_MasterBeepVolumeLevel 0;
BA_ "Version" SG_ 2563128321 AMP_MasterBeepVolumeLevel "20.07.03";
BA_ "GenSigSendType" SG_ 2563128321 AMP_ToneScapeX 4;
BA_ "GenSigStartValue" SG_ 2563128321 AMP_ToneScapeX 255;
BA_ "UserSigValidity" SG_ 2563128321 AMP_ToneScapeX 1;
BA_REL_ "GenSigTimeoutTime" BU_SG_REL_ AMP SG_ 2563128321 AMP_ToneScapeX 0;
BA_ "NetworkRequest" SG_ 2563128321 AMP_ToneScapeX 0;
BA_ "Version" SG_ 2563128321 AMP_ToneScapeX "20.02.04";
BA_ "GenMsgSendType" BO_ 2470762241 0;
BA_ "VFrameFormat" BO_ 2470762241 1;
BA_ "GenSigSendType" SG_ 2470762241 HU_VehiclePwr 4;
BA_ "UserSigValidity" SG_ 2470762241 HU_VehiclePwr 0;
BA_REL_ "GenSigTimeoutTime" BU_SG_REL_ AMP SG_ 2470762241 HU_VehiclePwr 1500;
BA_ "NetworkRequest" SG_ 2470762241 HU_VehiclePwr 0;
BA_ "NetworkRequestHoldingTime" SG_ 2470762241 HU_VehiclePwr 5000;
BA_ "Version" SG_ 2470762241 HU_VehiclePwr "19.02.08";
BA_ "Description" SG_ 2470762241 HU_BtnShowReq "This signal indicates requesting turn on/off button light for H/Unit related buttons.";
BA_ "GenSigSendType" SG_ 2470762241 HU_BtnShowReq 4;
BA_ "GenSigStartValue" SG_ 2470762241 HU_BtnShowReq 7;
BA_ "UserSigValidity" SG_ 2470762241 HU_BtnShowReq 0;
BA_ "NetworkRequest" SG_ 2470762241 HU_BtnShowReq 0;
BA_ "NetworkRequestHoldingTime" SG_ 2470762241 HU_BtnShowReq 5000;
BA_ "Version" SG_ 2470762241 HU_BtnShowReq "19.11.01";
BA_ "GenMsgCycleTime" BO_ 2315420929 0;
BA_ "VFrameFormat" BO_ 2315420929 1;
BA_ "Description" SG_ 2315420929 AVN_FPFuntionEnableNValueSet "This signal is used for a request to set the value of Menus. This signal requests to set FPM mode.";
BA_ "GenSigSendType" SG_ 2315420929 AVN_FPFuntionEnableNValueSet 4;
BA_ "UserSigValidity" SG_ 2315420929 AVN_FPFuntionEnableNValueSet 0;
BA_REL_ "GenSigTimeoutTime" BU_SG_REL_ FPM SG_ 2315420929 AVN_FPFuntionEnableNValueSet 0;
BA_ "Version" SG_ 2315420929 AVN_FPFuntionEnableNValueSet "19.09.06";
BA_ "Description" SG_ 2315420929 AVN_User2_SecondFPNValueSet "This signal is used for a request to set the value of USM Menus. This signal requests to set Second Finger Print for USER2.";
BA_ "GenSigSendType" SG_ 2315420929 AVN_User2_SecondFPNValueSet 4;
BA_ "UserSigValidity" SG_ 2315420929 AVN_User2_SecondFPNValueSet 0;
BA_REL_ "GenSigTimeoutTime" BU_SG_REL_ FPM SG_ 2315420929 AVN_User2_SecondFPNValueSet 0;
BA_ "Version" SG_ 2315420929 AVN_User2_SecondFPNValueSet "19.09.06";
BA_ "Description" SG_ 2315420929 AVN_User2_ThirdFPNValueSet "This signal is used for a request to set the value of USM Menus. This signal requests to set Third Finger Print for USER2.";
BA_ "GenSigSendType" SG_ 2315420929 AVN_User2_ThirdFPNValueSet 4;
BA_ "UserSigValidity" SG_ 2315420929 AVN_User2_ThirdFPNValueSet 0;
BA_REL_ "GenSigTimeoutTime" BU_SG_REL_ FPM SG_ 2315420929 AVN_User2_ThirdFPNValueSet 0;
BA_ "Version" SG_ 2315420929 AVN_User2_ThirdFPNValueSet "19.09.06";
BA_ "Description" SG_ 2315420929 AVN_FPProcessStopReq "This signal is used for a request to escape the Fingerprint processing.";
BA_ "GenSigSendType" SG_ 2315420929 AVN_FPProcessStopReq 4;
BA_ "UserSigValidity" SG_ 2315420929 AVN_FPProcessStopReq 0;
BA_REL_ "GenSigTimeoutTime" BU_SG_REL_ FPM SG_ 2315420929 AVN_FPProcessStopReq 0;
BA_ "Version" SG_ 2315420929 AVN_FPProcessStopReq "19.09.06";
BA_ "Description" SG_ 2315420929 AVN_AuthorizeCancelReq "This signal is used for a request to escape the Fingerprint processing and cancel the owner authorized result flag.";
BA_ "GenSigSendType" SG_ 2315420929 AVN_AuthorizeCancelReq 4;
BA_ "UserSigValidity" SG_ 2315420929 AVN_AuthorizeCancelReq 0;
BA_REL_ "GenSigTimeoutTime" BU_SG_REL_ FPM SG_ 2315420929 AVN_AuthorizeCancelReq 0;
BA_ "Version" SG_ 2315420929 AVN_AuthorizeCancelReq "19.09.06";
BA_ "Description" SG_ 2315420929 AVN_User1_FirstFPNValueSet "This signal is used for a request to set the value of USM Menus. This signal requests to set First Finger Print for USER1.";
BA_ "GenSigSendType" SG_ 2315420929 AVN_User1_FirstFPNValueSet 4;
BA_ "UserSigValidity" SG_ 2315420929 AVN_User1_FirstFPNValueSet 0;
BA_REL_ "GenSigTimeoutTime" BU_SG_REL_ FPM SG_ 2315420929 AVN_User1_FirstFPNValueSet 0;
BA_ "Version" SG_ 2315420929 AVN_User1_FirstFPNValueSet "19.09.06";
BA_ "Description" SG_ 2315420929 AVN_ISKLearning "This signal is to request ISK Learning to FPM";
BA_ "GenSigSendType" SG_ 2315420929 AVN_ISKLearning 4;
BA_ "UserSigValidity" SG_ 2315420929 AVN_ISKLearning 0;
BA_REL_ "GenSigTimeoutTime" BU_SG_REL_ FPM SG_ 2315420929 AVN_ISKLearning 0;
BA_ "Version" SG_ 2315420929 AVN_ISKLearning "20.05.02";
BA_ "Description" SG_ 2315420929 AVN_ISKLearnFB "This signal is Learning Feedback";
BA_ "GenSigSendType" SG_ 2315420929 AVN_ISKLearnFB 4;
BA_ "UserSigValidity" SG_ 2315420929 AVN_ISKLearnFB 0;
BA_REL_ "GenSigTimeoutTime" BU_SG_REL_ FPM SG_ 2315420929 AVN_ISKLearnFB 0;
BA_ "Version" SG_ 2315420929 AVN_ISKLearnFB "20.05.02";
BA_ "Description" SG_ 2315420929 AVN_FPProcessStartReq "Request to start fingerprint authentication process";
BA_ "GenSigSendType" SG_ 2315420929 AVN_FPProcessStartReq 4;
BA_ "UserSigValidity" SG_ 2315420929 AVN_FPProcessStartReq 0;
BA_REL_ "GenSigTimeoutTime" BU_SG_REL_ FPM SG_ 2315420929 AVN_FPProcessStartReq 0;
BA_ "Version" SG_ 2315420929 AVN_FPProcessStartReq "19.12.08";
BA_ "Description" SG_ 2315420929 AVN_FPFdbckResult "This signal is a feedback on AVN authentication result.";
BA_ "GenSigSendType" SG_ 2315420929 AVN_FPFdbckResult 4;
BA_ "UserSigValidity" SG_ 2315420929 AVN_FPFdbckResult 0;
BA_REL_ "GenSigTimeoutTime" BU_SG_REL_ FPM SG_ 2315420929 AVN_FPFdbckResult 0;
BA_ "Version" SG_ 2315420929 AVN_FPFdbckResult "20.01.01";
BA_ "Description" SG_ 2315420929 AVN_User1_SecondFPNValueSet "This signal is used for a request to set the value of USM Menus. This signal requests to set Second Finger Print for USER1.";
BA_ "GenSigSendType" SG_ 2315420929 AVN_User1_SecondFPNValueSet 4;
BA_ "UserSigValidity" SG_ 2315420929 AVN_User1_SecondFPNValueSet 0;
BA_REL_ "GenSigTimeoutTime" BU_SG_REL_ FPM SG_ 2315420929 AVN_User1_SecondFPNValueSet 0;
BA_ "Version" SG_ 2315420929 AVN_User1_SecondFPNValueSet "19.09.06";
BA_ "Description" SG_ 2315420929 AVN_FPStartUseNvalueSet "This signal is fingerprint recognition - vehicle start interlock setting value(AVNT)";
BA_ "GenSigSendType" SG_ 2315420929 AVN_FPStartUseNvalueSet 4;
BA_ "UserSigValidity" SG_ 2315420929 AVN_FPStartUseNvalueSet 0;
BA_REL_ "GenSigTimeoutTime" BU_SG_REL_ FPM SG_ 2315420929 AVN_FPStartUseNvalueSet 0;
BA_ "Version" SG_ 2315420929 AVN_FPStartUseNvalueSet "20.05.02";
BA_ "Description" SG_ 2315420929 AVN_User1_ThirdFPNValueSet "This signal is used for a request to set the value of USM Menus. This signal requests to set Third Finger Print for USER1.";
BA_ "GenSigSendType" SG_ 2315420929 AVN_User1_ThirdFPNValueSet 4;
BA_ "UserSigValidity" SG_ 2315420929 AVN_User1_ThirdFPNValueSet 0;
BA_REL_ "GenSigTimeoutTime" BU_SG_REL_ FPM SG_ 2315420929 AVN_User1_ThirdFPNValueSet 0;
BA_ "Version" SG_ 2315420929 AVN_User1_ThirdFPNValueSet "19.09.06";
BA_ "Description" SG_ 2315420929 AVN_User2_FirstFPNValueSet "This signal is used for a request to set the value of USM Menus. This signal requests to set First Finger Print for USER2.";
BA_ "GenSigSendType" SG_ 2315420929 AVN_User2_FirstFPNValueSet 4;
BA_ "UserSigValidity" SG_ 2315420929 AVN_User2_FirstFPNValueSet 0;
BA_REL_ "GenSigTimeoutTime" BU_SG_REL_ FPM SG_ 2315420929 AVN_User2_FirstFPNValueSet 0;
BA_ "Version" SG_ 2315420929 AVN_User2_FirstFPNValueSet "19.09.06";
BA_ "GenMsgSendType" BO_ 2470762497 0;
BA_ "VFrameFormat" BO_ 2470762497 1;
BA_ "GenSigSendType" SG_ 2470762497 HU_DistanceUnit 4;
BA_ "GenSigStartValue" SG_ 2470762497 HU_DistanceUnit 3;
BA_ "UserSigValidity" SG_ 2470762497 HU_DistanceUnit 1;
BA_ "NetworkRequest" SG_ 2470762497 HU_DistanceUnit 0;
BA_ "Version" SG_ 2470762497 HU_DistanceUnit "19.02.08";
BA_ "Description" SG_ 2470762497 HU_ThemeType "This signal indicates current H/Unit GUI theme value. 

 

Detail value -GUI Theme matching table, refer to attachement and ES SPEC";
BA_ "GenSigSendType" SG_ 2470762497 HU_ThemeType 4;
BA_ "GenSigStartValue" SG_ 2470762497 HU_ThemeType 15;
BA_ "UserSigValidity" SG_ 2470762497 HU_ThemeType 0;
BA_REL_ "GenSigTimeoutTime" BU_SG_REL_ ATS SG_ 2470762497 HU_ThemeType 1500;
BA_ "Version" SG_ 2470762497 HU_ThemeType "21.08.01";
BA_ "GenSigSendType" SG_ 2470762497 HU_MicActivity 4;
BA_ "GenSigStartValue" SG_ 2470762497 HU_MicActivity 3;
BA_ "UserSigValidity" SG_ 2470762497 HU_MicActivity 0;
BA_ "Version" SG_ 2470762497 HU_MicActivity "19.02.08";
BA_ "Description" SG_ 2470762497 HU_Scheduled_Setting "Information of scheduled update charge setting

The signal means that scheduled update charaging information send to BMS for BMS SOC control";
BA_ "GenSigSendType" SG_ 2470762497 HU_Scheduled_Setting 4;
BA_ "UserSigValidity" SG_ 2470762497 HU_Scheduled_Setting 3;
BA_ "Version" SG_ 2470762497 HU_Scheduled_Setting "19.05.02";
BA_ "Description" SG_ 2470762497 AVN_RSPA_ModeSelect "Signal for User's RSPAⅡ mode setting

RSPAⅡ 모드 선택 메뉴 CCP Focus 및 CCP Confirm or Touch 결과";
BA_ "GenSigSendType" SG_ 2470762497 AVN_RSPA_ModeSelect 4;
BA_ "GenSigStartValue" SG_ 2470762497 AVN_RSPA_ModeSelect 15;
BA_ "UserSigValidity" SG_ 2470762497 AVN_RSPA_ModeSelect 0;
BA_ "Version" SG_ 2470762497 AVN_RSPA_ModeSelect "19.08.08";
BA_ "GenSigSendType" SG_ 2470762497 CF_HU_GPSFlt 4;
BA_ "GenSigStartValue" SG_ 2470762497 CF_HU_GPSFlt 3;
BA_ "UserSigValidity" SG_ 2470762497 CF_HU_GPSFlt 0;
BA_ "Version" SG_ 2470762497 CF_HU_GPSFlt "18.09.04";
BA_ "GenSigSendType" SG_ 2470762497 AVN_RSPA_CancelInput 4;
BA_ "UserSigValidity" SG_ 2470762497 AVN_RSPA_CancelInput 0;
BA_ "Version" SG_ 2470762497 AVN_RSPA_CancelInput "19.05.03";
BA_ "GenSigSendType" SG_ 2470762497 AVN_RSPA_ModeSetStat 4;
BA_ "GenSigStartValue" SG_ 2470762497 AVN_RSPA_ModeSetStat 15;
BA_ "UserSigValidity" SG_ 2470762497 AVN_RSPA_ModeSetStat 0;
BA_ "Version" SG_ 2470762497 AVN_RSPA_ModeSetStat "19.08.08";
BA_ "GenSigSendType" SG_ 2470762497 CAM_Request 4;
BA_ "UserSigValidity" SG_ 2470762497 CAM_Request 3;
BA_ "Version" SG_ 2470762497 CAM_Request "18.10.11";
BA_ "GenSigSendType" SG_ 2470762497 HU_TempUnit 4;
BA_ "GenSigStartValue" SG_ 2470762497 HU_TempUnit 3;
BA_ "UserSigValidity" SG_ 2470762497 HU_TempUnit 1;
BA_ "Version" SG_ 2470762497 HU_TempUnit "18.09.04";
BA_ "GenSigSendType" SG_ 2470762497 AVN_RSPA_Disp_Rdy 4;
BA_ "GenSigStartValue" SG_ 2470762497 AVN_RSPA_Disp_Rdy 3;
BA_ "UserSigValidity" SG_ 2470762497 AVN_RSPA_Disp_Rdy 0;
BA_ "Version" SG_ 2470762497 AVN_RSPA_Disp_Rdy "19.05.03";
BA_ "GenSigSendType" SG_ 2470762497 CF_AVN_ProfileIDRValue 4;
BA_ "GenSigStartValue" SG_ 2470762497 CF_AVN_ProfileIDRValue 15;
BA_ "UserSigValidity" SG_ 2470762497 CF_AVN_ProfileIDRValue 0;
BA_REL_ "GenSigTimeoutTime" BU_SG_REL_ RWPC SG_ 2470762497 CF_AVN_ProfileIDRValue 1500;
BA_REL_ "GenSigTimeoutTime" BU_SG_REL_ PSM SG_ 2470762497 CF_AVN_ProfileIDRValue 1500;
BA_ "Version" SG_ 2470762497 CF_AVN_ProfileIDRValue "18.09.04";
BA_ "GenSigSendType" SG_ 2470762497 HazardFromHUSVM 4;
BA_ "GenSigStartValue" SG_ 2470762497 HazardFromHUSVM 3;
BA_ "UserSigValidity" SG_ 2470762497 HazardFromHUSVM 0;
BA_ "Version" SG_ 2470762497 HazardFromHUSVM "18.09.04";
BA_ "GenSigSendType" SG_ 2470762497 OMUOSMirCtrl 4;
BA_ "GenSigStartValue" SG_ 2470762497 OMUOSMirCtrl 3;
BA_ "UserSigValidity" SG_ 2470762497 OMUOSMirCtrl 0;
BA_ "Version" SG_ 2470762497 OMUOSMirCtrl "18.09.04";
BA_ "GenSigSendType" SG_ 2470762497 AVN_PDW_Input 4;
BA_ "GenSigStartValue" SG_ 2470762497 AVN_PDW_Input 3;
BA_ "UserSigValidity" SG_ 2470762497 AVN_PDW_Input 3;
BA_ "Version" SG_ 2470762497 AVN_PDW_Input "18.09.04";
BA_ "GenSigSendType" SG_ 2470762497 AVN_RSPA_Input 4;
BA_ "GenSigStartValue" SG_ 2470762497 AVN_RSPA_Input 3;
BA_ "UserSigValidity" SG_ 2470762497 AVN_RSPA_Input 3;
BA_ "Version" SG_ 2470762497 AVN_RSPA_Input "18.09.04";
BA_ "GenSigSendType" SG_ 2470762497 AVN_ParkingSW 4;
BA_ "GenSigStartValue" SG_ 2470762497 AVN_ParkingSW 7;
BA_ "UserSigValidity" SG_ 2470762497 AVN_ParkingSW 3;
BA_ "Version" SG_ 2470762497 AVN_ParkingSW "18.09.04";
BA_ "Description" SG_ 2470762497 OTAUIStatus "0x00 : Headunit is booting so, Headunit can't display any state

0x01 : Headunit is normal state, Headunit could display according to CCU command.";
BA_ "GenSigSendType" SG_ 2470762497 OTAUIStatus 4;
BA_ "UserSigValidity" SG_ 2470762497 OTAUIStatus 0;
BA_ "Version" SG_ 2470762497 OTAUIStatus "21.03.02";
BA_ "GenSigSendType" SG_ 2470762497 C_TeleActiveStatus 4;
BA_ "GenSigStartValue" SG_ 2470762497 C_TeleActiveStatus 3;
BA_ "UserSigValidity" SG_ 2470762497 C_TeleActiveStatus 0;
BA_ "Version" SG_ 2470762497 C_TeleActiveStatus "19.04.06";
BA_ "GenSigSendType" SG_ 2470762497 HU_AliveStatus 4;
BA_ "GenSigStartValue" SG_ 2470762497 HU_AliveStatus 3;
BA_ "UserSigValidity" SG_ 2470762497 HU_AliveStatus 0;
BA_REL_ "GenSigTimeoutTime" BU_SG_REL_ DSAU SG_ 2470762497 HU_AliveStatus 1500;
BA_ "NetworkRequest" SG_ 2470762497 HU_AliveStatus 0;
BA_ "Version" SG_ 2470762497 HU_AliveStatus "19.02.08";
BA_ "Description" SG_ 2470762497 C_MtnAlertClu "(NA only) Signals for identifying Maintenance Alert. Active when TMU is provisioned";
BA_ "GenSigSendType" SG_ 2470762497 C_MtnAlertClu 4;
BA_ "GenSigStartValue" SG_ 2470762497 C_MtnAlertClu 3;
BA_ "UserSigValidity" SG_ 2470762497 C_MtnAlertClu 0;
BA_ "Version" SG_ 2470762497 C_MtnAlertClu "19.04.06";
BA_ "GenSigSendType" SG_ 2470762497 HU_RTCCheck 4;
BA_ "GenSigStartValue" SG_ 2470762497 HU_RTCCheck 3;
BA_ "UserSigValidity" SG_ 2470762497 HU_RTCCheck 3;
BA_ "Version" SG_ 2470762497 HU_RTCCheck "18.11.04";
BA_ "Description" SG_ 2470762497 C_SMKBindRequest "SMK bind request command for user profile function";
BA_ "GenSigSendType" SG_ 2470762497 C_SMKBindRequest 4;
BA_ "UserSigValidity" SG_ 2470762497 C_SMKBindRequest 1;
BA_ "Version" SG_ 2470762497 C_SMKBindRequest "19.02.06";
BA_ "GenMsgCycleTime" BO_ 2411985665 0;
BA_ "VFrameFormat" BO_ 2411985665 1;
BA_ "Description" SG_ 2411985665 HU_MoodTherapyDrSeat "Moodtherapy Driver Seat On/Off";
BA_ "GenSigSendType" SG_ 2411985665 HU_MoodTherapyDrSeat 4;
BA_ "UserSigValidity" SG_ 2411985665 HU_MoodTherapyDrSeat 3;
BA_REL_ "GenSigTimeoutTime" BU_SG_REL_ DSAU SG_ 2411985665 HU_MoodTherapyDrSeat 0;
BA_ "RoutingFactor" SG_ 2411985665 HU_MoodTherapyDrSeat 0;
BA_ "Version" SG_ 2411985665 HU_MoodTherapyDrSeat "20.07.13";
BA_ "Description" SG_ 2411985665 HU_VitalityFragrance "Vitality Fragrance On/Off";
BA_ "GenSigSendType" SG_ 2411985665 HU_VitalityFragrance 4;
BA_ "UserSigValidity" SG_ 2411985665 HU_VitalityFragrance 3;
BA_ "RoutingFactor" SG_ 2411985665 HU_VitalityFragrance 0;
BA_ "Version" SG_ 2411985665 HU_VitalityFragrance "20.07.13";
BA_ "Description" SG_ 2411985665 HU_VitalityCurtain "Vitality Curtain On/Off";
BA_ "GenSigSendType" SG_ 2411985665 HU_VitalityCurtain 4;
BA_ "UserSigValidity" SG_ 2411985665 HU_VitalityCurtain 3;
BA_REL_ "GenSigTimeoutTime" BU_SG_REL_ RDC SG_ 2411985665 HU_VitalityCurtain 0;
BA_ "RoutingFactor" SG_ 2411985665 HU_VitalityCurtain 0;
BA_ "Version" SG_ 2411985665 HU_VitalityCurtain "20.07.13";
BA_ "Description" SG_ 2411985665 HU_DelightMoodLamp "Delight MoodLamp On/Off";
BA_ "GenSigSendType" SG_ 2411985665 HU_DelightMoodLamp 4;
BA_ "UserSigValidity" SG_ 2411985665 HU_DelightMoodLamp 3;
BA_ "RoutingFactor" SG_ 2411985665 HU_DelightMoodLamp 0;
BA_ "Version" SG_ 2411985665 HU_DelightMoodLamp "20.07.13";
BA_ "Description" SG_ 2411985665 HU_DelightFragrance "Delight Fragrance On/Off";
BA_ "GenSigSendType" SG_ 2411985665 HU_DelightFragrance 4;
BA_ "UserSigValidity" SG_ 2411985665 HU_DelightFragrance 3;
BA_ "RoutingFactor" SG_ 2411985665 HU_DelightFragrance 0;
BA_ "Version" SG_ 2411985665 HU_DelightFragrance "20.07.13";
BA_ "Description" SG_ 2411985665 HU_DelightCurtain "Delight Curtain On/Off";
BA_ "GenSigSendType" SG_ 2411985665 HU_DelightCurtain 4;
BA_ "UserSigValidity" SG_ 2411985665 HU_DelightCurtain 3;
BA_REL_ "GenSigTimeoutTime" BU_SG_REL_ RDC SG_ 2411985665 HU_DelightCurtain 0;
BA_ "RoutingFactor" SG_ 2411985665 HU_DelightCurtain 0;
BA_ "Version" SG_ 2411985665 HU_DelightCurtain "20.07.13";
BA_ "Description" SG_ 2411985665 HU_MoodTherapyPsSeat "Moodtherapy Passenger Seat On/Off";
BA_ "GenSigSendType" SG_ 2411985665 HU_MoodTherapyPsSeat 4;
BA_ "UserSigValidity" SG_ 2411985665 HU_MoodTherapyPsSeat 3;
BA_REL_ "GenSigTimeoutTime" BU_SG_REL_ ASAU SG_ 2411985665 HU_MoodTherapyPsSeat 0;
BA_ "RoutingFactor" SG_ 2411985665 HU_MoodTherapyPsSeat 0;
BA_ "Version" SG_ 2411985665 HU_MoodTherapyPsSeat "20.07.13";
BA_ "Description" SG_ 2411985665 HU_CareMoodLamp "Care MoodLamp On/Off";
BA_ "GenSigSendType" SG_ 2411985665 HU_CareMoodLamp 4;
BA_ "UserSigValidity" SG_ 2411985665 HU_CareMoodLamp 3;
BA_ "RoutingFactor" SG_ 2411985665 HU_CareMoodLamp 0;
BA_ "Version" SG_ 2411985665 HU_CareMoodLamp "20.07.13";
BA_ "Description" SG_ 2411985665 HU_CareFragrance "Care Fragrance On/Off";
BA_ "GenSigSendType" SG_ 2411985665 HU_CareFragrance 4;
BA_ "UserSigValidity" SG_ 2411985665 HU_CareFragrance 3;
BA_ "RoutingFactor" SG_ 2411985665 HU_CareFragrance 0;
BA_ "Version" SG_ 2411985665 HU_CareFragrance "20.07.13";
BA_ "Description" SG_ 2411985665 HU_CareMassage "Care Massage On/Off";
BA_ "GenSigSendType" SG_ 2411985665 HU_CareMassage 4;
BA_ "UserSigValidity" SG_ 2411985665 HU_CareMassage 3;
BA_REL_ "GenSigTimeoutTime" BU_SG_REL_ RLPSM SG_ 2411985665 HU_CareMassage 0;
BA_REL_ "GenSigTimeoutTime" BU_SG_REL_ DSAU SG_ 2411985665 HU_CareMassage 0;
BA_REL_ "GenSigTimeoutTime" BU_SG_REL_ ASAU SG_ 2411985665 HU_CareMassage 0;
BA_ "RoutingFactor" SG_ 2411985665 HU_CareMassage 0;
BA_ "Version" SG_ 2411985665 HU_CareMassage "20.07.13";
BA_ "Description" SG_ 2411985665 HU_CareCurtain "Care Curtain On/Off";
BA_ "GenSigSendType" SG_ 2411985665 HU_CareCurtain 4;
BA_ "UserSigValidity" SG_ 2411985665 HU_CareCurtain 3;
BA_REL_ "GenSigTimeoutTime" BU_SG_REL_ RDC SG_ 2411985665 HU_CareCurtain 0;
BA_ "RoutingFactor" SG_ 2411985665 HU_CareCurtain 0;
BA_ "Version" SG_ 2411985665 HU_CareCurtain "20.07.13";
BA_ "Description" SG_ 2411985665 HU_ComfortMoodLamp "Comfort MoodLamp On/Off";
BA_ "GenSigSendType" SG_ 2411985665 HU_ComfortMoodLamp 4;
BA_ "UserSigValidity" SG_ 2411985665 HU_ComfortMoodLamp 3;
BA_ "RoutingFactor" SG_ 2411985665 HU_ComfortMoodLamp 0;
BA_ "Version" SG_ 2411985665 HU_ComfortMoodLamp "20.07.13";
BA_ "Description" SG_ 2411985665 HU_ComfortFragrance "Comfort Fragrance On/Off";
BA_ "GenSigSendType" SG_ 2411985665 HU_ComfortFragrance 4;
BA_ "UserSigValidity" SG_ 2411985665 HU_ComfortFragrance 3;
BA_ "RoutingFactor" SG_ 2411985665 HU_ComfortFragrance 0;
BA_ "Version" SG_ 2411985665 HU_ComfortFragrance "20.07.13";
BA_ "Description" SG_ 2411985665 HU_ComfortMassage "Comfort Massage On/Off";
BA_ "GenSigSendType" SG_ 2411985665 HU_ComfortMassage 4;
BA_ "UserSigValidity" SG_ 2411985665 HU_ComfortMassage 3;
BA_REL_ "GenSigTimeoutTime" BU_SG_REL_ RLPSM SG_ 2411985665 HU_ComfortMassage 0;
BA_REL_ "GenSigTimeoutTime" BU_SG_REL_ DSAU SG_ 2411985665 HU_ComfortMassage 0;
BA_REL_ "GenSigTimeoutTime" BU_SG_REL_ ASAU SG_ 2411985665 HU_ComfortMassage 0;
BA_ "RoutingFactor" SG_ 2411985665 HU_ComfortMassage 0;
BA_ "Version" SG_ 2411985665 HU_ComfortMassage "20.07.13";
BA_ "Description" SG_ 2411985665 HU_ComfortCurtain "Comfort Curtain On/Off";
BA_ "GenSigSendType" SG_ 2411985665 HU_ComfortCurtain 4;
BA_ "UserSigValidity" SG_ 2411985665 HU_ComfortCurtain 3;
BA_REL_ "GenSigTimeoutTime" BU_SG_REL_ RDC SG_ 2411985665 HU_ComfortCurtain 0;
BA_ "RoutingFactor" SG_ 2411985665 HU_ComfortCurtain 0;
BA_ "Version" SG_ 2411985665 HU_ComfortCurtain "20.07.13";
BA_ "Description" SG_ 2411985665 HU_MoodTherapyMode "Moodtherapy Mode Change Signal";
BA_ "GenSigSendType" SG_ 2411985665 HU_MoodTherapyMode 4;
BA_ "UserSigValidity" SG_ 2411985665 HU_MoodTherapyMode 3;
BA_REL_ "GenSigTimeoutTime" BU_SG_REL_ RLPSM SG_ 2411985665 HU_MoodTherapyMode 0;
BA_REL_ "GenSigTimeoutTime" BU_SG_REL_ RDC SG_ 2411985665 HU_MoodTherapyMode 0;
BA_REL_ "GenSigTimeoutTime" BU_SG_REL_ DSAU SG_ 2411985665 HU_MoodTherapyMode 0;
BA_REL_ "GenSigTimeoutTime" BU_SG_REL_ ASAU SG_ 2411985665 HU_MoodTherapyMode 0;
BA_ "RoutingFactor" SG_ 2411985665 HU_MoodTherapyMode 0;
BA_ "Version" SG_ 2411985665 HU_MoodTherapyMode "20.07.13";
BA_ "Description" SG_ 2411985665 HU_MoodTherapyRlSeat "Moodtherapy RearLeft Seat On/Off";
BA_ "GenSigSendType" SG_ 2411985665 HU_MoodTherapyRlSeat 4;
BA_ "UserSigValidity" SG_ 2411985665 HU_MoodTherapyRlSeat 3;
BA_REL_ "GenSigTimeoutTime" BU_SG_REL_ RLPSM SG_ 2411985665 HU_MoodTherapyRlSeat 0;
BA_ "RoutingFactor" SG_ 2411985665 HU_MoodTherapyRlSeat 0;
BA_ "Version" SG_ 2411985665 HU_MoodTherapyRlSeat "20.07.13";
BA_ "Description" SG_ 2411985665 HU_MoodTherapyRrSeat "Moodtherapy Rear Right Seat On/Off";
BA_ "GenSigSendType" SG_ 2411985665 HU_MoodTherapyRrSeat 4;
BA_ "UserSigValidity" SG_ 2411985665 HU_MoodTherapyRrSeat 3;
BA_REL_ "GenSigTimeoutTime" BU_SG_REL_ RLPSM SG_ 2411985665 HU_MoodTherapyRrSeat 0;
BA_ "RoutingFactor" SG_ 2411985665 HU_MoodTherapyRrSeat 0;
BA_ "Version" SG_ 2411985665 HU_MoodTherapyRrSeat "20.07.13";
BA_ "Description" SG_ 2411985665 HU_VitalityMoodLamp "Vitality MoodLamp On/Off";
BA_ "GenSigSendType" SG_ 2411985665 HU_VitalityMoodLamp 4;
BA_ "UserSigValidity" SG_ 2411985665 HU_VitalityMoodLamp 3;
BA_ "RoutingFactor" SG_ 2411985665 HU_VitalityMoodLamp 0;
BA_ "Version" SG_ 2411985665 HU_VitalityMoodLamp "20.07.13";
BA_ "GenMsgCycleTime" BO_ 2458167297 0;
BA_ "VFrameFormat" BO_ 2458167297 1;
BA_ "GenSigSendType" SG_ 2458167297 CF_AVN_FCANValueSet 4;
BA_ "UserSigValidity" SG_ 2458167297 CF_AVN_FCANValueSet 3;
BA_ "Version" SG_ 2458167297 CF_AVN_FCANValueSet "18.09.04";
BA_ "GenSigSendType" SG_ 2458167297 CF_AVN_DAWModeNValueSet 4;
BA_ "UserSigValidity" SG_ 2458167297 CF_AVN_DAWModeNValueSet 3;
BA_ "Version" SG_ 2458167297 CF_AVN_DAWModeNValueSet "18.09.04";
BA_ "GenSigSendType" SG_ 2458167297 CF_AVN_HDANValueSet 4;
BA_ "UserSigValidity" SG_ 2458167297 CF_AVN_HDANValueSet 3;
BA_ "Version" SG_ 2458167297 CF_AVN_HDANValueSet "18.09.04";
BA_ "GenSigSendType" SG_ 2458167297 CF_AVN_BCWNValueSet 4;
BA_ "UserSigValidity" SG_ 2458167297 CF_AVN_BCWNValueSet 3;
BA_ "Version" SG_ 2458167297 CF_AVN_BCWNValueSet "18.09.04";
BA_ "GenSigSendType" SG_ 2458167297 CF_AVN_NSCCCamNValueSet 4;
BA_ "UserSigValidity" SG_ 2458167297 CF_AVN_NSCCCamNValueSet 3;
BA_ "Version" SG_ 2458167297 CF_AVN_NSCCCamNValueSet "18.09.04";
BA_ "GenSigSendType" SG_ 2458167297 CF_AVN_ProximitySesnsorSet 4;
BA_ "UserSigValidity" SG_ 2458167297 CF_AVN_ProximitySesnsorSet 3;
BA_ "Version" SG_ 2458167297 CF_AVN_ProximitySesnsorSet "18.09.04";
BA_ "GenSigSendType" SG_ 2458167297 CF_AVN_BCANValueSet 4;
BA_ "UserSigValidity" SG_ 2458167297 CF_AVN_BCANValueSet 3;
BA_ "Version" SG_ 2458167297 CF_AVN_BCANValueSet "18.09.04";
BA_ "GenSigSendType" SG_ 2458167297 CF_AVN_ISLWNValueSet 4;
BA_ "UserSigValidity" SG_ 2458167297 CF_AVN_ISLWNValueSet 3;
BA_ "Version" SG_ 2458167297 CF_AVN_ISLWNValueSet "18.09.04";
BA_ "GenSigSendType" SG_ 2458167297 CF_AVN_WarningTimingNValueSet 4;
BA_ "UserSigValidity" SG_ 2458167297 CF_AVN_WarningTimingNValueSet 3;
BA_REL_ "GenSigTimeoutTime" BU_SG_REL_ ICC SG_ 2458167297 CF_AVN_WarningTimingNValueSet 0;
BA_ "Version" SG_ 2458167297 CF_AVN_WarningTimingNValueSet "18.09.04";
BA_ "GenSigSendType" SG_ 2458167297 CF_AVN_LFANValueSet 4;
BA_ "UserSigValidity" SG_ 2458167297 CF_AVN_LFANValueSet 3;
BA_ "Version" SG_ 2458167297 CF_AVN_LFANValueSet "18.09.04";
BA_ "GenSigSendType" SG_ 2458167297 CF_AVN_NCC_USM_set 4;
BA_ "UserSigValidity" SG_ 2458167297 CF_AVN_NCC_USM_set 3;
BA_ "Version" SG_ 2458167297 CF_AVN_NCC_USM_set "18.09.04";
BA_ "GenSigSendType" SG_ 2458167297 CF_AVN_TirePressUnitNValueSet 4;
BA_ "UserSigValidity" SG_ 2458167297 CF_AVN_TirePressUnitNValueSet 3;
BA_ "Version" SG_ 2458167297 CF_AVN_TirePressUnitNValueSet "18.09.04";
BA_ "GenSigSendType" SG_ 2458167297 CF_AVN_PCANValueSet 4;
BA_ "UserSigValidity" SG_ 2458167297 CF_AVN_PCANValueSet 3;
BA_ "Version" SG_ 2458167297 CF_AVN_PCANValueSet "18.09.04";
BA_ "GenSigSendType" SG_ 2458167297 CF_AVN_TunnelClimateNvalueSet 4;
BA_ "UserSigValidity" SG_ 2458167297 CF_AVN_TunnelClimateNvalueSet 3;
BA_ "Version" SG_ 2458167297 CF_AVN_TunnelClimateNvalueSet "18.09.04";
BA_ "GenSigSendType" SG_ 2458167297 CF_AVN_NSCCCrvNValueSet 4;
BA_ "UserSigValidity" SG_ 2458167297 CF_AVN_NSCCCrvNValueSet 3;
BA_ "Version" SG_ 2458167297 CF_AVN_NSCCCrvNValueSet "18.09.04";
BA_ "GenSigSendType" SG_ 2458167297 CF_AVN_BCWSndWanNValueSet 4;
BA_ "UserSigValidity" SG_ 2458167297 CF_AVN_BCWSndWanNValueSet 3;
BA_ "Version" SG_ 2458167297 CF_AVN_BCWSndWanNValueSet "18.09.04";
BA_ "GenSigSendType" SG_ 2458167297 CF_AVN_RCCWNValueSet 4;
BA_ "UserSigValidity" SG_ 2458167297 CF_AVN_RCCWNValueSet 3;
BA_ "Version" SG_ 2458167297 CF_AVN_RCCWNValueSet "18.09.04";
BA_ "GenSigSendType" SG_ 2458167297 CF_AVN_LkaModeNValueSet 4;
BA_ "UserSigValidity" SG_ 2458167297 CF_AVN_LkaModeNValueSet 3;
BA_ "Version" SG_ 2458167297 CF_AVN_LkaModeNValueSet "18.09.04";
BA_ "GenSigSendType" SG_ 2458167297 CF_AVN_PasSpkrLvNValueSet 4;
BA_ "UserSigValidity" SG_ 2458167297 CF_AVN_PasSpkrLvNValueSet 3;
BA_ "Version" SG_ 2458167297 CF_AVN_PasSpkrLvNValueSet "18.09.04";
BA_ "GenSigSendType" SG_ 2458167297 CF_AVN_PDWAutoOnNValueSet 4;
BA_ "UserSigValidity" SG_ 2458167297 CF_AVN_PDWAutoOnNValueSet 3;
BA_ "Version" SG_ 2458167297 CF_AVN_PDWAutoOnNValueSet "18.09.04";
BA_ "GenSigSendType" SG_ 2458167297 C_TempUnit 4;
BA_ "UserSigValidity" SG_ 2458167297 C_TempUnit 3;
BA_ "Version" SG_ 2458167297 C_TempUnit "18.12.03";
BA_ "GenSigSendType" SG_ 2458167297 CF_AVN_AdasVolumeNValueSet 4;
BA_ "UserSigValidity" SG_ 2458167297 CF_AVN_AdasVolumeNValueSet 3;
BA_ "Version" SG_ 2458167297 CF_AVN_AdasVolumeNValueSet "18.04.02";
BA_ "GenSigSendType" SG_ 2458167297 CF_AVN_SCCDrvModeNValueSet 4;
BA_ "UserSigValidity" SG_ 2458167297 CF_AVN_SCCDrvModeNValueSet 3;
BA_ "Version" SG_ 2458167297 CF_AVN_SCCDrvModeNValueSet "18.09.04";
BA_ "GenMsgCycleTime" BO_ 1201 0;
BA_ "GenMsgNrOfRepetition" BO_ 1201 0;
BA_ "GenMsgDelayTime" BO_ 1201 10;
BA_ "Description" SG_ 1201 ICU_Crc1Val "The data area for CRC calculation is based on the data length (DLC) of the message DB.

The CRC shall be calculated over the entire data block (excluding the CRC bytes) including the user data, alive counter and Data ID 

 

- CRC Polynomial (0x1D) , Initial Value : 0x00, XOR value : 0xFF, Data ID Mode : Both, Data ID : Message ID + 0xF800 

- The initial value is for CRC calculation and the message should be sent with the calculated result value. 

The mathematical expression to 8 bit CRC polynomial is given here. G(x) = x8 + x4 + x3 + x2 + 1";
BA_ "GenSigSendType" SG_ 1201 ICU_Crc1Val 2;
BA_ "GenSigStartValue" SG_ 1201 ICU_Crc1Val 255;
BA_ "UserSigValidity" SG_ 1201 ICU_Crc1Val 0;
BA_REL_ "GenSigTimeoutTime" BU_SG_REL_ vHS_M SG_ 1201 ICU_Crc1Val 0;
BA_ "Version" SG_ 1201 ICU_Crc1Val "20.08.06";
BA_ "Description" SG_ 1201 ICU_AlvCnt1Val "For the first transmission request for a data element the counter shall be initialized with 0 and shall be incremented by 1

for every subsequent send request. When the counter reaches the maximum value(0xE), then it shall restart with 0 for the next send request";
BA_ "GenSigSendType" SG_ 1201 ICU_AlvCnt1Val 2;
BA_ "UserSigValidity" SG_ 1201 ICU_AlvCnt1Val 0;
BA_ "Version" SG_ 1201 ICU_AlvCnt1Val "20.08.06";
BA_ "Description" SG_ 1201 ICU_Update_Enable "OTA Update enable, battery condition is OK

0x0 : Default

0x1 : Yes

0x2 : No(SOC)

0x3 : No(SOH)

0x4 : No(Temp)";
BA_ "GenSigSendType" SG_ 1201 ICU_Update_Enable 2;
BA_ "UserSigValidity" SG_ 1201 ICU_Update_Enable 0;
BA_ "Version" SG_ 1201 ICU_Update_Enable "21.01.07";
BA_ "GenMsgSendType" BO_ 715 0;
BA_ "Description" SG_ 715 RRPSS_L_WalkInSwitchSts "Rear Right Walk In Switch Status";
BA_ "GenSigSendType" SG_ 715 RRPSS_L_WalkInSwitchSts 4;
BA_ "UserSigValidity" SG_ 715 RRPSS_L_WalkInSwitchSts 0;
BA_REL_ "GenSigTimeoutTime" BU_SG_REL_ APSM SG_ 715 RRPSS_L_WalkInSwitchSts 1500;
BA_ "NetworkRequest" SG_ 715 RRPSS_L_WalkInSwitchSts 0;
BA_ "NetworkRequestHoldingTime" SG_ 715 RRPSS_L_WalkInSwitchSts 5000;
BA_ "Version" SG_ 715 RRPSS_L_WalkInSwitchSts "21.04.00";
BA_ "Description" SG_ 715 RRPSS_L_AstRclFwdMvBtn "Rear Right Recliner Forward Move Button";
BA_ "GenSigSendType" SG_ 715 RRPSS_L_AstRclFwdMvBtn 4;
BA_ "UserSigValidity" SG_ 715 RRPSS_L_AstRclFwdMvBtn 0;
BA_REL_ "GenSigTimeoutTime" BU_SG_REL_ APSM SG_ 715 RRPSS_L_AstRclFwdMvBtn 1500;
BA_ "NetworkRequest" SG_ 715 RRPSS_L_AstRclFwdMvBtn 0;
BA_ "NetworkRequestHoldingTime" SG_ 715 RRPSS_L_AstRclFwdMvBtn 5000;
BA_ "Version" SG_ 715 RRPSS_L_AstRclFwdMvBtn "21.04.00";
BA_ "Description" SG_ 715 RRPSS_L_AstRclBwdMvBtn "Rear Right Recliner Backward Move Button";
BA_ "GenSigSendType" SG_ 715 RRPSS_L_AstRclBwdMvBtn 4;
BA_ "UserSigValidity" SG_ 715 RRPSS_L_AstRclBwdMvBtn 0;
BA_REL_ "GenSigTimeoutTime" BU_SG_REL_ APSM SG_ 715 RRPSS_L_AstRclBwdMvBtn 1500;
BA_ "NetworkRequest" SG_ 715 RRPSS_L_AstRclBwdMvBtn 0;
BA_ "NetworkRequestHoldingTime" SG_ 715 RRPSS_L_AstRclBwdMvBtn 5000;
BA_ "Version" SG_ 715 RRPSS_L_AstRclBwdMvBtn "21.04.00";
BA_ "Description" SG_ 715 RRPSS_L_AstSldFwdMvBtn "Rear Right Slide Forward Move Button";
BA_ "GenSigSendType" SG_ 715 RRPSS_L_AstSldFwdMvBtn 4;
BA_ "UserSigValidity" SG_ 715 RRPSS_L_AstSldFwdMvBtn 0;
BA_REL_ "GenSigTimeoutTime" BU_SG_REL_ APSM SG_ 715 RRPSS_L_AstSldFwdMvBtn 1500;
BA_ "NetworkRequest" SG_ 715 RRPSS_L_AstSldFwdMvBtn 0;
BA_ "NetworkRequestHoldingTime" SG_ 715 RRPSS_L_AstSldFwdMvBtn 5000;
BA_ "Version" SG_ 715 RRPSS_L_AstSldFwdMvBtn "21.04.00";
BA_ "Description" SG_ 715 RRPSS_L_AstSldBwdMvBtn "Rear Right Slide Backward Move Button";
BA_ "GenSigSendType" SG_ 715 RRPSS_L_AstSldBwdMvBtn 4;
BA_ "UserSigValidity" SG_ 715 RRPSS_L_AstSldBwdMvBtn 0;
BA_REL_ "GenSigTimeoutTime" BU_SG_REL_ APSM SG_ 715 RRPSS_L_AstSldBwdMvBtn 1500;
BA_ "NetworkRequest" SG_ 715 RRPSS_L_AstSldBwdMvBtn 0;
BA_ "NetworkRequestHoldingTime" SG_ 715 RRPSS_L_AstSldBwdMvBtn 5000;
BA_ "Version" SG_ 715 RRPSS_L_AstSldBwdMvBtn "21.04.00";
BA_ "Description" SG_ 715 RRPSS_L_AstHgtUpMvBtn "Rear Right Height Up Move Button";
BA_ "GenSigSendType" SG_ 715 RRPSS_L_AstHgtUpMvBtn 4;
BA_ "UserSigValidity" SG_ 715 RRPSS_L_AstHgtUpMvBtn 0;
BA_REL_ "GenSigTimeoutTime" BU_SG_REL_ APSM SG_ 715 RRPSS_L_AstHgtUpMvBtn 1500;
BA_ "NetworkRequest" SG_ 715 RRPSS_L_AstHgtUpMvBtn 0;
BA_ "NetworkRequestHoldingTime" SG_ 715 RRPSS_L_AstHgtUpMvBtn 5000;
BA_ "Version" SG_ 715 RRPSS_L_AstHgtUpMvBtn "21.04.00";
BA_ "Description" SG_ 715 RRPSS_L_AstHRestFwdMvBtn "Rear Right HeadRest Forward Move Button";
BA_ "GenSigSendType" SG_ 715 RRPSS_L_AstHRestFwdMvBtn 4;
BA_ "UserSigValidity" SG_ 715 RRPSS_L_AstHRestFwdMvBtn 0;
BA_REL_ "GenSigTimeoutTime" BU_SG_REL_ APSM SG_ 715 RRPSS_L_AstHRestFwdMvBtn 1500;
BA_ "NetworkRequest" SG_ 715 RRPSS_L_AstHRestFwdMvBtn 0;
BA_ "NetworkRequestHoldingTime" SG_ 715 RRPSS_L_AstHRestFwdMvBtn 5000;
BA_ "Version" SG_ 715 RRPSS_L_AstHRestFwdMvBtn "21.04.00";
BA_ "Description" SG_ 715 RRPSS_L_AstHgtDnMvBtn "Rear Right Height Down Move Button";
BA_ "GenSigSendType" SG_ 715 RRPSS_L_AstHgtDnMvBtn 4;
BA_ "UserSigValidity" SG_ 715 RRPSS_L_AstHgtDnMvBtn 0;
BA_REL_ "GenSigTimeoutTime" BU_SG_REL_ APSM SG_ 715 RRPSS_L_AstHgtDnMvBtn 1500;
BA_ "NetworkRequest" SG_ 715 RRPSS_L_AstHgtDnMvBtn 0;
BA_ "NetworkRequestHoldingTime" SG_ 715 RRPSS_L_AstHgtDnMvBtn 5000;
BA_ "Version" SG_ 715 RRPSS_L_AstHgtDnMvBtn "21.04.00";
BA_ "Description" SG_ 715 RRPSS_L_AstFRestOpenMvBtn "Rear Right FootRest Open Move Button";
BA_ "GenSigSendType" SG_ 715 RRPSS_L_AstFRestOpenMvBtn 4;
BA_ "UserSigValidity" SG_ 715 RRPSS_L_AstFRestOpenMvBtn 0;
BA_REL_ "GenSigTimeoutTime" BU_SG_REL_ APSM SG_ 715 RRPSS_L_AstFRestOpenMvBtn 1500;
BA_ "NetworkRequest" SG_ 715 RRPSS_L_AstFRestOpenMvBtn 0;
BA_ "NetworkRequestHoldingTime" SG_ 715 RRPSS_L_AstFRestOpenMvBtn 5000;
BA_ "Version" SG_ 715 RRPSS_L_AstFRestOpenMvBtn "21.04.00";
BA_ "Description" SG_ 715 RRPSS_L_AstFRestCloseMvBtn "Rear Right FootRest Close Move Button";
BA_ "GenSigSendType" SG_ 715 RRPSS_L_AstFRestCloseMvBtn 4;
BA_ "UserSigValidity" SG_ 715 RRPSS_L_AstFRestCloseMvBtn 0;
BA_REL_ "GenSigTimeoutTime" BU_SG_REL_ APSM SG_ 715 RRPSS_L_AstFRestCloseMvBtn 1500;
BA_ "NetworkRequest" SG_ 715 RRPSS_L_AstFRestCloseMvBtn 0;
BA_ "NetworkRequestHoldingTime" SG_ 715 RRPSS_L_AstFRestCloseMvBtn 5000;
BA_ "Version" SG_ 715 RRPSS_L_AstFRestCloseMvBtn "21.04.00";
BA_ "Description" SG_ 715 RRPSS_L_AstHRestBwdMvBtn "Rear Right HeadRest Backward Move Button";
BA_ "GenSigSendType" SG_ 715 RRPSS_L_AstHRestBwdMvBtn 4;
BA_ "UserSigValidity" SG_ 715 RRPSS_L_AstHRestBwdMvBtn 0;
BA_REL_ "GenSigTimeoutTime" BU_SG_REL_ APSM SG_ 715 RRPSS_L_AstHRestBwdMvBtn 1500;
BA_ "NetworkRequest" SG_ 715 RRPSS_L_AstHRestBwdMvBtn 0;
BA_ "NetworkRequestHoldingTime" SG_ 715 RRPSS_L_AstHRestBwdMvBtn 5000;
BA_ "Version" SG_ 715 RRPSS_L_AstHRestBwdMvBtn "21.04.00";
BA_ "Description" SG_ 715 RRPSS_L_AstHRestUpMvBtn "Rear Right HeadRest Up Move Button";
BA_ "GenSigSendType" SG_ 715 RRPSS_L_AstHRestUpMvBtn 4;
BA_ "UserSigValidity" SG_ 715 RRPSS_L_AstHRestUpMvBtn 0;
BA_REL_ "GenSigTimeoutTime" BU_SG_REL_ APSM SG_ 715 RRPSS_L_AstHRestUpMvBtn 1500;
BA_ "NetworkRequest" SG_ 715 RRPSS_L_AstHRestUpMvBtn 0;
BA_ "NetworkRequestHoldingTime" SG_ 715 RRPSS_L_AstHRestUpMvBtn 5000;
BA_ "Version" SG_ 715 RRPSS_L_AstHRestUpMvBtn "21.04.00";
BA_ "Description" SG_ 715 RRPSS_L_AstHRestDnMvBtn "Rear Right HeadRest Down Move Button";
BA_ "GenSigSendType" SG_ 715 RRPSS_L_AstHRestDnMvBtn 4;
BA_ "UserSigValidity" SG_ 715 RRPSS_L_AstHRestDnMvBtn 0;
BA_REL_ "GenSigTimeoutTime" BU_SG_REL_ APSM SG_ 715 RRPSS_L_AstHRestDnMvBtn 1500;
BA_ "NetworkRequest" SG_ 715 RRPSS_L_AstHRestDnMvBtn 0;
BA_ "NetworkRequestHoldingTime" SG_ 715 RRPSS_L_AstHRestDnMvBtn 5000;
BA_ "Version" SG_ 715 RRPSS_L_AstHRestDnMvBtn "21.04.00";
BA_ "GenMsgSendType" BO_ 2164277249 0;
BA_ "GenMsgCycleTime" BO_ 2164277249 20;
BA_ "GenMsgCycleTimeFast" BO_ 2164277249 0;
BA_ "GenMsgNrOfRepetition" BO_ 2164277249 0;
BA_ "GenMsgDelayTime" BO_ 2164277249 0;
BA_ "VFrameFormat" BO_ 2164277249 1;
BA_ "Description" SG_ 2164277249 TCU_Crc1Val "The data area for CRC calculation is based on the data length (DLC) of the message DB.

The CRC shall be calculated over the entire data block (excluding the CRC bytes) including the user data, alive counter and Data ID

 

- CRC Polynomial (0x1021) , Initial Value : 0xFFFF, XOR value : 0x0000, Data ID : Message ID + 0xF800 

- The initial value is for CRC calculation and the message should be sent with the calculated result value. 

- The mathematical expression to 16 bit CRC polynomial is given here. G(x) = x16 + x12 + x5 + 1";
BA_ "GenSigStartValue" SG_ 2164277249 TCU_Crc1Val 65535;
BA_ "UserSigValidity" SG_ 2164277249 TCU_Crc1Val 3;
BA_ "RoutingFactor" SG_ 2164277249 TCU_Crc1Val 5;
BA_ "Version" SG_ 2164277249 TCU_Crc1Val "18.11.08";
BA_ "Description" SG_ 2164277249 TCU_AlvCnt1Val "For the first transmission request for a data element the counter shall be initialized with 0 and shall be incremented by 1 for every subsequent send request. 

When the counter reaches the maximum value(0xFF), then it shall restart with 0 for the next send request";
BA_ "UserSigValidity" SG_ 2164277249 TCU_AlvCnt1Val 3;
BA_ "RoutingFactor" SG_ 2164277249 TCU_AlvCnt1Val 5;
BA_ "Version" SG_ 2164277249 TCU_AlvCnt1Val "18.11.08";
BA_ "Description" SG_ 2164277249 TCU_GearSlctDis "Position (P, R, N..), which was identified by the gear selector.

In case the gear selector is in a intermediate position, the last clear recognized position is used.

There is no specific phase relationship between the output and any other signal.";
BA_ "GenSigStartValue" SG_ 2164277249 TCU_GearSlctDis 9;
BA_ "UserSigValidity" SG_ 2164277249 TCU_GearSlctDis 3;
BA_ "RoutingFactor" SG_ 2164277249 TCU_GearSlctDis 5;
BA_ "Version" SG_ 2164277249 TCU_GearSlctDis "17.11.00";
BA_ "Description" SG_ 2164277249 TCU_Typ "Information regarding the type of transmission - Step A/T or CVT or DCT / AMT / eClutch";
BA_ "UserSigValidity" SG_ 2164277249 TCU_Typ 3;
BA_ "RoutingFactor" SG_ 2164277249 TCU_Typ 5;
BA_ "Version" SG_ 2164277249 TCU_Typ "18.12.02";
BA_ "Description" SG_ 2164277249 TCU_TqRdctnVal "The TCU requests a torque reduction via this signal to the EMS. 



If MSB is 1, this signal is - value.

else, this signal is +value.

0~10bit is used for absolute value.";
BA_ "GenSigStartValue" SG_ 2164277249 TCU_TqRdctnVal 2047;
BA_ "UserSigValidity" SG_ 2164277249 TCU_TqRdctnVal 3;
BA_ "RoutingFactor" SG_ 2164277249 TCU_TqRdctnVal 5;
BA_ "Version" SG_ 2164277249 TCU_TqRdctnVal "18.01.02";
BA_ "Description" SG_ 2164277249 TCU_GearStepTyp "This signal indicates number of gear steps of step type automatic transmission(A/T) or Dual Clutch Transmission(DCT). A vehicle can have A/T or DCT variant according to its option, for example 4-speed A/T or 5-speed A/T can be equipped in the same kind of vehicles and other control systems (e.g. ESC, TCS, …) can need this information to apply appropriate control logic.



The CVT (Continuously Variable Transmission) should set this signal to 00H.";
BA_ "UserSigValidity" SG_ 2164277249 TCU_GearStepTyp 3;
BA_ "RoutingFactor" SG_ 2164277249 TCU_GearStepTyp 5;
BA_ "Version" SG_ 2164277249 TCU_GearStepTyp "19.02.07";
BA_ "Description" SG_ 2164277249 TCU_GearShftSta "SWI_GS indicates whether a gear change is being executed in the gearbox.



Note : Gear change means a gear shift at D-range and Garage shift(PRND).";
BA_ "UserSigValidity" SG_ 2164277249 TCU_GearShftSta 3;
BA_ "RoutingFactor" SG_ 2164277249 TCU_GearShftSta 5;
BA_ "Version" SG_ 2164277249 TCU_GearShftSta "17.11.00";
BA_ "Description" SG_ 2164277249 TCU_TqCnvrtrSta "Status converter clutch



There is no specific phase relationship between the output and any other signal.";
BA_ "UserSigValidity" SG_ 2164277249 TCU_TqCnvrtrSta 3;
BA_ "RoutingFactor" SG_ 2164277249 TCU_TqCnvrtrSta 5;
BA_ "Version" SG_ 2164277249 TCU_TqCnvrtrSta "17.11.00";
BA_ "GenMsgSendType" BO_ 2164277252 0;
BA_ "GenMsgCycleTime" BO_ 2164277252 20;
BA_ "GenMsgCycleTimeFast" BO_ 2164277252 0;
BA_ "GenMsgNrOfRepetition" BO_ 2164277252 0;
BA_ "GenMsgDelayTime" BO_ 2164277252 0;
BA_ "VFrameFormat" BO_ 2164277252 1;
BA_ "Description" SG_ 2164277252 TCU_NetrlCtrlSta "This signal indicates the status of Neutral Control.";
BA_ "UserSigValidity" SG_ 2164277252 TCU_NetrlCtrlSta 3;
BA_ "RoutingFactor" SG_ 2164277252 TCU_NetrlCtrlSta 5;
BA_ "Version" SG_ 2164277252 TCU_NetrlCtrlSta "17.11.00";
BA_ "Description" SG_ 2164277252 TCU_ShftPtrnSta "It is an ID of current shift pattern which is being used by TCU.

The ID is assigned for each TCU.";
BA_ "UserSigValidity" SG_ 2164277252 TCU_ShftPtrnSta 3;
BA_ "RoutingFactor" SG_ 2164277252 TCU_ShftPtrnSta 5;
BA_ "Version" SG_ 2164277252 TCU_ShftPtrnSta "17.11.00";
BA_ "Description" SG_ 2164277252 TCU_EPBReq "This is EPB Request signal for prevent P-D Shift shock on the hill";
BA_ "UserSigValidity" SG_ 2164277252 TCU_EPBReq 3;
BA_ "RoutingFactor" SG_ 2164277252 TCU_EPBReq 5;
BA_ "Version" SG_ 2164277252 TCU_EPBReq "19.03.09";
BA_ "Description" SG_ 2164277252 TCU_VgisInhbtReq "TCU requests ECU to inhibit the VGIS fuction from changing its status.";
BA_ "UserSigValidity" SG_ 2164277252 TCU_VgisInhbtReq 3;
BA_ "RoutingFactor" SG_ 2164277252 TCU_VgisInhbtReq 5;
BA_ "Version" SG_ 2164277252 TCU_VgisInhbtReq "17.11.00";
BA_ "Description" SG_ 2164277252 TCU_EngTqIncReqVal "The TCU requests the engine torque increase via this signal to the EMS.



If MSB is 1, this signal is - value.

else, this signal is +value.

0~10bit is used for absolute value.";
BA_ "UserSigValidity" SG_ 2164277252 TCU_EngTqIncReqVal 3;
BA_ "RoutingFactor" SG_ 2164277252 TCU_EngTqIncReqVal 5;
BA_ "Version" SG_ 2164277252 TCU_EngTqIncReqVal "18.01.02";
BA_ "GenMsgSendType" BO_ 2189467649 0;
BA_ "GenMsgCycleTime" BO_ 2189467649 50;
BA_ "GenMsgCycleTimeFast" BO_ 2189467649 0;
BA_ "GenMsgNrOfRepetition" BO_ 2189467649 0;
BA_ "VFrameFormat" BO_ 2189467649 1;
BA_ "Description" SG_ 2189467649 WHL_Crc1Val "The data area for CRC calculation is based on the data length (DLC) of the message DB.

The CRC shall be calculated over the entire data block (excluding the CRC bytes) including the user data, alive counter and Data ID

 

- CRC Polynomial (0x1021) , Initial Value : 0xFFFF, XOR value : 0x0000, Data ID : Message ID + 0xF800 

- The initial value is for CRC calculation and the message should be sent with the calculated result value. 

- The mathematical expression to 16 bit CRC polynomial is given here. G(x) = x16 + x12 + x5 + 1";
BA_ "GenSigStartValue" SG_ 2189467649 WHL_Crc1Val 65535;
BA_ "UserSigValidity" SG_ 2189467649 WHL_Crc1Val 3;
BA_ "RoutingFactor" SG_ 2189467649 WHL_Crc1Val 5;
BA_ "Version" SG_ 2189467649 WHL_Crc1Val "18.11.08";
BA_ "Description" SG_ 2189467649 WHL_AlvCnt1Val "For the first transmission request for a data element the counter shall be initialized with 0 and shall be incremented by 1 for every subsequent send request. 

When the counter reaches the maximum value(0xFF), then it shall restart with 0 for the next send request";
BA_ "UserSigValidity" SG_ 2189467649 WHL_AlvCnt1Val 3;
BA_ "RoutingFactor" SG_ 2189467649 WHL_AlvCnt1Val 5;
BA_ "Version" SG_ 2189467649 WHL_AlvCnt1Val "18.11.08";
BA_ "Description" SG_ 2189467649 WHL_PlsFLVal "This signal indicates accumulated pulse counter of ABS^ESC wheel speed sensor (FL^FR^RL^RR)

Receiver unit uses this signal for calculation of vehicle movement distance.

Requested resolution of this signal is 0.5 pulses and refer to below (wheel sensor signal).";
BA_ "UserSigValidity" SG_ 2189467649 WHL_PlsFLVal 3;
BA_ "RoutingFactor" SG_ 2189467649 WHL_PlsFLVal 5;
BA_ "Version" SG_ 2189467649 WHL_PlsFLVal "17.12.00";
BA_ "Description" SG_ 2189467649 WHL_PlsFRVal "This signal indicates accumulated pulse counter of ABS^ESC wheel speed sensor (FL^FR^RL^RR)

Receiver unit uses this signal for calculation of vehicle movement distance.

Requested resolution of this signal is 0.5 pulses and refer to below (wheel sensor signal).";
BA_ "UserSigValidity" SG_ 2189467649 WHL_PlsFRVal 3;
BA_ "RoutingFactor" SG_ 2189467649 WHL_PlsFRVal 5;
BA_ "Version" SG_ 2189467649 WHL_PlsFRVal "17.12.00";
BA_ "Description" SG_ 2189467649 WHL_PlsRLVal "This signal indicates accumulated pulse counter of ABS^ESC wheel speed sensor (FL^FR^RL^RR)

Receiver unit uses this signal for calculation of vehicle movement distance.

Requested resolution of this signal is 0.5 pulses and refer to below (wheel sensor signal).";
BA_ "UserSigValidity" SG_ 2189467649 WHL_PlsRLVal 3;
BA_ "RoutingFactor" SG_ 2189467649 WHL_PlsRLVal 5;
BA_ "Version" SG_ 2189467649 WHL_PlsRLVal "17.12.00";
BA_ "Description" SG_ 2189467649 WHL_PlsRRVal "This signal indicates accumulated pulse counter of ABS^ESC wheel speed sensor (FL^FR^RL^RR)

Receiver unit uses this signal for calculation of vehicle movement distance.

Requested resolution of this signal is 0.5 pulses and refer to below (wheel sensor signal).";
BA_ "UserSigValidity" SG_ 2189467649 WHL_PlsRRVal 3;
BA_ "RoutingFactor" SG_ 2189467649 WHL_PlsRRVal 5;
BA_ "Version" SG_ 2189467649 WHL_PlsRRVal "17.12.00";
BA_ "Description" SG_ 2189467649 WHL_DirFLVal "This signal is used to check the moving direction of WHL_PUL_FL signal.";
BA_ "UserSigValidity" SG_ 2189467649 WHL_DirFLVal 3;
BA_ "RoutingFactor" SG_ 2189467649 WHL_DirFLVal 5;
BA_ "Version" SG_ 2189467649 WHL_DirFLVal "17.12.00";
BA_ "Description" SG_ 2189467649 WHL_DirFRVal "This signal is used to check the moving direction of WHL_PUL_FR signal.";
BA_ "UserSigValidity" SG_ 2189467649 WHL_DirFRVal 3;
BA_ "RoutingFactor" SG_ 2189467649 WHL_DirFRVal 5;
BA_ "Version" SG_ 2189467649 WHL_DirFRVal "17.12.00";
BA_ "Description" SG_ 2189467649 WHL_DirRLVal "This signal is used to check the moving direction of WHL_PUL_RL signal.";
BA_ "UserSigValidity" SG_ 2189467649 WHL_DirRLVal 3;
BA_ "RoutingFactor" SG_ 2189467649 WHL_DirRLVal 5;
BA_ "Version" SG_ 2189467649 WHL_DirRLVal "17.12.00";
BA_ "Description" SG_ 2189467649 WHL_DirRRVal "This signal is used to check the moving direction of WHL_PUL_RR signal.";
BA_ "UserSigValidity" SG_ 2189467649 WHL_DirRRVal 3;
BA_ "RoutingFactor" SG_ 2189467649 WHL_DirRRVal 5;
BA_ "Version" SG_ 2189467649 WHL_DirRRVal "17.12.00";
BA_ "GenMsgSendType" BO_ 2189467650 0;
BA_ "GenMsgCycleTime" BO_ 2189467650 50;
BA_ "GenMsgCycleTimeFast" BO_ 2189467650 0;
BA_ "GenMsgNrOfRepetition" BO_ 2189467650 0;
BA_ "VFrameFormat" BO_ 2189467650 1;
BA_ "Description" SG_ 2189467650 WHL_SpdFLVal "This signal provides the wheel velocity of each wheel and have 14 bits length and a resolution of 0.03125 km^h.(This resolution is higher than that of signal in TCS5).

In case of failure of one wheel speed sensor, the value 3FFFH is used as error identifier.";
BA_ "UserSigValidity" SG_ 2189467650 WHL_SpdFLVal 3;
BA_ "RoutingFactor" SG_ 2189467650 WHL_SpdFLVal 5;
BA_ "Version" SG_ 2189467650 WHL_SpdFLVal "17.12.00";
BA_ "Description" SG_ 2189467650 WHL_SpdFRVal "This signal provides the wheel velocity of each wheel and have 14 bits length and a resolution of 0.03125 km^h.(This resolution is higher than that of signal in TCS5).

In case of failure of one wheel speed sensor, the value 3FFFH is used as error identifier.";
BA_ "UserSigValidity" SG_ 2189467650 WHL_SpdFRVal 3;
BA_ "RoutingFactor" SG_ 2189467650 WHL_SpdFRVal 5;
BA_ "Version" SG_ 2189467650 WHL_SpdFRVal "17.12.00";
BA_ "Description" SG_ 2189467650 WHL_SpdRLVal "This signal provides the wheel velocity of each wheel and have 14 bits length and a resolution of 0.03125 km^h.(This resolution is higher than that of signal in TCS5).

In case of failure of one wheel speed sensor, the value 3FFFH is used as error identifier.";
BA_ "UserSigValidity" SG_ 2189467650 WHL_SpdRLVal 3;
BA_ "RoutingFactor" SG_ 2189467650 WHL_SpdRLVal 5;
BA_ "Version" SG_ 2189467650 WHL_SpdRLVal "17.12.00";
BA_ "Description" SG_ 2189467650 WHL_SpdRRVal "This signal provides the wheel velocity of each wheel and have 14 bits length and a resolution of 0.03125 km^h.(This resolution is higher than that of signal in TCS5).

In case of failure of one wheel speed sensor, the value 3FFFH is used as error identifier.";
BA_ "UserSigValidity" SG_ 2189467650 WHL_SpdRRVal 3;
BA_ "RoutingFactor" SG_ 2189467650 WHL_SpdRRVal 5;
BA_ "Version" SG_ 2189467650 WHL_SpdRRVal "17.12.00";
BA_ "GenMsgSendType" BO_ 2189467651 0;
BA_ "GenMsgCycleTime" BO_ 2189467651 50;
BA_ "GenMsgCycleTimeFast" BO_ 2189467651 0;
BA_ "GenMsgNrOfRepetition" BO_ 2189467651 0;
BA_ "VFrameFormat" BO_ 2189467651 1;
BA_ "Description" SG_ 2189467651 WHL_SpdCalParmtr "이 신호는 ABS/ESC 내부에서 휠 펄스 값을 휠 스피드로 변환하는데 사용하는 ESC 내부 파라미터를 의미함.

본 신호는 실제 타이어 동반경과 다를 수 있으며, ABS/ESC의 제어를 위한 차속 추정을 위해 개발 과정 중에 임의로 변경이 가능한 Calibration Value 임.

신호 사용을 위해서는 사전에 협의 후 사용해야함.";
BA_ "UserSigValidity" SG_ 2189467651 WHL_SpdCalParmtr 3;
BA_ "RoutingFactor" SG_ 2189467651 WHL_SpdCalParmtr 5;
BA_ "Version" SG_ 2189467651 WHL_SpdCalParmtr "19.05.02";
VAL_ 2273436929 RCCW_Sta 0 "Default" 1 "RCCW is Off" 2 "RCCW Passive" 3 "RCCW Active" 4 "RCCW Failure" 5 "RCCW Blockage" 6 "RCCW Minor Failure" 7 "Reserved" 8 "Reserved" 9 "Reserved" 10 "Reserved" 11 "Reserved" 12 "Reserved" 13 "Reserved" 14 "Reserved" ;
VAL_ 2273436929 RCCW_LtIndSta 0 "Indicator output off" 1 "Indicator on (information)" 2 "Ready" 3 "Error Indicator" ;
VAL_ 2273436929 RCCW_RtIndSta 0 "Indicator output off" 1 "Indicator on (information)" 2 "Ready" 3 "Error Indicator" ;
VAL_ 2273436929 RCCW_LtSndWrngSta 0 "Speaker is Off" 1 "Speaker On" 2 "Not used" 3 "Error Indicator" ;
VAL_ 2273436929 RCCW_RtSndWrngSta 0 "Speaker is Off" 1 "Speaker On" 2 "Not used" 3 "Error Indicator" ;
VAL_ 2273436930 RCCA_Sta 0 "Default" 1 "RCCA is Off" 2 "RCCA Passive" 3 "RCCA Active" 4 "RCCA Failure" 5 "RCCA Blockage" 6 "RCCA Minor Failure" 7 "Reserved" 8 "Reserved" 9 "Reserved" 10 "Reserved" 11 "Reserved" 12 "Reserved" 13 "Reserved" 14 "Reserved" ;
VAL_ 2273436930 RCCA_OnOffEquipSt 0 "Default" 1 "Off" 2 "Assist" 3 "Invalid" ;
VAL_ 2273436930 SEA_Sta 0 "Default" 1 "SEA Function is off" 2 "SEA Function is passive" 3 "SEA Function active" 4 "SEA Function failure" 5 "SEA Function Blockage" 6 "SEA Function minor failure" 7 "Reserved" 8 "Reserved" 9 "Reserved" 10 "Reserved" 11 "Reserved" 12 "Reserved" 13 "Reserved" 14 "Reserved" ;
VAL_ 2273436930 SEA_LtTrgtSta 0 "SEA Left Warning OFF" 1 "SEA Left Warning ON" 2 "Not used" 3 "Error Indicator" ;
VAL_ 2273436930 SEA_RtTrgtSta 0 "SEA Right Warning OFF" 1 "SEA Right Warning ON" 2 "Not used" 3 "Error Indicator" ;
VAL_ 2273436930 SEA_OnOffEquipSta_New 0 "Default" 1 "Off" 2 "Assist" 3 "Invalid" ;
VAL_ 2273436930 RCCA_BrkCmdSta 0 "RCCA Brake off" 1 "RCCA Brake on" 2 "Not used" 3 "Error Indicator" ;
VAL_ 2273436930 RCCA_LtWrngSta 0 "RCCA Left Warning is Off" 1 "RCCA Left Warning is On" 2 "RCCA Left Warning is Ended" 3 "BRAKE HOLD" ;
VAL_ 2273436930 RCCA_RtWrngSta 0 "RCCA Right Warning is Off" 1 "RCCA Right Warning is On" 2 "RCCA Right Warning is Ended" 3 "BRAKE HOLD" ;
VAL_ 287 APSS_LumbarUpSw 0 "Default" 1 "Off" 2 "On" 3 "Invalid" ;
VAL_ 287 APSS_LumbarMidSw 0 "Default" 1 "Off" 2 "On" 3 "Invalid" ;
VAL_ 287 APSS_LumbarLowSw 0 "Default" 1 "Off" 2 "On" 3 "Invalid" ;
VAL_ 287 APSS_LumbarDefSw 0 "Default" 1 "Off" 2 "On" 3 "Invalid" ;
VAL_ 287 APSS_BolsterInfSw 0 "Default" 1 "Off" 2 "On" 3 "Invalid" ;
VAL_ 287 APSS_BolsterDefSw 0 "Default" 1 "Off" 2 "On" 3 "Invalid" ;
VAL_ 271 ASAU_AirSptTimeRValueSet 0 "Default" 1 "Short" 2 "Normal" 3 "Long" 4 "Reserved" 5 "Reserved" 6 "Reserved" 7 "Reserved" ;
VAL_ 271 ASAU_AstSmtAirSptRValueSet 0 "Default" 1 "Off" 2 "On" 3 "Invalid" ;
VAL_ 271 ASAU_CushSoftRValueSet 0 "Default" 1 "Off" 2 "Soft" 3 "Mid" 4 "Hard" 5 "Reserved" 6 "Reserved" 7 "Reserved" ;
VAL_ 271 ASAU_BackSoftRValueSet 0 "Default" 1 "Off" 2 "Soft" 3 "Mid" 4 "Hard" 5 "Reserved" 6 "Reserved" 7 "Reserved" ;
VAL_ 271 ASAU_AirSptModeRValueSet 0 "Default" 1 "Mode 1" 2 "Mode 2" 3 "Mode 3" 4 "Mode 4" 5 "Mode 5" 6 "Reserved" 7 "Reserved" ;
VAL_ 271 ASAU_NotFootMsgOperStaWarnPE 0 "Default" 1 "Off (Disable)" 2 "On (Enable)" 3 "Invalid" ;
VAL_ 271 ASAU_RRFootAirSptRValueSet 0 "Default" 1 "Off" 2 "On" 3 "Invalid" ;
VAL_ 271 ASAU_RRFootAirSptHeatRValueSet 0 "Default" 1 "Off" 2 "On" 3 "Invalid" ;
VAL_ 271 ASAU_MoodTrpyRValueSet 0 "Default" 1 "Off" 2 "On" 3 "Invalid" ;
VAL_ 271 ASAU_MoodTrpyCareSta 0 "Default" 1 "Off" 2 "On" 3 "Invalid" ;
VAL_ 271 ASAU_MoodTrpyComfSta 0 "Default" 1 "Off" 2 "On" 3 "Invalid" ;
VAL_ 271 ASAU_AirSptStrRValueSet 0 "Default" 1 "Low" 2 "Mid" 3 "High" 4 "Off" 5 "Reserved" 6 "Reserved" 7 "Reserved" ;
VAL_ 2558929665 Warn_Sound_SCC_TakeoverReq 0 "Off" 1 "On(SCC TakeoverReq)" 2 "Reserved" 3 "Invalid" ;
VAL_ 2558929665 Warn_Sound_PopUp_Vol 0 "Off" 1 "Red Pop-up(Collision)" 2 "Red Pop-up" 3 "Yellow Pop-up" 4 "White(Alarm) Pop-up" 5 "White(Feedback) Pop-up" 6 "Reserved" 7 "Invalid" ;
VAL_ 2558929665 Warn_Sound_LKA_HndsoffSnd 0 "Off" 1 "On(HndsoffSnd)" 2 "Reserved" 3 "Invalid" ;
VAL_ 2395189761 DATC_Typ 0 "0x0x00~0xFF:applied options (See Description)" 255 "0x0x00~0xFF:applied options (See Description)" ;
VAL_ 2395189761 DATC_Opt1Typ 0 "0x0x00~0xFF:applied options (See Description)" 255 "0x0x00~0xFF:applied options (See Description)" ;
VAL_ 2395189761 DATC_Opt3Typ 0 "0x0x00~0xFF:applied options (See Description)" 255 "0x0x00~0xFF:applied options (See Description)" ;
VAL_ 2395189761 DATC_Opt2Typ 0 "applied options (See Description)" 1 "applied options (See Description)" 2 "applied options (See Description)" 3 "applied options (See Description)" 4 "applied options (See Description)" 5 "applied options (See Description)" 6 "applied options (See Description)" 7 "applied options (See Description)" 8 "applied options (See Description)" 9 "applied options (See Description)" 10 "applied options (See Description)" 11 "applied options (See Description)" 12 "applied options (See Description)" 13 "applied options (See Description)" 14 "applied options (See Description)" 15 "applied options (See Description)" ;
VAL_ 2395189761 DATC_StrWhlUSMSta 0 "NOT APPLY" 1 "OFF" 2 "ON" 3 "Error Indicator" ;
VAL_ 2395189761 DATC_StrWhlHtngReq 0 "Default" 1 "Integrated control OFF" 2 "Steering Wheel heat OFF" 3 "Steering Wheel heat 1st ON" 4 "Steering Wheel heat 1st & 2nd ON" 5 "Reserved" 6 "Reserved" 7 "Invalid" ;
VAL_ 2365803009 DATC_SwVer1 0 "0x0x00~0x7E:ASCII value" 126 "0x0x00~0x7E:ASCII value" 127 "Invalid" ;
VAL_ 2365803009 DATC_SwVer2 0 "0x0x00~0x7E:ASCII value" 126 "0x0x00~0x7E:ASCII value" 127 "Invalid" ;
VAL_ 2365803009 DATC_SwVer3 0 "0x0x00~0x7E:ASCII value" 126 "0x0x00~0x7E:ASCII value" 127 "Invalid" ;
VAL_ 2365803009 DATC_Typ2 0 "0x0x00~0xFF: applied options (See Description)" 255 "0x0x00~0xFF: applied options (See Description)" ;
VAL_ 2193667329 EMS_Crc1Val 65535 "Signal Invalid (Message with unused CRC. CRC signal is transmitted fixed value)" ;
VAL_ 2193667329 EMS_AlvCnt1Val 255 "Signal Invalid (Message with unused Alive counter. Alive counter signal is transmitted fixed value)" ;
VAL_ 2193667330 ENG_EngSpdErrSta 0 "No error" 1 "Engine speed sensor defective" 2 "Not used" 3 "Error indicator" ;
VAL_ 2193667330 ENG_MafErrSta 0 "No error" 1 "Error on Torque Measurement" 2 "Not used" 3 "Error indicator" ;
VAL_ 2193667330 ENG_EtcLmphModSta 0 "Engine control is available" 1 "ETC Limphome mode by ECU" 2 "Not used" 3 "Error indicator" ;
VAL_ 2193667330 ENG_MaxAirconTqVal 255 "Error indicator" ;
VAL_ 2193667330 ENG_AirconPrsrSnsrVal 255 "Error indicator" ;
VAL_ 2193667330 ENG_IsgSta 0 "ISG is not operating Normal engine operating without ISG" 1 "Idle stop is activated Idle is stopped by ECU during driving" 2 "Automatically started by ECU Engine is automatically started by ECU regardless driver’s volition during idle stop because the condition that ISG function to be prohibited is satisfied, for example SOC is too low." 3 "ISG is prohibited Driver prohibits to activate ISG in order to avoid start lag when he met traffic jam for example." 4 "Fault  existing in ISG. Idle stop is prohibited and engine started automatically if it is idle stop condition." 5 "Idle stop is inhibited by system automatically for safety and  convenient condition related with battery SOC, brake vacuum pressure etc. ISG function check for EOL." 6 "Auto start is deactivated system automatically to keep safety, Such as door open, hood open and seat belt unlock." 7 "If driver shift gear N to D range without braking to make auto starting. (Economy ISG Only)" ;
VAL_ 2193667330 ENG_OilLvlSta 0 "OIL LEVEL LAMP Off" 1 "OIL LEVEL LAMP On" 2 "Not used" 3 "Error indicator" ;
VAL_ 2193667331 ENG_TrgtIdleRpmVal 255 "Error indicator" ;
VAL_ 2193667331 ENG_GearShftDnDis 0 "Gear Shiftdown Display Off" 1 "Gear Shiftdown Display On" 2 "Not used" 3 "Error indicator" ;
VAL_ 2193667331 ENG_DsrGearPosDis 0 "No display" 1 "Gear Position 1 display" 2 "Gear Position 2 display" 3 "Gear Position 3 display" 4 "Gear Position 4 display" 5 "Gear Position 5 display" 6 "Gear Position 6 display" 7 "Gear Position 7 display" 8 "Gear Position 8 display" 9 "Gear Position 9 display" 10 "Gear Position 10 display" 15 "Error indicator" ;
VAL_ 2193667331 ENG_SldFuncSta 0 "Speed limiter function is not active" 1 "Speed limiter function is active" 2 "Not used" 3 "Error indicator" ;
VAL_ 2193667331 ENG_SldActnSta 0 "Positive action is not active" 1 "Positive action is active" 2 "Not used" 3 "Error indicator" ;
VAL_ 2193667331 ENG_FuelTnkPrsrSta 0 "Fuel Tank is not in high Pressure" 1 "Fuel Tank is in high Pressure" 2 "Not used" 3 "Error indicator" ;
VAL_ 2193667331 ENG_IsgBzrReq 0 "Request buzzer OFF" 1 "Request buzzer ON" 2 "Not used" 3 "Error indicator" ;
VAL_ 2193667331 ENG_IsgFuelCnsmptDis 0 "Not fuel consumption" 1 "Fuel consumption(=1mL)" 2 "Not used" 3 "Error indicator" ;
VAL_ 2193667331 ENG_FuelCapOpnSta 0 "Fuel cap isn't opened" 1 "Fuel cap is opened" 2 "Not used" 3 "Error indicator" ;
VAL_ 2193667331 ENG_EcoDrvActvSta 0 "Active Eco Drive is not active" 1 "Active Eco Drive is active" 2 "Not used" 3 "Error indicator" ;
VAL_ 2193667331 ENG_EngRunSta 0 "Engine Stop or Starting Phase" 1 "Engine Running" 2 "Not used" 3 "Error indicator" ;
VAL_ 2193667331 ENG_Isg2Sta 0 "Default" 1 "The condition for not-activated battery sensor. (Except EOL condition.)" 2 "In Auto Start status, when rapidly accelerating before complete gear shift. (Economy ISG Only)" 3 "Error indicator" ;
VAL_ 2193667331 ENG_IgnOnSta 0 "KEY OFF, control unit in self-holding phase" 1 "KEY ON" 2 "Not used" 3 "Error indicator" ;
VAL_ 2193667331 ENG_Ack4TcsSta 0 "TCS message not received within the last 500 ms, or a plausibility error in torque intervention is ON" 1 "TCS message received, and no plausibility error" 2 "Not used" 3 "Error indicator" ;
VAL_ 2193667331 ENG_FuelCutOffSta 0 "Engine not in fuel cut off" 1 "Engine in fuel cut off" 2 "Not used" 3 "Error indicator" ;
VAL_ 2193667331 ENG_CrctTqSta 0 "The desired intervention regarding ignition angle retardation and cylinder shut-off is executed. (Default value)" 1 "The desired intervention regarding ignition angle retardation and cylinder shut-off is executed; however, the requested target torque can not be adjusted precisely (torque steps)" 2 "The torque reduction regarding the ignition angle retardation cannot be completely executed. A cylinder shut-off is not possible at this time." 3 "Due to a failure detected the desired torque intervention for TCS regarding the ignition angle and cylinder shut-off is no longer executed." ;
VAL_ 2193667331 ENG_AirCompRlySta 0 "Air conditioner compressor relay OFF" 1 "Air conditioner compressor relay ON" 2 "Not used" 3 "Error indicator" ;
VAL_ 2193667331 ENG_LnchCntrlSta 0 "Off state" 1 "Standby" 2 "Ready" 3 "Lanch" 4 "Error indicator" ;
VAL_ 2193667331 ENG_GearShftUpDis 0 "Gear Shiftup Display Off" 1 "Gear Shiftup Display On" 2 "Not used" 3 "Error indicator" ;
VAL_ 2193667332 ENG_VehSpdHiVal 511 "Error indicator" ;
VAL_ 2193667332 ENG_SldSwSta 0 "Speed limiter function is OFF" 1 "Speed limiter function is Active(Kickdown)" 2 "Speed limiter function is Pause" 3 "Error indicator" ;
VAL_ 2193667332 ENG_SldDrvAlertDisp 0 "Default" 1 "SldDisengaged" 2 "NoSldEngaged" 3 "ErrorIndicator" ;
VAL_ 2193667332 ENG_VehSpdLimVal 511 "Error indicator" ;
VAL_ 2214659329 EMS_Crc7Val 65535 "Signal Invalid (Message with unused CRC. CRC signal is transmitted fixed value)" ;
VAL_ 2214659329 EMS_AlvCnt7Val 255 "Signal Invalid (Message with unused Alive counter. Alive counter signal is transmitted fixed value)" ;
VAL_ 2214659329 HEV_EngSpdErrSta 0 "no error" 1 "engine speed sensor defective" ;
VAL_ 2214659330 HEV_VehSpdVal 255 "Error indicator" ;
VAL_ 2214659330 HEV_EngOpSta 0 "ES(Engine Stop)" 1 "ST(Start)" 2 "IS(Idle speed)" 3 "PL(Part Load)" 4 "PU(Pull)" 5 "PUC(Fuel Cut off)" ;
VAL_ 2214659330 HEV_EtcAppSta 0 "Fuel - Gasoline,  ETC - No" 1 "Fuel - LPI(LPG),  ETC - No" 2 "Fuel - Diesel,     ETC - No" 3 "Reserved" 4 "Fuel - Gasoline,  ETC - Applied" 5 "Fuel - LPI(LPG),  ETC - Applied" 6 "Fuel - Diesel,    ETC - Applied" 7 "GDI type engine" ;
VAL_ 2214659331 HEV_EwpMtrCtrlSta 0 "Motor Stop(500rpm)" 1 "Motor Run" 2 "Not used" 3 "Error indicator" ;
VAL_ 2214659331 HEV_O2SnsrPreHeatSta 0 "No LSH_UP preheating" 1 "LSH_UP preheating activated" 2 "Not used" 3 "Error indicator" ;
VAL_ 2214659331 HEV_FirstFiringSta 0 "No firing" 1 "First firing" 2 "Not used" 3 "Error indicator" ;
VAL_ 2214659331 HEV_EngFulLoadSta 0 "No Full Load" 1 "Full Load" 2 "Not used" 3 "Error indicator" ;
VAL_ 2214659331 HEV_DrvCycActSta 0 "No driving cycle active" 1 "Driving cycle active" 2 "Not used" 3 "Error indicator" ;
VAL_ 2214659331 HEV_WarmupCycSta 0 "Not warm-up cycle completed" 1 "Warm-up cycle completed" 2 "Not used" 3 "Error indicator" ;
VAL_ 2214659331 HEV_RbmDrvCycSta 0 "Not RBM driving cycle completed" 1 "RBM driving cycle completed" 2 "Not used" 3 "Error indicator" ;
VAL_ 2214659331 HEV_ThrPosSta 32 "Idle (port value is learnt)" 245 "Throttle perpendicular" 255 "Throttle defective" ;
VAL_ 2214659332 HEV_AccelPdlVal 0 "Accelerator Pedal not activated" 254 "Accelerator Pedal fully activated" 255 "Accelerator Pedal is defective (fail state) or Non-ETC system (APS is not installed)" ;
VAL_ 2214659332 HEV_FuelCutOffSta 0 "Engine Not in fuel cut-off" 1 "Engine in fuel cut-off" 2 "Not used" 3 "Error indicator" ;
VAL_ 2214659332 HEV_FuelCutOffInhbtSta 0 "Permit" 1 "Inhibit" 2 "Not used" 3 "Error indicator" ;
VAL_ 2563126017 AMP_EngASDMasterGain 0 "Reserved" 1 "Reserved" 2 "Reserved" 3 "MasterGain" 4 "MasterGain" 5 "MasterGain" 6 "MasterGain" 7 "MasterGain" 8 "MasterGain" 9 "MasterGain" 10 "MasterGain" 11 "MasterGain" 12 "MasterGain" 13 "MasterGain" 14 "MasterGain" 15 "MasterGain" 16 "MasterGain" 17 "MasterGain" 18 "MasterGain" 19 "MasterGain" 20 "MasterGain" 21 "MasterGain" 22 "MasterGain" 23 "MasterGain" 24 "MasterGain" 25 "MasterGain" 26 "MasterGain" 27 "MasterGain" 28 "Reserved" 29 "Reserved" 30 "Reserved" 31 "Invalid" ;
VAL_ 2563126017 AMP_Beep1Frequency 20 "0x0x14~0x4E20:Valid for Hz step" 20000 "0x0x14~0x4E20:Valid for Hz step" 65535 "Invalid" ;
VAL_ 2563128321 AMP_QuietModeVolumeStep 0 "0x0x0~0xFD:QuietMode Volume" 253 "0x0x0~0xFD:QuietMode Volume" 254 "Req. amp supported QuietMode Set" 255 "Invalid" ;
VAL_ 2563128321 AMP_ToneScapeY 0 "0x0x00~0xFE:ToneScapeY" 254 "0x0x00~0xFE:ToneScapeY" 255 "Invalid" ;
VAL_ 2563128321 AMP_ToneScapeZ 0 "0x0x00~0xFE:ToneScapeZ" 254 "0x0x00~0xFE:ToneScapeZ" 255 "Invalid" ;
VAL_ 2563128321 AMP_MasterBeepVolumeLevel 0 "0x0x0~0xFE:MasterBeepVolume" 254 "0x0x0~0xFE:MasterBeepVolume" 255 "Invalid" ;
VAL_ 2563128321 AMP_ToneScapeX 0 "0x0x00~0xFE:ToneScapeX" 254 "0x0x00~0xFE:ToneScapeX" 255 "Invalid" ;
VAL_ 2470762241 HU_VehiclePwr 0 "Key out or Audio OFF" 1 "Not used" 2 "ACC or Audio ON" 3 "KBD Wake-up" 4 "Not used" 5 "Not used" 6 "Not used" 7 "Not used" 8 "Not used" 9 "Not used" 10 "Not used" 11 "Not used" 12 "Not used" 13 "Not used" 14 "Not used" 15 "Invalid" ;
VAL_ 2470762241 HU_BtnShowReq 0 "default" 1 "on" 2 "off" 3 "reserved" 4 "reserved" 5 "reserved" 6 "reserved" 7 "invalid" ;
VAL_ 2315420929 AVN_FPFuntionEnableNValueSet 0 "Default" 1 "Disable" 2 "Enable" 3 "Invalid" ;
VAL_ 2315420929 AVN_User2_SecondFPNValueSet 0 "Default" 1 "Disable" 2 "Enable" 3 "Invalid" ;
VAL_ 2315420929 AVN_User2_ThirdFPNValueSet 0 "Default" 1 "Disable" 2 "Enable" 3 "Invalid" ;
VAL_ 2315420929 AVN_FPProcessStopReq 0 "Default" 1 "StopReq" 2 "Reserved" 3 "Invalid" ;
VAL_ 2315420929 AVN_AuthorizeCancelReq 0 "Default" 1 "Authorize Cancel Req" 2 "Reserved" 3 "Invalid" ;
VAL_ 2315420929 AVN_User1_FirstFPNValueSet 0 "Default" 1 "Disable" 2 "Enable" 3 "Invalid" ;
VAL_ 2315420929 AVN_ISKLearning 0 "Default(Normal)" 1 "Start Learning with PSK1" 2 "Start Learning with PSK2" 3 "Start Learning with PSK3" 4 "Start Learning with PSK4" 5 "Start Learning with PSK5" 6 "Stop" 7 "Start Neutralizing" 8 "Reserved" 9 "Reserved" 10 "Reserved" 11 "Reserved" 12 "Reserved" 13 "Reserved" 14 "Reserved" 15 "Invalid" ;
VAL_ 2315420929 AVN_ISKLearnFB 0 "Defulat(Normal)" 1 "Positive" 2 "Mismatch HPV" 3 "Mismatch PSK" 4 "Save Failed ISK" 5 "Time Out" 6 "Not Learnt" 7 "Negative" 8 "Reserved" 9 "Reserved" 10 "Reserved" 11 "Reserved" 12 "Reserved" 13 "Reserved" 14 "Reserved" 15 "Invalid" ;
VAL_ 2315420929 AVN_FPProcessStartReq 0 "Default" 1 "Start-FP-Function" 2 "Start-Encryption-Test" 3 "Reserved" 4 "Reserved" 5 "Reserved" 6 "Reserved" 7 "Reserved" 8 "Reserved" 9 "Reserved" 10 "Reserved" 11 "Reserved" 12 "Reserved" 13 "Reserved" 14 "Reserved" 15 "Invalid" ;
VAL_ 2315420929 AVN_FPFdbckResult 0 "Default" 1 "Success" 2 "Fail-normal" 3 "Fail-FPLimited" 4 "FPLimitRelease" 5 "Reserved" 6 "Reserved" 7 "Reserved" 8 "Reserved" 9 "Reserved" 10 "Reserved" 11 "Reserved" 12 "Reserved" 13 "Reserved" 14 "Reserved" 15 "Invalid" ;
VAL_ 2315420929 AVN_User1_SecondFPNValueSet 0 "Default" 1 "Disable" 2 "Enable" 3 "Invalid" ;
VAL_ 2315420929 AVN_FPStartUseNvalueSet 0 "Default" 1 "Disable" 2 "Enable" 3 "Invalid" ;
VAL_ 2315420929 AVN_User1_ThirdFPNValueSet 0 "Default" 1 "Disable" 2 "Enable" 3 "Invalid" ;
VAL_ 2315420929 AVN_User2_FirstFPNValueSet 0 "Default" 1 "Disable" 2 "EnableEnable" 3 "Invalid" ;
VAL_ 2470762497 HU_DistanceUnit 0 "Km" 1 "Mile" 2 "Reserved" 3 "Invalid" ;
VAL_ 2470762497 HU_ThemeType 0 "Default" 1 "Aqua(Hyundai)" 2 "Magenta(Kia)" 3 "Eco White" 4 "Eco Black" 5 "Genesis(IKPE)" 6 "Magenta White" 7 "RESERVED" 8 "RESERVED" 9 "RESERVED" 10 "RESERVED" 11 "RESERVED" 12 "RESERVED" 13 "RESERVED" 14 "RESERVED" 15 "Invalid" 16 "Copper" 17 "Copper Rust" 18 "RESERVED" 19 "RESERVED" 20 "RESERVED" 21 "RESERVED" 22 "RESERVED" 23 "RESERVED" 24 "RESERVED" 25 "RESERVED" 26 "RESERVED" 27 "RESERVED" 28 "RESERVED" 29 "RESERVED" 30 "RESERVED" 31 "RESERVED" 32 "ccIC Light" 33 "ccIC Dark" 34 "RESERVED" 35 "RESERVED" 36 "RESERVED" 37 "RESERVED" 38 "RESERVED" 39 "RESERVED" 40 "RESERVED" 41 "RESERVED" 42 "RESERVED" 43 "RESERVED" 44 "RESERVED" 45 "RESERVED" 46 "RESERVED" 47 "RESERVED" 48 "RESERVED" 49 "RESERVED" 50 "RESERVED" 51 "RESERVED" 52 "RESERVED" 53 "RESERVED" 54 "RESERVED" 55 "RESERVED" 56 "RESERVED" 57 "RESERVED" 58 "RESERVED" 59 "RESERVED" 60 "RESERVED" 61 "RESERVED" 62 "RESERVED" 63 "RESERVED" ;
VAL_ 2470762497 HU_MicActivity 0 "Deactivated" 1 "Activated" 2 "reserved" 3 "Invalid" ;
VAL_ 2470762497 HU_Scheduled_Setting 0 "Scheduled not set" 1 "Scheduled set" 2 "Reserved" 3 "Reserved" 4 "Reserved" 5 "Reserved" 6 "60% SoC Requested" 7 "70% SoC Requested" 8 "80% SoC Requested" 9 "90% SoC Requested" 10 "100% SoC Requested" 11 "Reserved" 12 "Reserved" 13 "Reserved" 14 "Reserved" 15 "Invalid" ;
VAL_ 2470762497 AVN_RSPA_ModeSelect 0 "None" 1 "CCP focus (1st menu on the left)" 2 "Touch or CCP confirm (1st menu on the left)" 3 "CCP focus (2nd menu on the left)" 4 "Touch or CCP confirm (2nd menu on the left)" 5 "CCP focus (1st menu on the right)" 6 "Touch or CCP confirm (1st menu on the right)" 7 "CCP focus (2nd menu on the right)" 8 "Touch or CCP confirm (2nd menu on the right)" 9 "Reserved" 10 "Reserved" 11 "Reserved" 12 "Reserved" 13 "Reserved" 14 "Reserved" 15 "Invalid" ;
VAL_ 2470762497 CF_HU_GPSFlt 0 "Normal" 1 "Fault operation" 2 "Reserved" 3 "Invalid" ;
VAL_ 2470762497 AVN_RSPA_CancelInput 0 "Init" 1 "No Input" 2 "Cancel Input" 3 "Invalid" ;
VAL_ 2470762497 AVN_RSPA_ModeSetStat 0 "None" 1 "사선 후방 좌측 (ADLD)" 2 "직각 전방 좌측 (PDFLD)" 3 "평행 후방 좌측 (PLD)" 4 "직각 후방 좌측 (PDRLD)" 5 "직각 후방 우측 (PDRRD)" 6 "평행 후방 우측 (PRD)" 7 "직각 전방 우측 (PDFRD)" 8 "사선 후방 우측 (ADRD)" 9 "Reserved" 10 "Reserved" 11 "Reserved" 12 "Reserved" 13 "Reserved" 14 "Reserved" 15 "Invalid" ;
VAL_ 2470762497 CAM_Request 0 "Off" 1 "Rear view" 2 "Panorama view" 3 "Top view" 4 "BVM_Left" 5 "BVM_Right" 6 "Room mirror view" 7 "Invalid" ;
VAL_ 2470762497 HU_TempUnit 0 "Off" 1 "℃(Centigrade)" 2 "℉(Fahrenheit)" 3 "Invalid" ;
VAL_ 2470762497 AVN_RSPA_Disp_Rdy 0 "Impossible to display" 1 "Possible to display" 2 "Reserved" 3 "Invalid" ;
VAL_ 2470762497 CF_AVN_ProfileIDRValue 0 "Default" 1 "Guest" 2 "Profile 1" 3 "Profile 2" 4 "reserved" 5 "reserved" 6 "reserved" 7 "reserved" 8 "reserved" 9 "reserved" 10 "reserved" 11 "reserved" 12 "reserved" 13 "reserved" 14 "reserved" 15 "Invalid" ;
VAL_ 2470762497 HazardFromHUSVM 0 "inactive" 1 "active" 2 "reserved" 3 "invalid" ;
VAL_ 2470762497 OMUOSMirCtrl 0 "Off" 1 "Fold" 2 "Unfold" 3 "invalid" ;
VAL_ 2470762497 AVN_PDW_Input 0 "Init" 1 "No input" 2 "PDW softkey touch input" 3 "Invalid" ;
VAL_ 2470762497 AVN_RSPA_Input 0 "Init" 1 "No input" 2 "RSPA on request" 3 "Invalid" ;
VAL_ 2470762497 AVN_ParkingSW 0 "Released(off)" 1 "Pressed" 2 "Reserved" 3 "Reserved" 4 "Reserved" 5 "Reserved" 6 "Reserved" 7 "Invalid" ;
VAL_ 2470762497 OTAUIStatus 0 "Not Ready" 1 "Ready" 2 "Reserved" 3 "Invalid" ;
VAL_ 2470762497 C_TeleActiveStatus 0 "Active" 1 "Deactive" 2 "Reserved" 3 "Invalid" ;
VAL_ 2470762497 HU_AliveStatus 0 "Not Ready" 1 "On Mode" 2 "Head Unit Update Mode" 3 "Invalid" ;
VAL_ 2470762497 C_MtnAlertClu 0 "Activate" 1 "Deactivate" 2 "Reserved" 3 "Invalid" ;
VAL_ 2470762497 HU_RTCCheck 0 "Ready" 1 "Checking" 2 "Reserved" 3 "Invalid" ;
VAL_ 2470762497 C_SMKBindRequest 0 "Request Off" 1 "Request On" 2 "Reserved" 3 "Invalid" ;
VAL_ 2411985665 HU_MoodTherapyDrSeat 0 "Default" 1 "Off" 2 "On" 3 "Invalid" ;
VAL_ 2411985665 HU_VitalityFragrance 0 "Default" 1 "Off" 2 "On" 3 "Invalid" ;
VAL_ 2411985665 HU_VitalityCurtain 0 "Default" 1 "Off" 2 "On" 3 "Invalid" ;
VAL_ 2411985665 HU_DelightMoodLamp 0 "Default" 1 "Off" 2 "On" 3 "Invalid" ;
VAL_ 2411985665 HU_DelightFragrance 0 "Default" 1 "Off" 2 "On" 3 "Invalid" ;
VAL_ 2411985665 HU_DelightCurtain 0 "Default" 1 "Off" 2 "On" 3 "Invalid" ;
VAL_ 2411985665 HU_MoodTherapyPsSeat 0 "Default" 1 "Off" 2 "On" 3 "Invalid" ;
VAL_ 2411985665 HU_CareMoodLamp 0 "Default" 1 "Off" 2 "On" 3 "Invalid" ;
VAL_ 2411985665 HU_CareFragrance 0 "Default" 1 "Off" 2 "On" 3 "Invalid" ;
VAL_ 2411985665 HU_CareMassage 0 "Default" 1 "Off" 2 "On" 3 "Invalid" ;
VAL_ 2411985665 HU_CareCurtain 0 "Default" 1 "Off" 2 "On" 3 "Invalid" ;
VAL_ 2411985665 HU_ComfortMoodLamp 0 "Default" 1 "Off" 2 "On" 3 "Invalid" ;
VAL_ 2411985665 HU_ComfortFragrance 0 "Default" 1 "Off" 2 "On" 3 "Invalid" ;
VAL_ 2411985665 HU_ComfortMassage 0 "Default" 1 "Off" 2 "On" 3 "Invalid" ;
VAL_ 2411985665 HU_ComfortCurtain 0 "Default" 1 "Off" 2 "On" 3 "Invalid" ;
VAL_ 2411985665 HU_MoodTherapyMode 0 "Default" 1 "Off" 2 "Vitality" 3 "Delight" 4 "Care" 5 "Comfort" 6 "Reserved" 7 "Invalid" ;
VAL_ 2411985665 HU_MoodTherapyRlSeat 0 "Default" 1 "Off" 2 "On" 3 "Invalid" ;
VAL_ 2411985665 HU_MoodTherapyRrSeat 0 "Default" 1 "Off" 2 "On" 3 "Invalid" ;
VAL_ 2411985665 HU_VitalityMoodLamp 0 "Default" 1 "Off" 2 "On" 3 "Invalid" ;
VAL_ 2458167297 CF_AVN_FCANValueSet 0 "Default(None FCA)" 1 "Off" 2 "Warning" 3 "Assist" 4 "Reserved" 5 "Reserved" 6 "Reserved" 7 "Invalid" ;
VAL_ 2458167297 CF_AVN_DAWModeNValueSet 0 "Default" 1 "Off" 2 "Reserved" 3 "Normal" 4 "Early" 5 "Reserved" 6 "Reserved" 7 "Invalid" ;
VAL_ 2458167297 CF_AVN_HDANValueSet 0 "Default" 1 "Off" 2 "On" 3 "Invalid" ;
VAL_ 2458167297 CF_AVN_BCWNValueSet 0 "Default" 1 "Off" 2 "Warning" 3 "Invalid" ;
VAL_ 2458167297 CF_AVN_NSCCCamNValueSet 0 "Default" 1 "Disable" 2 "Enable" 3 "Invalid" ;
VAL_ 2458167297 CF_AVN_ProximitySesnsorSet 0 "Default" 1 "Off" 2 "On" 3 "Invalid" ;
VAL_ 2458167297 CF_AVN_BCANValueSet 0 "Default" 1 "Off" 2 "Warning" 3 "Assist" 4 "Reserved" 5 "Reserved" 6 "Reserved" 7 "Invalid" ;
VAL_ 2458167297 CF_AVN_ISLWNValueSet 0 "Default" 1 "Off" 2 "Warning" 3 "Invalid" ;
VAL_ 2458167297 CF_AVN_WarningTimingNValueSet 0 "Default" 1 "Late" 2 "Normal" 3 "Reserved" 4 "Reserved" 5 "Reserved" 6 "Reserved" 7 "Invalid" ;
VAL_ 2458167297 CF_AVN_LFANValueSet 0 "Default" 1 "Off" 2 "On" 3 "Invalid" ;
VAL_ 2458167297 CF_AVN_NCC_USM_set 0 "Default" 1 "On" 2 "Off" 3 "Invalid" ;
VAL_ 2458167297 CF_AVN_TirePressUnitNValueSet 0 "Default" 1 "Psi" 2 "Kpa" 3 "Bar" 4 "Reserved" 5 "Reserved" 6 "Reserved" 7 "Invalid" ;
VAL_ 2458167297 CF_AVN_PCANValueSet 0 "Default" 1 "Off" 2 "Warning" 3 "Assist" 4 "Reserved" 5 "Reserved" 6 "Reserved" 7 "Invalid" ;
VAL_ 2458167297 CF_AVN_TunnelClimateNvalueSet 0 "Default" 1 "Off" 2 "On" 3 "Invalid" ;
VAL_ 2458167297 CF_AVN_NSCCCrvNValueSet 0 "Default" 1 "Disable" 2 "Enable" 3 "Invalid" ;
VAL_ 2458167297 CF_AVN_BCWSndWanNValueSet 0 "Off" 1 "Disable" 2 "Enable" 3 "Invalid" ;
VAL_ 2458167297 CF_AVN_RCCWNValueSet 0 "Default" 1 "Off" 2 "Warning" 3 "Invalid" ;
VAL_ 2458167297 CF_AVN_LkaModeNValueSet 0 "Default" 1 "LDW mode" 2 "LKA" 3 "Reserved" 4 "LDW Only ON(None LKA)" 5 "LDW only OFF" 6 "LDW_LKA OFF" 7 "Invalid" ;
VAL_ 2458167297 CF_AVN_PasSpkrLvNValueSet 0 "Default" 1 "Level1" 2 "Level2" 3 "Level3" 4 "Reserved" 5 "Reserved" 6 "Reserved" 7 "Invalid" ;
VAL_ 2458167297 CF_AVN_PDWAutoOnNValueSet 0 "Default" 1 "Off" 2 "On" 3 "Invalid" ;
VAL_ 2458167297 C_TempUnit 0 "Default" 1 "Celsius" 2 "Fahrenheit" 3 "Invalid" ;
VAL_ 2458167297 CF_AVN_AdasVolumeNValueSet 0 "Default" 1 "Level 1" 2 "Level 2" 3 "Level 3" 4 "Reserved" 5 "Reserved" 6 "Off" 7 "Invalid" ;
VAL_ 2458167297 CF_AVN_SCCDrvModeNValueSet 0 "Default" 1 "Comfort" 2 "Normal" 3 "Dynamic" 4 "Reserved" 5 "Reserved" 6 "Reserved" 7 "Invalid" ;
VAL_ 1201 ICU_Update_Enable 0 "Default" 1 "Yes" 2 "No(SOC)" 3 "No(SOH)" 4 "No(Temp)" ;
VAL_ 715 RRPSS_L_WalkInSwitchSts 0 "Default" 1 "Off" 2 "On" 3 "Invalid" ;
VAL_ 715 RRPSS_L_AstRclFwdMvBtn 0 "Default" 1 "Off" 2 "On" 3 "Invalid" ;
VAL_ 715 RRPSS_L_AstRclBwdMvBtn 0 "Default" 1 "Off" 2 "On" 3 "Invalid" ;
VAL_ 715 RRPSS_L_AstSldFwdMvBtn 0 "Default" 1 "Off" 2 "On" 3 "Invalid" ;
VAL_ 715 RRPSS_L_AstSldBwdMvBtn 0 "Default" 1 "Off" 2 "On" 3 "Invalid" ;
VAL_ 715 RRPSS_L_AstHgtUpMvBtn 0 "Default" 1 "Off" 2 "On" 3 "Invalid" ;
VAL_ 715 RRPSS_L_AstHRestFwdMvBtn 0 "Default" 1 "Off" 2 "On" 3 "Invalid" ;
VAL_ 715 RRPSS_L_AstHgtDnMvBtn 0 "Default" 1 "Off" 2 "On" 3 "Invalid" ;
VAL_ 715 RRPSS_L_AstFRestOpenMvBtn 0 "Default" 1 "Off" 2 "On" 3 "Invalid" ;
VAL_ 715 RRPSS_L_AstFRestCloseMvBtn 0 "Default" 1 "Off" 2 "On" 3 "Invalid" ;
VAL_ 715 RRPSS_L_AstHRestBwdMvBtn 0 "Default" 1 "Off" 2 "On" 3 "Invalid" ;
VAL_ 715 RRPSS_L_AstHRestUpMvBtn 0 "Default" 1 "Off" 2 "On" 3 "Invalid" ;
VAL_ 715 RRPSS_L_AstHRestDnMvBtn 0 "Default" 1 "Off" 2 "On" 3 "Invalid" ;
VAL_ 2164277249 TCU_GearSlctDis 0 "P" 1 "L" 2 "2" 3 "3" 4 "DS Mode" 5 "D" 6 "N" 7 "R" 8 "sports mode / manual shift / paddle shift" 9 "Not Display at Cluster" 10 "Sub-Rom Communication" 11 "Sub-Rom Communication Error" 12 "Paddle shift (D-position)" 13 "Reserved" 14 "Intermediate Position" 15 "fault" ;
VAL_ 2164277249 TCU_Typ 0 "Reserved" 1 "Step A" 2 "CVT" 3 "DCT" 4 "AMT" 5 "eClutch (2pedal)" 6 "eClutch (3pedal)" ;
VAL_ 2164277249 TCU_TqRdctnVal 0 "Max. reduction" 2047 "No reduction" ;
VAL_ 2164277249 TCU_GearStepTyp 3 "3 - Speed AT or DCT" 4 "4 - Speed AT or DCT" 5 "5 - Speed AT or DCT" 6 "6 - Speed AT or DCT" 7 "7- Speed AT or DCT" 8 "8 - Speed AT or DCT" ;
VAL_ 2164277249 TCU_GearShftSta 0 "no gear change" 1 "gear change is active" 2 "Not used" 3 "Error Indicator" ;
VAL_ 2164277249 TCU_TqCnvrtrSta 0 "No lock up control" 1 "Slip lock up" 2 "Fully lock up" 3 "Off slip lock up" ;
VAL_ 2164277252 TCU_NetrlCtrlSta 0 "No NC" 1 "NC Entry" 2 "NC Applied" 3 "NC Exit" ;
VAL_ 2164277252 TCU_ShftPtrnSta 0 "Normal (ECO)" 1 "Uphill 1 (Optional)" 2 "Uphill 2 (Optional)" 3 "Reserved" 4 "Downhill 1 (Optional)" 5 "Cruise (Optional)" 6 "Cruise_Uphill 1 (Optional)" 7 "Cruise_Uphill 2 (Optional)" 8 "Active ECO (Optional)" 9 "Sport Drive (Optional)" 15 "None of the above" ;
VAL_ 2164277252 TCU_EPBReq 0 "No Request (default)" 1 "EPB Request" ;
VAL_ 2164277252 TCU_VgisInhbtReq 0 "There’s no request from TCU" 1 "TCU inhibits ECU from changing VGIS status" 2 "Not used" 3 "Error Indicator" ;
VAL_ 2164277252 TCU_EngTqIncReqVal 0 "No request" 2047 "Max. Increase" ;
VAL_ 2189467649 WHL_PlsFLVal 255 "Error" ;
VAL_ 2189467649 WHL_PlsFRVal 255 "Error" ;
VAL_ 2189467649 WHL_PlsRLVal 255 "Error" ;
VAL_ 2189467649 WHL_PlsRRVal 255 "Error" ;
VAL_ 2189467649 WHL_DirFLVal 0 "Unknown (Wheel moving stop state or Not applied wheel sensor for direction)" 1 "Forward direction" 2 "Backward direction" 3 "Error identifier" ;
VAL_ 2189467649 WHL_DirFRVal 0 "Unknown (Wheel moving stop state or Not applied wheel sensor for direction)" 1 "Forward direction" 2 "Backward direction" 3 "Error identifier" ;
VAL_ 2189467649 WHL_DirRLVal 0 "Unknown (Wheel moving stop state or Not applied wheel sensor for direction)" 1 "Forward direction" 2 "Backward direction" 3 "Error identifier" ;
VAL_ 2189467649 WHL_DirRRVal 0 "Unknown (Wheel moving stop state or Not applied wheel sensor for direction)" 1 "Forward direction" 2 "Backward direction" 3 "Error identifier" ;
VAL_ 2189467650 WHL_SpdFLVal 16383 "Error" ;
VAL_ 2189467650 WHL_SpdFRVal 16383 "Error" ;
VAL_ 2189467650 WHL_SpdRLVal 16383 "Error" ;
VAL_ 2189467650 WHL_SpdRRVal 16383 "Error" ;
